VERSION ""

NS_ :

BS_:

BU_: APIM_CISM FCIMB RACM_RCIM DSP WCM DACMC HUD_ADV TRM_ITRM ACM GWM _delete APIM IPC GENERIC TSTR

BO_ 531 DesiredTorqBrk_HS3: 8 GWM
 SG_ VehStop_D_Stat : 28|2@0+ (1,0) [0|3] "SED"  GENERIC
 SG_ TracCtlPtActv_B_Actl : 31|1@0+ (1,0) [0|1] "SED"  GENERIC
 SG_ PrkBrkYwLamp_D_Rq : 38|2@0+ (1,0) [0|3] "SED"  IPC
 SG_ PrkBrkRedLamp_D_Rq : 30|2@0+ (1,0) [0|3] "SED"  IPC
 SG_ PrkBrkMsgTxt_D_Rq : 36|4@0+ (1,0) [0|15] "SED"  IPC
 SG_ PrkBrkStatus : 26|3@0+ (1,0) [0|7] "SED"  APIM_CISM,APIM
 SG_ LscmbbMntr_B_Err : 17|1@0+ (1,0) [0|1] "SED"  APIM,APIM_CISM,IPC
 SG_ LscmbbBrkDis_B_Actl : 19|1@0+ (1,0) [0|1] "SED"  GENERIC
 SG_ StabCtlBrkActv_B_Actl : 23|1@0+ (1,0) [0|1] "SED"  APIM_CISM,APIM
 SG_ CmbbBrkPrchg_B_Actl : 59|1@0+ (1,0) [0|1] "SED"  TRM_ITRM
 SG_ CmbbBrkDecel_B_Actl : 58|1@0+ (1,0) [0|1] "SED"  TRM_ITRM
 SG_ CmbbBaSensInc_B_Actl : 57|1@0+ (1,0) [0|1] "SED"  GENERIC
 SG_ AccBrkWarm_B_Actl : 63|1@0+ (1,0) [0|1] "SED"  GENERIC
 SG_ AccBrkTotTqMn_B_Actl : 62|1@0+ (1,0) [0|1] "SED"  TRM_ITRM
 SG_ AccBrkPrchgActv_B_Actl : 61|1@0+ (1,0) [0|1] "SED"  GENERIC
 SG_ AccBrkDis_B_Actl : 44|1@0+ (1,0) [0|1] "SED"  GENERIC
 SG_ AccBrkDeny_B_Actl : 42|1@0+ (1,0) [0|1] "SED"  GENERIC
 SG_ AccBrkActv_B_Actl : 43|1@0+ (1,0) [0|1] "SED"  GENERIC
 SG_ PrplDrgCtlActv_B_Actl : 46|1@0+ (1,0) [0|1] "SED"  GENERIC
 SG_ PrplWhlTot_Tq_RqMx : 7|16@0+ (4,-131072) [-131072|131068] "Nm"  GENERIC
 SG_ AbsActv_B_Actl : 45|1@0+ (1,0) [0|1] "SED"  APIM_CISM,APIM,TRM_ITRM
 SG_ CmbbBrkDis_B_Actl : 56|1@0+ (1,0) [0|1] "SED"  GENERIC
 SG_ CmbbDeny_B_ActlBrk : 60|1@0+ (1,0) [0|1] "SED"  GENERIC
 SG_ CcDis_B_Cmd : 47|1@0+ (1,0) [0|1] "SED"  GENERIC
 SG_ VehLongOvrGnd_A_Est : 41|10@0+ (0.035,-17.9) [-17.9|17.835] "m/s^2"  TRM_ITRM
 SG_ AccStopActv_B_ActlBrk : 22|1@0+ (1,0) [0|1] "SED"  GENERIC
 SG_ AccDis_B_ActlEpb : 32|1@0+ (1,0) [0|1] "SED"  GENERIC
 SG_ LscmbbDeny_B_ActlBrk : 18|1@0+ (1,0) [0|1] "SED"  GENERIC
 SG_ LscmbbBrkDecel_B_Actl : 20|1@0+ (1,0) [0|1] "SED"  GENERIC
 SG_ LscmbbBaSensInc_B_Actl : 21|1@0+ (1,0) [0|1] "SED"  GENERIC
 SG_ LscmbBrkPrchg_B_Actl : 16|1@0+ (1,0) [0|1] "SED"  GENERIC
 SG_ VehicleStationary : 39|1@0+ (1,0) [0|1] "SED"  GENERIC

BO_ 702 PHONE_MC_WORD_Rx: 8 IPC
 SG_ PHONE_MC_WORD_Rx : 7|64@0+ (1,0) [0|1.84467440737096E+019] "unitless"  APIM_CISM,APIM

BO_ 711 MyKeySrvr_MyKeyClient_Word: 8 IPC
 SG_ MyKeySrvr_Clnt_Word_Tx : 7|64@0+ (1,0) [0|1.84467440737096E+019] "unitless"  APIM_CISM,APIM

BO_ 549 IPC_Infotainment: 8 IPC
 SG_ CCOI_PolicyClient_St2 : 45|4@0+ (1,0) [0|15] "SED"  GWM
 SG_ FactoryReset_Rq2 : 18|1@0+ (1,0) [0|1] "SED"  GWM
 SG_ NavIod_D_Rq : 55|3@0+ (1,0) [0|7] "SED"  APIM_CISM
 SG_ WwaActv_B_Stat : 46|1@0+ (1,0) [0|1] "SED"  APIM_CISM,GWM,ACM,APIM
 SG_ StrtInGearOk_D_Stat : 17|2@0+ (1,0) [0|3] "SED"  GWM
 SG_ Veh_V2_Dsply : 39|9@0+ (1,0) [0|511] "unitless"  APIM_CISM,APIM,GWM,HUD_ADV
 SG_ IPC_MyKeyVolLimit_St : 9|2@0+ (1,0) [0|3] "SED"  APIM_CISM,GWM,APIM,DSP,ACM
 SG_ HudVertSzMnuOn_B_Rq : 21|1@0+ (1,0) [0|1] "SED"  GWM,HUD_ADV
 SG_ HudVertMnuOn_B_Rq : 11|1@0+ (1,0) [0|1] "SED"  GWM,HUD_ADV
 SG_ HudRotatMnuOn_B_Rq : 22|1@0+ (1,0) [0|1] "SED"  GWM,HUD_ADV
 SG_ HudCntntMnuOn_B_Rq : 20|1@0+ (1,0) [0|1] "SED"  GWM,HUD_ADV
 SG_ HudBrightMnuOn_B_Rq : 1|1@0+ (1,0) [0|1] "SED"  GWM,HUD_ADV
 SG_ HdcOn_B_Rq : 19|1@0+ (1,0) [0|1] "SED"  GWM
 SG_ IPC_Attn_Info_Audio : 4|3@0+ (1,0) [0|7] "SED"  APIM_CISM,GWM,APIM,DSP,ACM
 SG_ BeltminderAudioMute : 6|2@0+ (1,0) [0|3] "SED"  APIM_CISM,GWM,APIM,DSP,ACM
 SG_ Power_Up_Chime_Modules : 23|1@0+ (1,0) [0|1] "SED"  APIM_CISM,GWM,DSP,ACM
 SG_ Chime_Source : 15|2@0+ (1,0) [0|3] "SED"  APIM_CISM,GWM,DSP,ACM
 SG_ IPC_New_Attn_Event : 0|1@0+ (1,0) [0|1] "SED"  APIM_CISM,GWM,APIM,DSP,ACM
 SG_ MetricActv_B_Dsply : 7|1@0+ (1,0) [0|1] "SED"  GWM,HUD_ADV,GENERIC

BO_ 765 Mc_Send_Signals_2: 8 IPC
 SG_ BalrSwtch_D_Stat : 57|2@0+ (1,0) [0|3] "SED"  GWM
 SG_ BalrMde_D_Rq : 59|2@0+ (1,0) [0|3] "SED"  GWM
 SG_ RstrnOnPsngr_D_RqMnu : 63|4@0+ (1,0) [0|15] "SED"  GWM
 SG_ WaitToStartLamp_D_Falt : 50|2@0+ (1,0) [0|3] "SED"  GWM
 SG_ EsaOn_B_Rq : 15|1@0+ (1,0) [0|1] "SED"  GWM
 SG_ BttOn_B_Rq : 26|1@0+ (1,0) [0|1] "SED"  GWM
 SG_ Btt_L_Actl : 39|7@0+ (0.1,0) [0|12.5] "meter"  GWM
 SG_ RearDiffLck_D_RqArb : 25|2@0+ (1,0) [0|3] "SED"  GWM
 SG_ AwdMde_D_RqArb : 47|3@0+ (1,0) [0|7] "SED"  GWM
 SG_ SelDrvMdeTxtReset_B_Rq : 40|1@0+ (1,0) [0|1] "SED"  GWM
 SG_ AutoTowAllw_D_RqMnu : 52|2@0+ (1,0) [0|3] "SED"  GWM
 SG_ DrvInputRequired_B_Rq : 32|1@0+ (1,0) [0|1] "SED"  GWM
 SG_ SelDrvMdeDsply_B_Avail : 41|1@0+ (1,0) [0|1] "SED"  GWM
 SG_ EngExhMdeQuiet_D_Rq : 17|2@0+ (1,0) [0|3] "SED"  GWM
 SG_ AirSusp_D_RqDrv : 31|2@0+ (1,0) [0|3] "SED"  GWM
 SG_ Mc_VehUntTrpCoUsrSel_St : 23|1@0+ (1,0) [0|1] "SED"  APIM_CISM,HUD_ADV,APIM,GWM
 SG_ Mc_VehUnitTempUsrSel_St : 22|1@0+ (1,0) [0|1] "SED"  APIM_CISM,HUD_ADV,APIM,RACM_RCIM,GWM
 SG_ Mc_VehDayNightUsrSel_St : 14|3@0+ (1,0) [0|7] "SED"  APIM_CISM,GWM,APIM,ACM
 SG_ Mc_VehTimeFrmtUsrSel_St : 1|2@0+ (1,0) [0|3] "SED"  APIM_CISM,GWM,HUD_ADV,APIM,RACM_RCIM,GENERIC
 SG_ Mc_VehThemeUsrSel_St : 11|4@0+ (1,0) [0|15] "SED"  APIM_CISM,GWM,APIM,GENERIC
 SG_ Mc_VehLangUsrSel_St : 7|6@0+ (1,0) [0|63] "SED"  APIM_CISM,HUD_ADV,APIM,ACM,GWM
 SG_ AwdRnge_D_ActlIpc : 29|3@0+ (1,0) [0|7] "SED"  GWM
 SG_ AwdDrvMde_D_Rq : 44|3@0+ (1,0) [0|7] "SED"  GWM
 SG_ EngExhMdeQuiet_D2_Rq : 55|3@0+ (1,0) [0|7] "SED"  GWM
 SG_ BrkLineLck_D_Rq : 19|2@0+ (1,0) [0|3] "SED"  GWM
 SG_ EdmSailMde_B_RqDrv : 48|1@0+ (1,0) [0|1] "SED"  GWM
 SG_ Running_Board_Cmd : 21|2@0+ (1,0) [0|3] "SED"  GWM

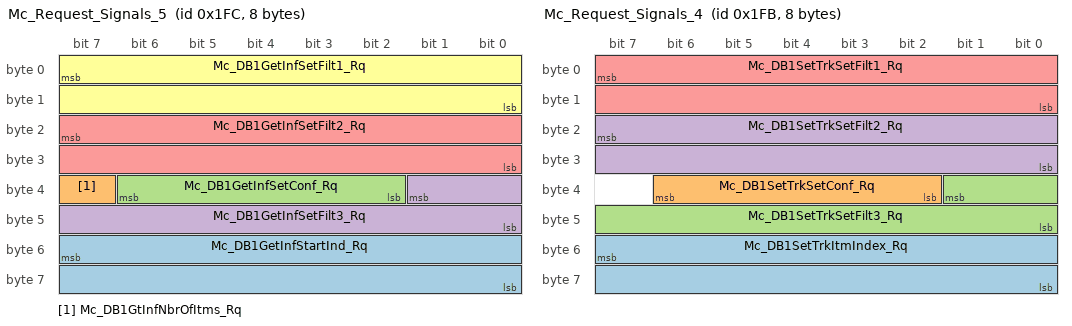
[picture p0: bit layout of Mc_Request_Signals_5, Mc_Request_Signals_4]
BO_ 508 Mc_Request_Signals_5: 8 IPC
 SG_ Mc_DB1GetInfStartInd_Rq : 55|16@0+ (1,0) [0|65535] "unitless"  ACM,APIM_CISM
 SG_ Mc_DB1GtInfNbrOfItms_Rq : 39|1@0+ (1,0) [0|1] "SED"  ACM,APIM_CISM
 SG_ Mc_DB1GetInfSetConf_Rq : 38|5@0+ (1,0) [0|31] "SED"  ACM,APIM_CISM
 SG_ Mc_DB1GetInfSetFilt3_Rq : 33|10@0+ (1,0) [0|1023] "unitless"  ACM,APIM_CISM
 SG_ Mc_DB1GetInfSetFilt2_Rq : 23|16@0+ (1,0) [0|65535] "unitless"  ACM,APIM_CISM
 SG_ Mc_DB1GetInfSetFilt1_Rq : 7|16@0+ (1,0) [0|65535] "unitless"  ACM,APIM_CISM

BO_ 507 Mc_Request_Signals_4: 8 IPC
 SG_ Mc_DB1SetTrkItmIndex_Rq : 55|16@0+ (1,0) [0|65535] "unitless"  ACM,APIM_CISM
 SG_ Mc_DB1SetTrkSetConf_Rq : 38|5@0+ (1,0) [0|31] "SED"  ACM,APIM_CISM
 SG_ Mc_DB1SetTrkSetFilt3_Rq : 33|10@0+ (1,0) [0|1023] "unitless"  ACM,APIM_CISM
 SG_ Mc_DB1SetTrkSetFilt2_Rq : 23|16@0+ (1,0) [0|65535] "unitless"  ACM,APIM_CISM
 SG_ Mc_DB1SetTrkSetFilt1_Rq : 7|16@0+ (1,0) [0|65535] "unitless"  ACM,APIM_CISM

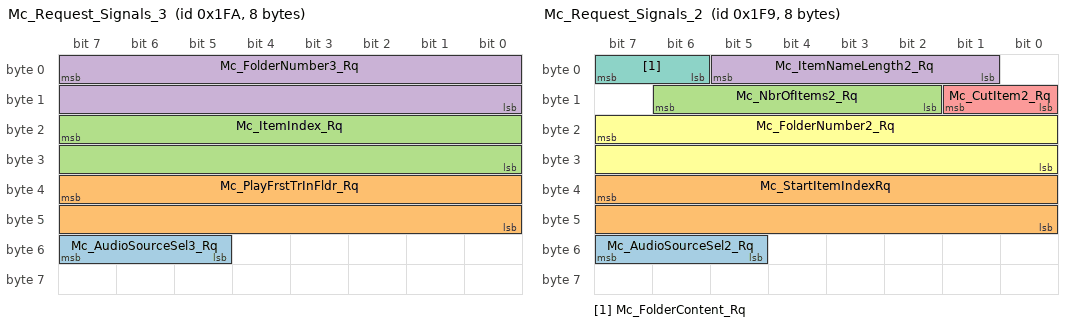
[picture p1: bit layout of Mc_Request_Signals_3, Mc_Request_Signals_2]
BO_ 506 Mc_Request_Signals_3: 8 IPC
 SG_ Mc_AudioSourceSel3_Rq : 55|3@0+ (1,0) [0|7] "SED"  ACM,APIM_CISM
 SG_ Mc_PlayFrstTrInFldr_Rq : 39|16@0+ (1,0) [0|65535] "unitless"  ACM,APIM_CISM
 SG_ Mc_ItemIndex_Rq : 23|16@0+ (1,0) [0|65535] "unitless"  ACM,APIM_CISM
 SG_ Mc_FolderNumber3_Rq : 7|16@0+ (1,0) [0|65535] "unitless"  ACM,APIM_CISM

BO_ 505 Mc_Request_Signals_2: 8 IPC
 SG_ Mc_AudioSourceSel2_Rq : 55|3@0+ (1,0) [0|7] "SED"  ACM,APIM_CISM
 SG_ Mc_StartItemIndexRq : 39|16@0+ (1,0) [0|65535] "unitless"  ACM,APIM_CISM
 SG_ Mc_NbrOfItems2_Rq : 14|5@0+ (1,0) [0|20] "SED"  ACM,APIM_CISM
 SG_ Mc_ItemNameLength2_Rq : 5|5@0+ (1,0) [0|20] "SED"  ACM,APIM_CISM
 SG_ Mc_CutItem2_Rq : 9|2@0+ (1,0) [0|3] "SED"  ACM,APIM_CISM
 SG_ Mc_FolderNumber2_Rq : 23|16@0+ (1,0) [0|65535] "unitless"  ACM,APIM_CISM
 SG_ Mc_FolderContent_Rq : 7|2@0+ (1,0) [0|3] "SED"  ACM,APIM_CISM

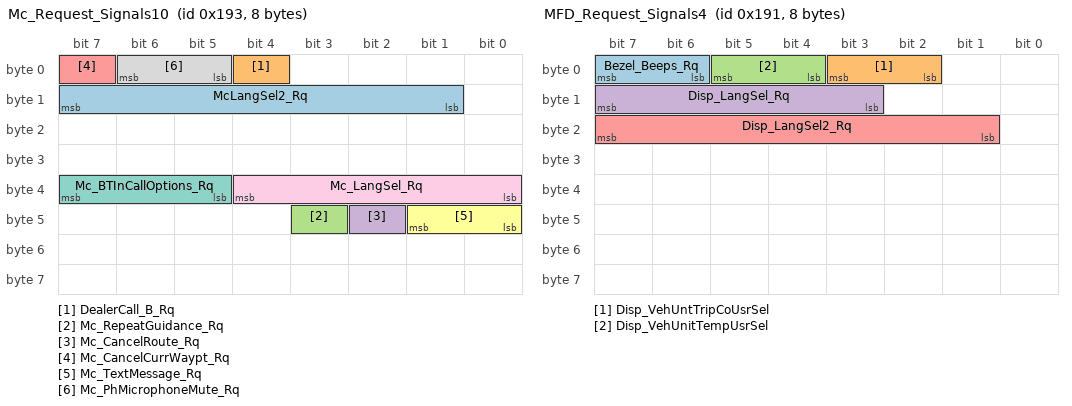
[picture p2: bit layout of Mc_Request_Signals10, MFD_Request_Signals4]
BO_ 403 Mc_Request_Signals10: 8 IPC
 SG_ McLangSel2_Rq : 15|7@0+ (1,0) [0|7] "SED"  APIM_CISM,APIM
 SG_ DealerCall_B_Rq : 4|1@0+ (1,0) [0|1] "SED"  APIM_CISM,APIM
 SG_ Mc_RepeatGuidance_Rq : 43|1@0+ (1,0) [0|1] "SED"  APIM_CISM,APIM
 SG_ Mc_CancelRoute_Rq : 42|1@0+ (1,0) [0|1] "SED"  APIM_CISM,APIM
 SG_ Mc_CancelCurrWaypt_Rq : 7|1@0+ (1,0) [0|1] "SED"  APIM_CISM,APIM
 SG_ Mc_TextMessage_Rq : 41|2@0+ (1,0) [0|3] "SED"  APIM_CISM,APIM
 SG_ Mc_BTInCallOptions_Rq : 39|3@0+ (1,0) [0|7] "SED"  APIM_CISM,APIM
 SG_ Mc_PhMicrophoneMute_Rq : 6|2@0+ (1,0) [0|3] "SED"  APIM_CISM,APIM
 SG_ Mc_LangSel_Rq : 36|5@0+ (1,0) [0|31] "SED"  APIM_CISM,APIM

BO_ 401 MFD_Request_Signals4: 8 APIM
 SG_ Bezel_Beeps_Rq : 7|2@0+ (1,0) [0|3] "SED"  FCIMB,GWM
 SG_ Disp_VehUntTripCoUsrSel : 3|2@0+ (1,0) [0|3] "SED"  IPC
 SG_ Disp_VehUnitTempUsrSel : 5|2@0+ (1,0) [0|3] "SED"  IPC
 SG_ Disp_LangSel_Rq : 15|5@0+ (1,0) [0|31] "SED"  IPC
 SG_ Disp_LangSel2_Rq : 23|7@0+ (1,0) [0|127] "SED"  IPC

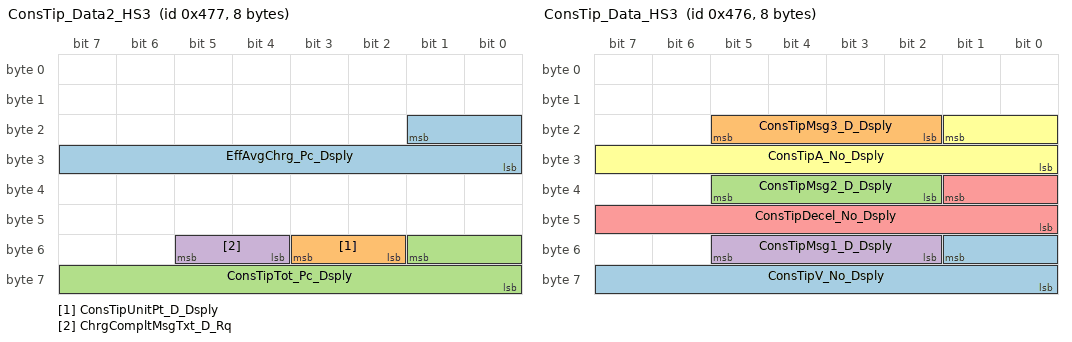
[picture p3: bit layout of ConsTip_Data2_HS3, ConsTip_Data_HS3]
BO_ 1143 ConsTip_Data2_HS3: 8 GWM
 SG_ EffAvgChrg_Pc_Dsply : 17|10@0+ (0.1,0) [0|102.3] "percent"  IPC
 SG_ ConsTipUnitPt_D_Dsply : 51|2@0+ (1,0) [0|3] "SED"  APIM_CISM,IPC,APIM
 SG_ ConsTipTot_Pc_Dsply : 49|10@0+ (0.1,0) [0|102.1] "percent"  IPC
 SG_ ChrgCompltMsgTxt_D_Rq : 53|2@0+ (1,0) [0|3] "SED"  APIM_CISM,APIM,IPC

BO_ 1142 ConsTip_Data_HS3: 8 GWM
 SG_ ConsTipV_No_Dsply : 49|10@0+ (0.1,0) [0|102.1] "percent"  APIM_CISM,IPC,APIM
 SG_ ConsTipMsg3_D_Dsply : 21|4@0+ (1,0) [0|15] "SED"  APIM_CISM,IPC,APIM
 SG_ ConsTipMsg2_D_Dsply : 37|4@0+ (1,0) [0|15] "SED"  APIM_CISM,IPC,APIM
 SG_ ConsTipMsg1_D_Dsply : 53|4@0+ (1,0) [0|15] "SED"  APIM_CISM,IPC,APIM
 SG_ ConsTipDecel_No_Dsply : 33|10@0+ (0.1,0) [0|102.1] "percent"  APIM_CISM,IPC,APIM
 SG_ ConsTipA_No_Dsply : 17|10@0+ (0.1,0) [0|102.1] "percent"  APIM_CISM,IPC,APIM

BO_ 947 OutsideAirTempStat: 8 GWM
 SG_ Outside_Air_Temp_Stat_UB : 48|1@0+ (1,0) [0|1] "SED"  HUD_ADV,APIM_CISM,APIM,WCM,IPC
 SG_ Outside_Air_Temp_Stat : 39|8@0+ (0.5,-40) [-40|86.5] "Degrees C"  HUD_ADV,APIM_CISM,APIM,WCM,IPC

BO_ 973 Traffic_RecogitionData_HS3: 8 GWM
 SG_ PersCtaSplitView_D_Stat : 12|2@0+ (1,0) [0|3] "SED"  APIM
 SG_ LaSysOffStat_D_Dsply : 58|2@0+ (1,0) [0|3] "SED"  IPC
 SG_ TsrVl1RstrcMsgTxt2_D_Rq : 51|3@0+ (1,0) [0|7] "SED"  HUD_ADV,IPC
 SG_ TsrVl2RstrcMsgTxt2_D_Rq : 63|3@0+ (1,0) [0|7] "SED"  HUD_ADV,IPC
 SG_ TsrVl2PrmntMsgTxt_D_Rq : 60|2@0+ (1,0) [0|3] "SED"  HUD_ADV,IPC
 SG_ TsrVl1PrmntMsgTxt_D_Rq : 41|2@0+ (1,0) [0|3] "SED"  HUD_ADV,IPC
 SG_ TsrOvtkMsgTxt2_D_Rq : 55|4@0+ (1,0) [0|15] "SED"  HUD_ADV,IPC
 SG_ WwaWarn_B_Rq : 48|1@0+ (1,0) [0|1] "SED"  HUD_ADV,IPC
 SG_ TsrVlUnitMsgTxt_D_Rq : 43|2@0+ (1,0) [0|3] "SED"  APIM_CISM,HUD_ADV,APIM,IPC
 SG_ TsrVLim2MsgTxt_D_Rq : 39|8@0+ (1,0) [0|255] "SED"  HUD_ADV,IPC
 SG_ TsrVLim1MsgTxt_D_Rq : 31|8@0+ (1,0) [0|255] "SED"  HUD_ADV,IPC
 SG_ TsrVl2StatMsgTxt_D_Rq : 47|2@0+ (1,0) [0|3] "SED"  HUD_ADV,IPC
 SG_ TsrVl2RstrcMsgTxt_D_Rq : 17|2@0+ (1,0) [0|3] "SED"  HUD_ADV,IPC
 SG_ TsrVl1StatMsgTxt_D_Rq : 21|2@0+ (1,0) [0|3] "SED"  HUD_ADV,IPC
 SG_ TsrVl1RstrcMsgTxt_D_Rq : 23|2@0+ (1,0) [0|3] "SED"  IPC
 SG_ TsrStatMsgTxt_D_Rq : 10|3@0+ (1,0) [0|7] "SED"  IPC
 SG_ TsrOvtkStatMsgTxt_D_Rq : 1|2@0+ (1,0) [0|3] "SED"  HUD_ADV,IPC
 SG_ TsrOvtkMsgTxt_D_Rq : 15|3@0+ (1,0) [0|7] "SED"  HUD_ADV,IPC
 SG_ TsrOswWarnMsgTxt_D_Rq : 3|2@0+ (1,0) [0|3] "SED"  HUD_ADV,IPC
 SG_ TsrMsgTxt_D_Rq : 7|4@0+ (1,0) [0|15] "SED"  IPC

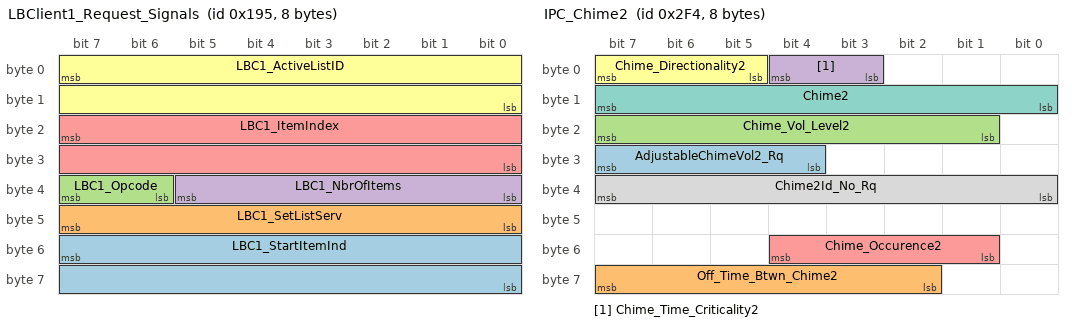
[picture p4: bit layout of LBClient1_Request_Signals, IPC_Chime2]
BO_ 405 LBClient1_Request_Signals: 8 IPC
 SG_ LBC1_StartItemInd : 55|16@0+ (1,0) [0|65535] "unitless"  APIM_CISM,ACM,APIM
 SG_ LBC1_SetListServ : 47|8@0+ (1,0) [0|255] "unitless"  APIM_CISM,ACM,APIM
 SG_ LBC1_Opcode : 39|2@0+ (1,0) [0|3] "SED"  APIM_CISM,ACM,APIM
 SG_ LBC1_NbrOfItems : 37|6@0+ (1,0) [0|63] "unitless"  APIM_CISM,ACM,APIM
 SG_ LBC1_ItemIndex : 23|16@0+ (1,0) [0|65535] "unitless"  APIM_CISM,ACM,APIM
 SG_ LBC1_ActiveListID : 7|16@0+ (1,0) [0|65535] "unitless"  APIM_CISM,APIM,ACM

BO_ 756 IPC_Chime2: 8 IPC
 SG_ AdjustableChimeVol2_Rq : 31|4@0+ (1,0) [0|15] "SED"  APIM_CISM,ACM,DSP
 SG_ Off_Time_Btwn_Chime2 : 63|6@0+ (1,0) [0|52] "unitless"  APIM_CISM,ACM,DSP
 SG_ Chime_Vol_Level2 : 23|7@0+ (1,0) [0|127] "unitless"  APIM_CISM,ACM,DSP
 SG_ Chime_Time_Criticality2 : 4|2@0+ (1,0) [0|3] "SED"  APIM_CISM,ACM,DSP
 SG_ Chime_Occurence2 : 52|4@0+ (1,0) [0|15] "SED"  APIM_CISM,ACM,DSP
 SG_ Chime_Directionality2 : 7|3@0+ (1,0) [0|7] "SED"  APIM_CISM,ACM,DSP
 SG_ Chime2 : 15|8@0+ (1,0) [0|255] "unitless"  APIM_CISM,ACM,DSP
 SG_ Chime2Id_No_Rq : 39|8@0+ (1,0) [0|255] "SED"  APIM_CISM,DSP,ACM

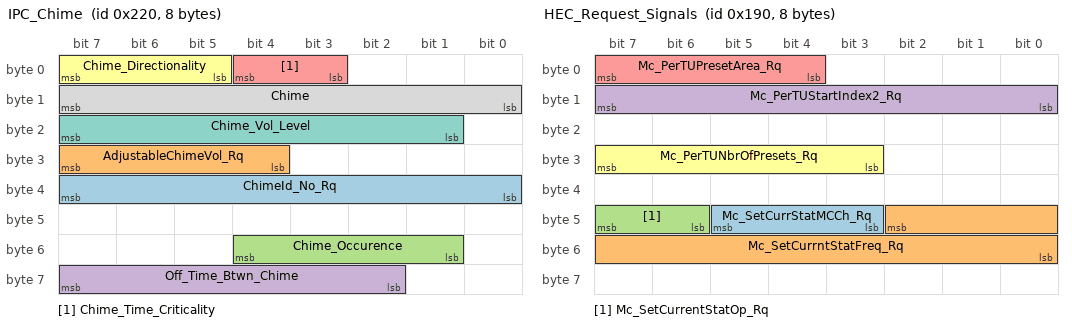
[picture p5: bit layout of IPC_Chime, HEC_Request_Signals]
BO_ 544 IPC_Chime: 8 IPC
 SG_ ChimeId_No_Rq : 39|8@0+ (1,0) [0|255] "SED"  APIM_CISM,ACM
 SG_ AdjustableChimeVol_Rq : 31|4@0+ (1,0) [0|15] "SED"  APIM_CISM,ACM,DSP
 SG_ Chime_Occurence : 52|4@0+ (1,0) [0|15] "SED"  APIM_CISM,DSP,ACM
 SG_ Off_Time_Btwn_Chime : 63|6@0+ (1,0) [0|52] "unitless"  APIM_CISM,DSP,ACM
 SG_ Chime_Time_Criticality : 4|2@0+ (1,0) [0|3] "SED"  APIM_CISM,DSP,ACM
 SG_ Chime_Directionality : 7|3@0+ (1,0) [0|7] "SED"  APIM_CISM,DSP,ACM
 SG_ Chime_Vol_Level : 23|7@0+ (1,0) [0|127] "unitless"  APIM_CISM,DSP,ACM
 SG_ Chime : 15|8@0+ (1,0) [0|255] "unitless"  APIM_CISM,DSP,ACM

BO_ 291 HEC_Response_Signals: 8 IPC
 SG_ LangUpdate_Rsp : 7|2@0+ (1,0) [0|3] "SED"  APIM_CISM,APIM

BO_ 400 HEC_Request_Signals: 8 IPC
 SG_ Mc_SetCurrStatMCCh_Rq : 45|3@0+ (1,0) [0|7] "SED"  ACM,APIM_CISM
 SG_ Mc_SetCurrntStatFreq_Rq : 42|11@0+ (1,0) [0|1557] "unitless"  ACM,APIM_CISM
 SG_ Mc_SetCurrentStatOp_Rq : 47|2@0+ (1,0) [0|3] "SED"  ACM,APIM_CISM
 SG_ Mc_PerTUStartIndex2_Rq : 15|8@0+ (1,0) [0|255] "unitless"  ACM,APIM_CISM,APIM
 SG_ Mc_PerTUPresetArea_Rq : 7|4@0+ (1,0) [0|15] "SED"  ACM,APIM_CISM,APIM
 SG_ Mc_PerTUNbrOfPresets_Rq : 31|5@0+ (1,0) [0|31] "SED"  ACM,APIM_CISM,APIM

BO_ 647 HEC_DispDimm: 8 IPC
 SG_ HEC_BTIncomingCall_Rq : 23|2@0+ (1,0) [0|3] "SED"  APIM_CISM,APIM
 SG_ HEC_BTEndTelService_Rq : 3|2@0+ (1,0) [0|3] "SED"  APIM_CISM,APIM

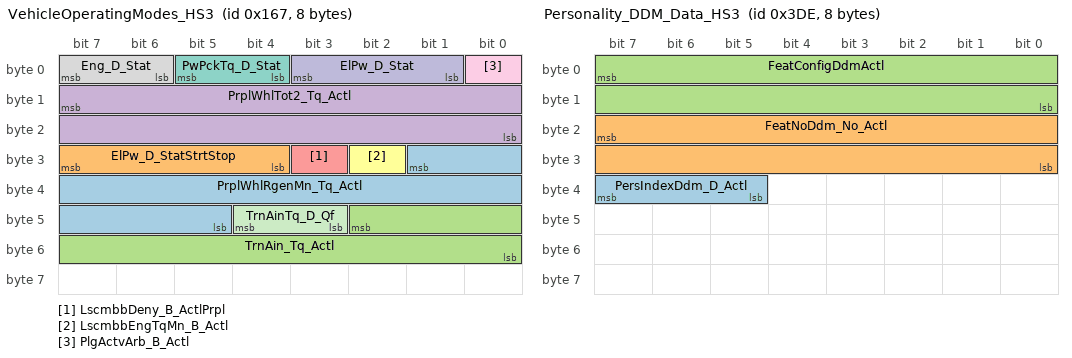
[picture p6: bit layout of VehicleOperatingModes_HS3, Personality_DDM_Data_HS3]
BO_ 359 VehicleOperatingModes_HS3: 8 GWM
 SG_ PrplWhlRgenMn_Tq_Actl : 25|13@0+ (4,-16380) [-16380|16380] "Nm"  GENERIC
 SG_ ElPw_D_StatStrtStop : 31|4@0+ (1,0) [0|15] "SED"  GENERIC
 SG_ TrnAin_Tq_Actl : 42|11@0+ (1,-500) [-500|1547] "Nm"  APIM_CISM,DACMC,IPC,APIM,ACM
 SG_ PrplWhlTot2_Tq_Actl : 15|16@0+ (4,-131072) [-131072|131060] "Nm"  APIM_CISM,APIM,IPC
 SG_ LscmbbDeny_B_ActlPrpl : 27|1@0+ (1,0) [0|1] "SED"  GENERIC
 SG_ LscmbbEngTqMn_B_Actl : 26|1@0+ (1,0) [0|1] "SED"  GENERIC
 SG_ PwPckTq_D_Stat : 5|2@0+ (1,0) [0|3] "SED"  HUD_ADV,APIM_CISM,RACM_RCIM,TRM_ITRM,DACMC,APIM,DSP,ACM,WCM,IPC
 SG_ Eng_D_Stat : 7|2@0+ (1,0) [0|3] "SED"  APIM_CISM,RACM_RCIM,TRM_ITRM,APIM,WCM,DSP,ACM
 SG_ PlgActvArb_B_Actl : 0|1@0+ (1,0) [0|1] "SED"  IPC
 SG_ ElPw_D_Stat : 3|3@0+ (1,0) [0|7] "SED"  APIM_CISM,RACM_RCIM,DSP,TRM_ITRM,DACMC,HUD_ADV,APIM,ACM,IPC
 SG_ TrnAinTq_D_Qf : 44|2@0+ (1,0) [0|3] "SED"  APIM_CISM,DACMC,ACM

BO_ 990 Personality_DDM_Data_HS3: 8 GWM
 SG_ PersIndexDdm_D_Actl : 39|3@0+ (1,0) [0|7] "SED"  APIM_CISM,APIM,IPC
 SG_ FeatNoDdm_No_Actl : 23|16@0+ (1,0) [0|65535] "Number"  APIM_CISM,APIM,IPC
 SG_ FeatConfigDdmActl : 7|16@0+ (1,0) [0|65535] "Undefined"  APIM_CISM,APIM,IPC

BO_ 989 Personality_HCM_Data_HS3: 8 GWM
 SG_ FeatNoHcm_No_Actl : 23|16@0+ (1,0) [0|65535] "Number"  APIM_CISM,APIM,IPC
 SG_ FeatConfigHcmActl : 7|16@0+ (1,0) [0|65535] "Undefined"  APIM_CISM,APIM,IPC

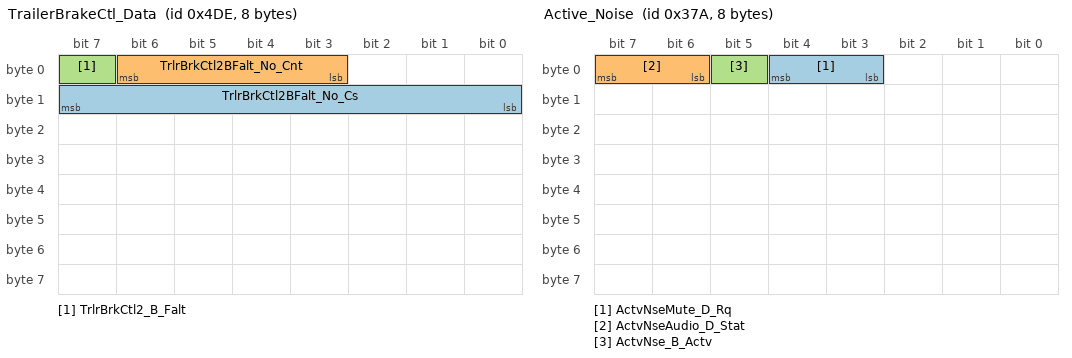
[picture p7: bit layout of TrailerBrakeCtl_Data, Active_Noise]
BO_ 1246 TrailerBrakeCtl_Data: 8 TRM_ITRM
 SG_ TrlrBrkCtl2BFalt_No_Cs : 15|8@0+ (1,0) [0|255] "Unitless"  IPC
 SG_ TrlrBrkCtl2BFalt_No_Cnt : 6|4@0+ (1,0) [0|15] "Unitless"  IPC
 SG_ TrlrBrkCtl2_B_Falt : 7|1@0+ (1,0) [0|1] "SED"  IPC

BO_ 890 Active_Noise: 8 DACMC
 SG_ ActvNseMute_D_Rq : 4|2@0+ (1,0) [0|3] "SED"  DSP
 SG_ ActvNseAudio_D_Stat : 7|2@0+ (1,0) [0|3] "SED"  DACMC,DSP
 SG_ ActvNse_B_Actv : 5|1@0+ (1,0) [0|1] "SED"  DACMC,DSP

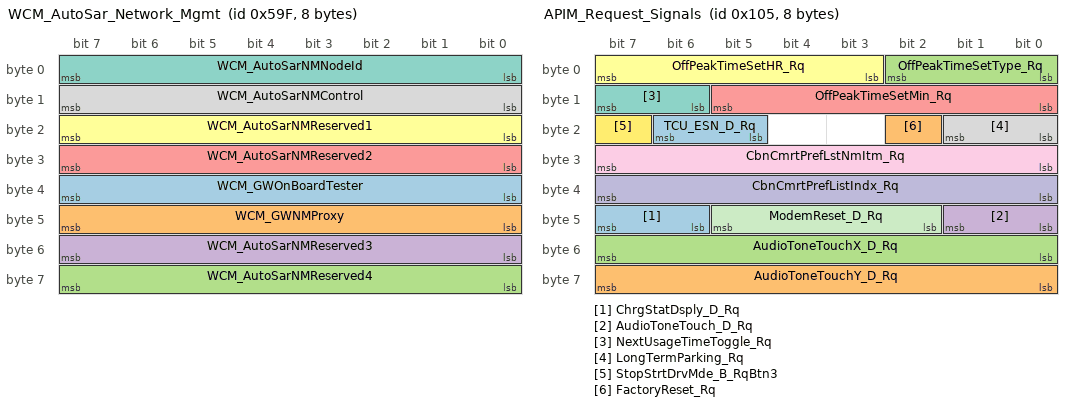
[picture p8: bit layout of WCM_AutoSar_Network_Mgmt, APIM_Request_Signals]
BO_ 1439 WCM_AutoSar_Network_Mgmt: 8 WCM
 SG_ WCM_GWOnBoardTester : 39|8@0+ (1,0) [0|255] "unitless"  HUD_ADV
 SG_ WCM_GWNMProxy : 47|8@0+ (1,0) [0|255] "unitless"  HUD_ADV
 SG_ WCM_AutoSarNMReserved4 : 63|8@0+ (1,0) [0|255] "unitless"  HUD_ADV
 SG_ WCM_AutoSarNMReserved3 : 55|8@0+ (1,0) [0|255] "unitless"  HUD_ADV
 SG_ WCM_AutoSarNMReserved2 : 31|8@0+ (1,0) [0|255] "unitless"  HUD_ADV
 SG_ WCM_AutoSarNMReserved1 : 23|8@0+ (1,0) [0|255] "unitless"  HUD_ADV
 SG_ WCM_AutoSarNMNodeId : 7|8@0+ (1,0) [0|255] "unitless"  HUD_ADV
 SG_ WCM_AutoSarNMControl : 15|8@0+ (1,0) [0|255] "unitless"  HUD_ADV

BO_ 261 APIM_Request_Signals: 8 ACM
 SG_ ChrgStatDsply_D_Rq : 47|2@0+ (1,0) [0|3] "SED"  GWM
 SG_ AudioToneTouchY_D_Rq : 63|8@0+ (1,0) [0|255] "SED"  DSP
 SG_ AudioToneTouchX_D_Rq : 55|8@0+ (1,0) [0|255] "SED"  DSP
 SG_ AudioToneTouch_D_Rq : 41|2@0+ (1,0) [0|3] "SED"  DSP
 SG_ OffPeakTimeSetMin_Rq : 13|6@0+ (1,0) [0|63] "unitless"  GWM
 SG_ OffPeakTimeSetHR_Rq : 7|5@0+ (1,0) [0|31] "unitless"  GWM
 SG_ NextUsageTimeToggle_Rq : 15|2@0+ (1,0) [0|3] "SED"  GWM
 SG_ LongTermParking_Rq : 17|2@0+ (1,0) [0|3] "SED"  GWM
 SG_ CbnCmrtPrefLstNmItm_Rq : 31|8@0+ (1,0) [0|255] "unitless"  GWM
 SG_ CbnCmrtPrefListIndx_Rq : 39|8@0+ (1,0) [0|255] "unitless"  GWM
 SG_ ModemReset_D_Rq : 45|4@0+ (1,0) [0|15] "SED"  GWM
 SG_ StopStrtDrvMde_B_RqBtn3 : 23|1@0+ (1,0) [0|1] "SED"  GWM
 SG_ TCU_ESN_D_Rq : 22|2@0+ (1,0) [0|3] "SED"  GWM
 SG_ FactoryReset_Rq : 18|1@0+ (1,0) [0|1] "SED"  GWM
 SG_ OffPeakTimeSetType_Rq : 2|3@0+ (1,0) [0|7] "SED"  GWM

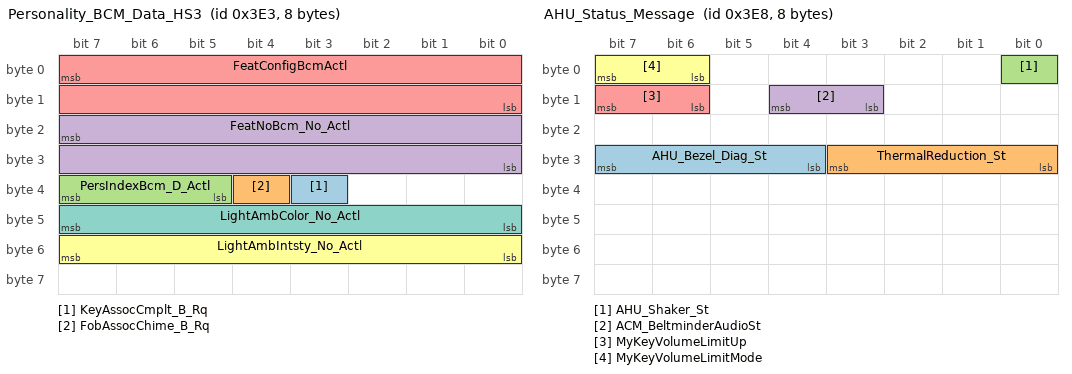
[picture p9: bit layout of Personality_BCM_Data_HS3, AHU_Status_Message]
BO_ 995 Personality_BCM_Data_HS3: 8 GWM
 SG_ KeyAssocCmplt_B_Rq : 35|1@0+ (1,0) [0|1] "SED"  IPC
 SG_ FobAssocChime_B_Rq : 36|1@0+ (1,0) [0|1] "SED"  IPC
 SG_ PersIndexBcm_D_Actl : 39|3@0+ (1,0) [0|7] "SED"  APIM_CISM,APIM,IPC
 SG_ FeatNoBcm_No_Actl : 23|16@0+ (1,0) [0|65535] "Number"  APIM_CISM,APIM,IPC
 SG_ FeatConfigBcmActl : 7|16@0+ (1,0) [0|65535] "Undefined"  APIM_CISM,APIM,IPC
 SG_ LightAmbIntsty_No_Actl : 55|8@0+ (1,0) [0|255] "unitless"  APIM_CISM,APIM
 SG_ LightAmbColor_No_Actl : 47|8@0+ (1,0) [0|255] "Discrete"  APIM_CISM,APIM

BO_ 753 Vehicle_Stat: 8 APIM
 SG_ RollCodeValet : 7|16@0+ (1,0) [0|65535] "Unitless"  GWM

BO_ 1000 AHU_Status_Message: 8 ACM
 SG_ AHU_Bezel_Diag_St : 31|4@0+ (1,0) [0|15] "SED"  APIM
 SG_ ThermalReduction_St : 27|4@0+ (1,0) [0|15] "SED"  DSP
 SG_ AHU_Shaker_St : 0|1@0+ (1,0) [0|1] "SED"  APIM
 SG_ ACM_BeltminderAudioSt : 12|2@0+ (1,0) [0|3] "SED"  APIM
 SG_ MyKeyVolumeLimitUp : 15|2@0+ (1,0) [0|3] "SED"  APIM
 SG_ MyKeyVolumeLimitMode : 7|2@0+ (1,0) [0|3] "SED"  APIM

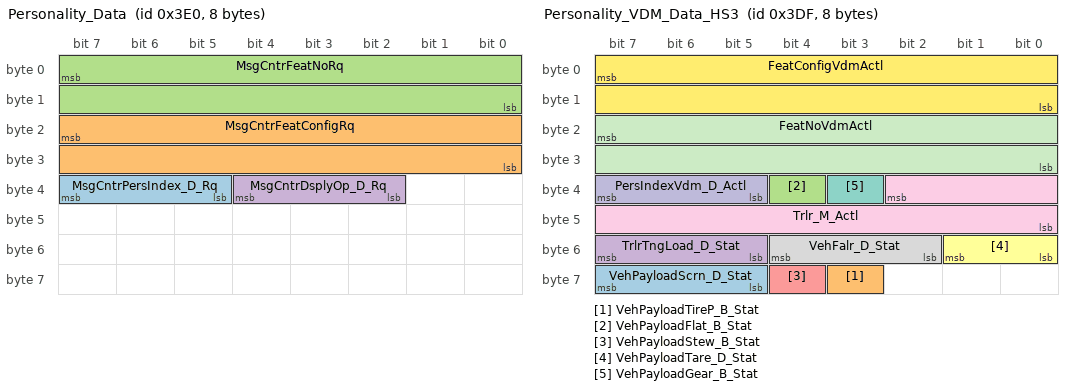
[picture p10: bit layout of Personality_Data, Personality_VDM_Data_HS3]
BO_ 992 Personality_Data: 8 IPC
 SG_ MsgCntrPersIndex_D_Rq : 39|3@0+ (1,0) [0|7] "SED"  HUD_ADV,GWM
 SG_ MsgCntrFeatConfigRq : 23|16@0+ (1,0) [0|65535] "unitless"  HUD_ADV,GWM
 SG_ MsgCntrFeatNoRq : 7|16@0+ (1,0) [0|65535] "Number"  HUD_ADV,GWM
 SG_ MsgCntrDsplyOp_D_Rq : 36|3@0+ (1,0) [0|7] "SED"  HUD_ADV,GWM

BO_ 991 Personality_VDM_Data_HS3: 8 GWM
 SG_ VehPayloadScrn_D_Stat : 63|3@0+ (1,0) [0|7] "SED"  APIM,APIM_CISM
 SG_ VehPayloadTireP_B_Stat : 59|1@0+ (1,0) [0|1] "SED"  APIM,APIM_CISM
 SG_ VehPayloadFlat_B_Stat : 36|1@0+ (1,0) [0|1] "SED"  APIM,APIM_CISM
 SG_ TrlrTngLoad_D_Stat : 55|3@0+ (1,0) [0|7] "SED"  GENERIC
 SG_ VehPayloadStew_B_Stat : 60|1@0+ (1,0) [0|1] "SED"  APIM,APIM_CISM
 SG_ VehPayloadTare_D_Stat : 49|2@0+ (1,0) [0|3] "SED"  APIM,APIM_CISM
 SG_ VehPayloadGear_B_Stat : 35|1@0+ (1,0) [0|1] "SED"  APIM,APIM_CISM
 SG_ VehFalr_D_Stat : 52|3@0+ (1,0) [0|7] "SED"  APIM,APIM_CISM
 SG_ Trlr_M_Actl : 34|11@0+ (10,0) [0|20450] "kilogram"  APIM,APIM_CISM
 SG_ PersIndexVdm_D_Actl : 39|3@0+ (1,0) [0|7] "SED"  APIM_CISM,APIM,IPC
 SG_ FeatNoVdmActl : 23|16@0+ (1,0) [0|65535] "Number"  APIM_CISM,APIM,IPC
 SG_ FeatConfigVdmActl : 7|16@0+ (1,0) [0|65535] "Undefined"  APIM_CISM,APIM,IPC

BO_ 1004 Personality_BCM2_Data_HS3: 8 GWM
 SG_ TailLghtLoadMde_D_Stat : 60|3@0+ (1,0) [0|7] "SED"  APIM,APIM_CISM
 SG_ PersRecallSrc_D_Actl : 63|3@0+ (1,0) [0|7] "SED"  GENERIC
 SG_ Pers4Key_D_Stat : 49|2@0+ (1,0) [0|3] "SED"  APIM_CISM,APIM,GENERIC
 SG_ Pers3Key_D_Stat : 41|2@0+ (1,0) [0|3] "SED"  APIM_CISM,APIM,GENERIC
 SG_ Pers2Key_D_Stat : 43|2@0+ (1,0) [0|3] "SED"  APIM_CISM,APIM,GENERIC
 SG_ Pers1Key_D_Stat : 12|2@0+ (1,0) [0|3] "SED"  APIM_CISM,APIM,GENERIC
 SG_ EmPrflKeyAssoc_D_Stat : 55|3@0+ (1,0) [0|7] "SED"  APIM_CISM,APIM,GENERIC
 SG_ VehKeyActv_D_Stat : 47|4@0+ (1,0) [0|15] "SED"  GENERIC,IPC
 SG_ PersSetupRestr_D_Actl : 21|2@0+ (1,0) [0|3] "SED"  APIM_CISM,APIM,GENERIC
 SG_ PersSetupAccessCtrl : 19|1@0+ (1,0) [0|1] "SED"  APIM_CISM,APIM,GENERIC
 SG_ PersSetup_No_Actl : 31|16@0+ (1,0) [0|65535] "Number"  APIM_CISM,APIM,GENERIC
 SG_ PersConflict_D_Actl : 22|1@0+ (1,0) [0|1] "SED"  APIM_CISM,APIM,GENERIC
 SG_ AssocConfirm_D_Actl : 15|3@0+ (1,0) [0|7] "SED"  APIM_CISM,APIM
 SG_ RecallEvent_No_Cnt : 7|8@0+ (1,0) [0|255] "Counts"  HUD_ADV,APIM_CISM,APIM,IPC,ACM,DSP
 SG_ PersNoPos_D_Actl : 18|3@0+ (1,0) [0|7] "SED"  HUD_ADV,APIM_CISM,APIM,IPC
 SG_ PersNo_D_Actl : 10|3@0+ (1,0) [0|7] "SED"  APIM_CISM,APIM,ACM,IPC,DSP
 SG_ EmPrflNo_D_Stat : 52|3@0+ (1,0) [0|7] "SED"  APIM_CISM,APIM

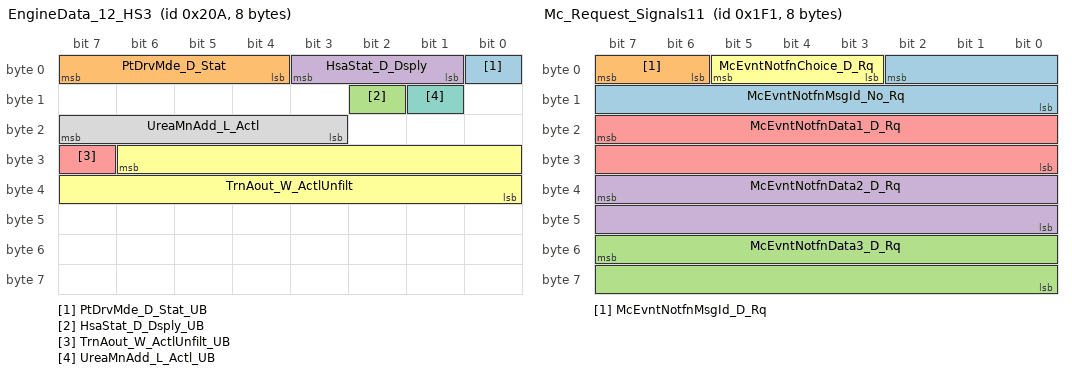
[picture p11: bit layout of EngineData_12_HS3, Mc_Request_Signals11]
BO_ 522 EngineData_12_HS3: 8 GWM
 SG_ PtDrvMde_D_Stat_UB : 0|1@0+ (1,0) [0|1] "SED"  APIM_CISM,DACMC,IPC,ACM
 SG_ PtDrvMde_D_Stat : 7|4@0+ (1,0) [0|15] "SED"  APIM_CISM,DACMC,IPC,ACM
 SG_ HsaStat_D_Dsply_UB : 10|1@0+ (1,0) [0|1] "SED"  IPC
 SG_ HsaStat_D_Dsply : 3|3@0+ (1,0) [0|7] "SED"  IPC
 SG_ TrnAout_W_ActlUnfilt_UB : 31|1@0+ (1,0) [0|1] "SED"  APIM_CISM,ACM
 SG_ TrnAout_W_ActlUnfilt : 30|15@0+ (0.1,0) [0|3276.5] "rad/s"  APIM_CISM,DACMC,ACM
 SG_ UreaMnAdd_L_Actl_UB : 9|1@0+ (1,0) [0|1] "SED"  IPC
 SG_ UreaMnAdd_L_Actl : 23|5@0+ (1,0) [0|31] "litre"  IPC

BO_ 497 Mc_Request_Signals11: 8 IPC
 SG_ McEvntNotfnMsgId_No_Rq : 2|11@0+ (1,0) [0|2047] "unitless"  APIM_CISM,APIM
 SG_ McEvntNotfnMsgId_D_Rq : 7|2@0+ (1,0) [0|3] "SED"  APIM_CISM,APIM
 SG_ McEvntNotfnData3_D_Rq : 55|16@0+ (1,0) [0|65535] "unitless"  APIM_CISM,APIM
 SG_ McEvntNotfnData2_D_Rq : 39|16@0+ (1,0) [0|65535] "unitless"  APIM_CISM,APIM
 SG_ McEvntNotfnData1_D_Rq : 23|16@0+ (1,0) [0|65535] "unitless"  APIM_CISM,APIM
 SG_ McEvntNotfnChoice_D_Rq : 5|3@0+ (1,0) [0|7] "SED"  APIM_CISM,APIM

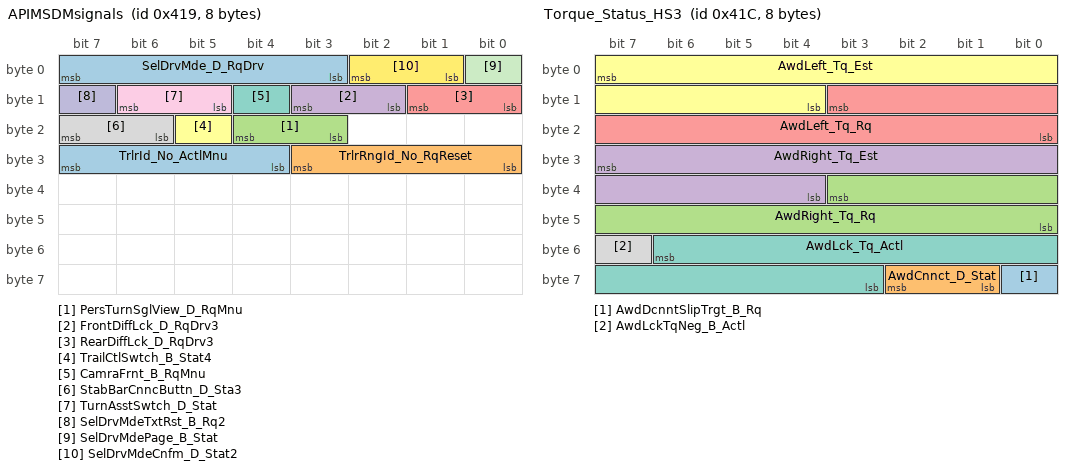
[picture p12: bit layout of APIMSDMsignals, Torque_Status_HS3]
BO_ 1049 APIMSDMsignals: 8 APIM
 SG_ TrlrId_No_ActlMnu : 31|4@0+ (1,0) [0|15] "unitless"  GWM
 SG_ TrlrRngId_No_RqReset : 27|4@0+ (1,0) [0|15] "unitless"  GWM
 SG_ PersTurnSglView_D_RqMnu : 20|2@0+ (1,0) [0|3] "SED"  GWM
 SG_ FrontDiffLck_D_RqDrv3 : 11|2@0+ (1,0) [0|3] "SED"  GWM
 SG_ RearDiffLck_D_RqDrv3 : 9|2@0+ (1,0) [0|3] "SED"  GWM
 SG_ TrailCtlSwtch_B_Stat4 : 21|1@0+ (1,0) [0|1] "SED"  GWM
 SG_ CamraFrnt_B_RqMnu : 12|1@0+ (1,0) [0|1] "SED"  GWM
 SG_ StabBarCnncButtn_D_Sta3 : 23|2@0+ (1,0) [0|3] "SED"  GWM
 SG_ TurnAsstSwtch_D_Stat : 14|2@0+ (1,0) [0|3] "SED"  GWM
 SG_ SelDrvMdeTxtRst_B_Rq2 : 15|1@0+ (1,0) [0|1] "SED"  GWM
 SG_ SelDrvMdePage_B_Stat : 0|1@0+ (1,0) [0|1] "SED"  GWM
 SG_ SelDrvMdeCnfm_D_Stat2 : 2|2@0+ (1,0) [0|3] "SED"  GWM
 SG_ SelDrvMde_D_RqDrv : 7|5@0+ (1,0) [0|31] "SED"  GWM

BO_ 584 AUDIO_RDISP2_WORD_Rx: 8 HUD_ADV
 SG_ AUDIO_RDISP2_WORD_Rx : 7|64@0+ (1,0) [0|1.84467440737096E+019] "unitless"  ACM,APIM_CISM

BO_ 1052 Torque_Status_HS3: 8 GWM
 SG_ AwdDcnntSlipTrgt_B_Rq : 56|1@0+ (1,0) [0|1] "SED" Vector__XXX
 SG_ AwdCnnct_D_Stat : 58|2@0+ (1,0) [0|3] "SED" Vector__XXX
 SG_ AwdRight_Tq_Rq : 35|12@0+ (1,0) [0|4093] "Nm" Vector__XXX
 SG_ AwdRight_Tq_Est : 31|12@0+ (1,0) [0|4093] "Nm" Vector__XXX
 SG_ AwdLeft_Tq_Rq : 11|12@0+ (1,0) [0|4093] "Nm" Vector__XXX
 SG_ AwdLeft_Tq_Est : 7|12@0+ (1,0) [0|4093] "Nm" Vector__XXX
 SG_ AwdLck_Tq_Actl : 54|12@0+ (1,0) [0|4093] "Nm"  IPC
 SG_ AwdLckTqNeg_B_Actl : 55|1@0+ (1,0) [0|1] "SED" Vector__XXX

BO_ 754 ACU_Send_Signals_14: 8 ACM
 SG_ ACU_ActChimeTypeDat_St : 5|14@0+ (1,0) [0|16383] "unitless"  DSP
 SG_ ACU_ActChimeType_St : 23|3@0+ (1,0) [0|7] "SED"  DSP

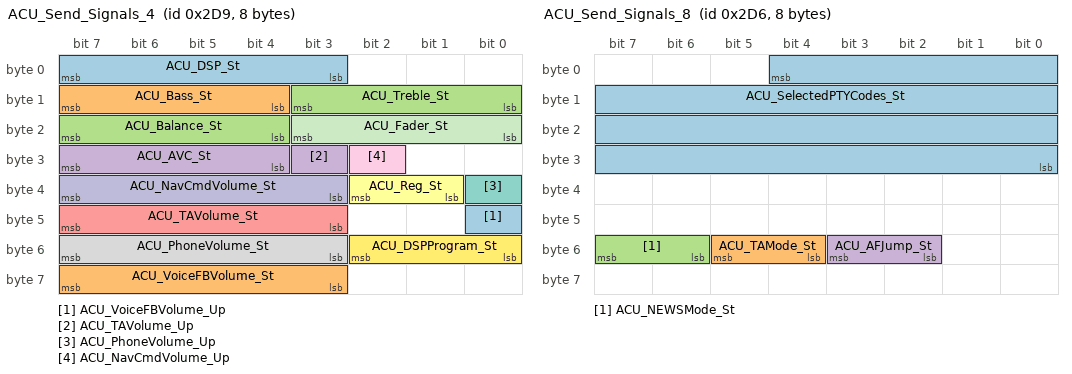
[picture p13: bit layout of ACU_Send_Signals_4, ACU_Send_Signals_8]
BO_ 729 ACU_Send_Signals_4: 8 ACM
 SG_ ACU_VoiceFBVolume_Up : 40|1@0+ (1,0) [0|1] "SED"  HUD_ADV,APIM,IPC
 SG_ ACU_VoiceFBVolume_St : 63|5@0+ (1,0) [0|30] "unitless"  HUD_ADV,WCM,APIM,IPC
 SG_ ACU_Treble_St : 11|4@0+ (1,-7) [-7|8] "unitless"  APIM,IPC
 SG_ ACU_TAVolume_Up : 27|1@0+ (1,0) [0|1] "SED"  HUD_ADV,APIM,IPC
 SG_ ACU_TAVolume_St : 47|5@0+ (1,0) [0|30] "SED"  HUD_ADV,WCM,APIM,IPC
 SG_ ACU_Reg_St : 34|2@0+ (1,0) [0|3] "SED"  APIM
 SG_ ACU_PhoneVolume_Up : 32|1@0+ (1,0) [0|1] "SED"  HUD_ADV,APIM,IPC
 SG_ ACU_PhoneVolume_St : 55|5@0+ (1,0) [0|30] "SED"  HUD_ADV,WCM,APIM,IPC
 SG_ ACU_NavCmdVolume_Up : 26|1@0+ (1,0) [0|1] "SED"  HUD_ADV,APIM,IPC
 SG_ ACU_NavCmdVolume_St : 39|5@0+ (1,0) [0|30] "SED"  HUD_ADV,WCM,APIM,IPC
 SG_ ACU_Fader_St : 19|4@0+ (1,-7) [-7|8] "unitless"  APIM,IPC
 SG_ ACU_DSPProgram_St : 50|3@0+ (1,0) [0|7] "SED"  APIM
 SG_ ACU_DSP_St : 7|5@0+ (1,0) [0|31] "SED"  APIM
 SG_ ACU_Bass_St : 15|4@0+ (1,-7) [-7|8] "unitless"  APIM
 SG_ ACU_Balance_St : 23|4@0+ (1,-7) [-7|8] "unitless"  APIM
 SG_ ACU_AVC_St : 31|4@0+ (1,0) [0|7] "unitless"  APIM

BO_ 727 ACU_Send_Signals_2: 8 ACM
 SG_ ACU_LoadEjectMode_St : 7|4@0+ (1,0) [0|15] "SED"  APIM
 SG_ ACU_LoadEjectDisc_St : 2|3@0+ (1,0) [0|7] "SED"  APIM

BO_ 726 ACU_Send_Signals_8: 8 ACM
 SG_ ACU_SelectedPTYCodes_St : 4|29@0+ (1,0) [0|536870911] "unitless"  APIM
 SG_ ACU_TAMode_St : 53|2@0+ (1,0) [0|3] "SED"  IPC,APIM
 SG_ ACU_NEWSMode_St : 55|2@0+ (1,0) [0|3] "SED"  IPC,APIM
 SG_ ACU_AFJump_St : 51|2@0+ (1,0) [0|3] "SED"  APIM

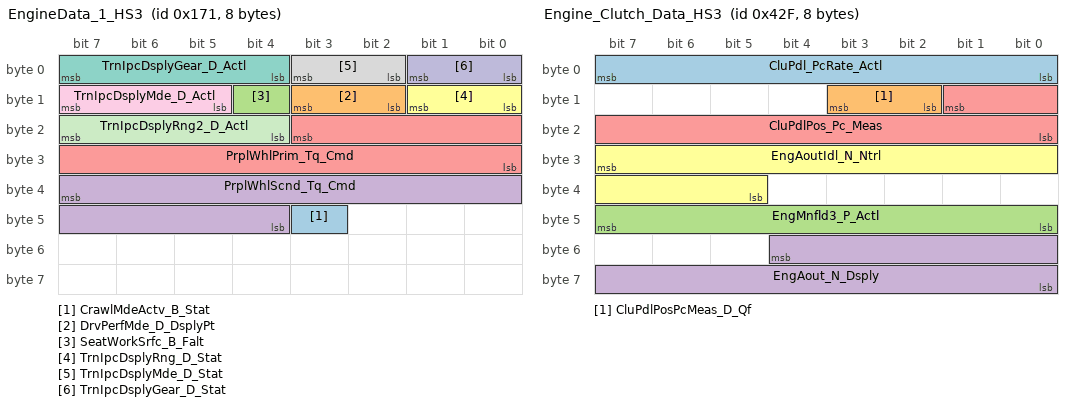
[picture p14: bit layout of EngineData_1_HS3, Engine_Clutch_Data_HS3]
BO_ 369 EngineData_1_HS3: 8 GWM
 SG_ CrawlMdeActv_B_Stat : 43|1@0+ (1,0) [0|1] "SED"  IPC
 SG_ DrvPerfMde_D_DsplyPt : 11|2@0+ (1,0) [0|3] "SED"  ACM
 SG_ SeatWorkSrfc_B_Falt : 12|1@0+ (1,0) [0|1] "SED"  IPC
 SG_ PrplWhlScnd_Tq_Cmd : 39|12@0+ (8,-16380) [-16380|16380] "Nm"  GENERIC
 SG_ PrplWhlPrim_Tq_Cmd : 19|12@0+ (8,-16380) [-16380|16380] "Nm"  GENERIC
 SG_ TrnIpcDsplyRng_D_Stat : 9|2@0+ (1,0) [0|3] "SED"  IPC
 SG_ TrnIpcDsplyGear_D_Actl : 7|4@0+ (1,0) [0|15] "SED"  HUD_ADV,APIM_CISM,APIM,IPC
 SG_ TrnIpcDsplyMde_D_Stat : 3|2@0+ (1,0) [0|3] "SED"  HUD_ADV,IPC
 SG_ TrnIpcDsplyMde_D_Actl : 15|3@0+ (1,0) [0|7] "SED"  HUD_ADV,IPC
 SG_ TrnIpcDsplyGear_D_Stat : 1|2@0+ (1,0) [0|3] "SED"  HUD_ADV,IPC
 SG_ TrnIpcDsplyRng2_D_Actl : 23|4@0+ (1,0) [0|15] "SED"  IPC

BO_ 1832 TesterPhysicalResIPC: 8 IPC
 SG_ TesterPhysicalResIPC : 7|64@0+ (1,0) [0|1.84467E+019] "unitless"  TSTR

BO_ 1071 Engine_Clutch_Data_HS3: 8 GWM
 SG_ CluPdl_PcRate_Actl : 7|8@0+ (0.04,-5) [-5|5.2] "%/ms"  IPC
 SG_ CluPdlPosPcMeas_D_Qf : 11|2@0+ (1,0) [0|3] "SED"  IPC
 SG_ EngMnfld3_P_Actl : 47|8@0+ (10,0) [0|2530] "milibar"  GENERIC
 SG_ EngAout_N_Dsply : 52|13@0+ (2,0) [0|16382] "rpm"  IPC
 SG_ CluPdlPos_Pc_Meas : 9|10@0+ (0.1,0) [0|102.3] "%"  IPC
 SG_ EngAoutIdl_N_Ntrl : 31|11@0+ (2,0) [0|4094] "rpm"  GENERIC

BO_ 848 RestraintsData: 8 IPC
 SG_ RILStat : 7|2@0+ (1,0) [0|3] "SED"  GWM

BO_ 891 Active_Noise_Data: 8 DACMC
 SG_ CabnSndAmb2_Db_Actl : 7|8@0+ (1,10) [10|264] "decibel"  GWM

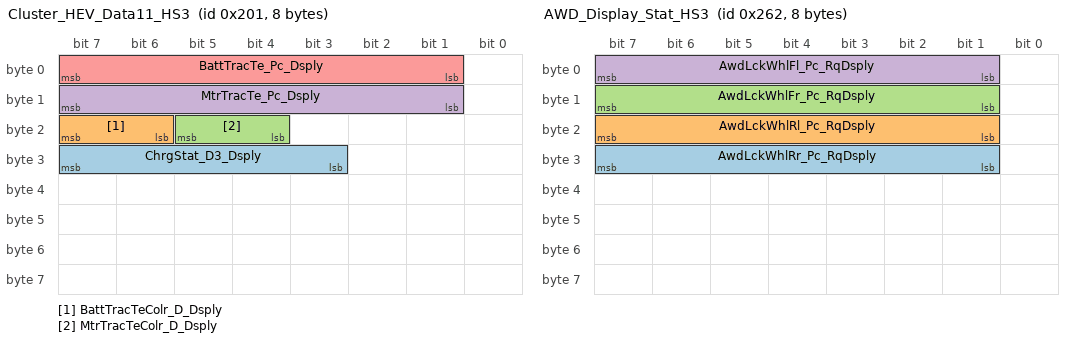
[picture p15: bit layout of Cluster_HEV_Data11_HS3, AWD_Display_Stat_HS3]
BO_ 513 Cluster_HEV_Data11_HS3: 8 GWM
 SG_ ChrgStat_D3_Dsply : 31|5@0+ (1,0) [0|31] "SED"  APIM
 SG_ BattTracTeColr_D_Dsply : 23|2@0+ (1,0) [0|3] "SED"  IPC
 SG_ MtrTracTeColr_D_Dsply : 21|2@0+ (1,0) [0|3] "SED"  IPC
 SG_ MtrTracTe_Pc_Dsply : 15|7@0+ (1,0) [0|127] "percent"  IPC
 SG_ BattTracTe_Pc_Dsply : 7|7@0+ (1,0) [0|127] "percent"  IPC

BO_ 610 AWD_Display_Stat_HS3: 8 GWM
 SG_ AwdLckWhlRr_Pc_RqDsply : 31|7@0+ (1,0) [0|127] "percent"  IPC
 SG_ AwdLckWhlRl_Pc_RqDsply : 23|7@0+ (1,0) [0|127] "percent"  IPC
 SG_ AwdLckWhlFr_Pc_RqDsply : 15|7@0+ (1,0) [0|127] "percent"  IPC
 SG_ AwdLckWhlFl_Pc_RqDsply : 7|7@0+ (1,0) [0|127] "percent"  IPC

BO_TX_BU_ 401 : APIM_CISM,APIM;
BO_TX_BU_ 1246 : GWM,TRM_ITRM;
BO_TX_BU_ 890 : APIM_CISM,ACM,DACMC;
BO_TX_BU_ 261 : APIM,APIM_CISM,ACM;
BO_TX_BU_ 753 : APIM_CISM,APIM;
BO_TX_BU_ 1000 : APIM_CISM,ACM;
BO_TX_BU_ 1049 : APIM_CISM,APIM;
BO_TX_BU_ 729 : APIM_CISM,ACM;
BO_TX_BU_ 726 : APIM_CISM,ACM;
CM_ BO_ 531 "IC is NOT to use data in this message for displays, Used data from 415 instead.";
CM_ SG_ 702 PHONE_MC_WORD_Rx "MM ISO 15765-2 Message Catalogue
Section MC - PHONE";
CM_ SG_ 711 MyKeySrvr_Clnt_Word_Tx "TP-LOG-GTPC-201379-SID-7C";
CM_ BO_ 549 "Method IPC _Infotainment";
CM_ SG_ 549 BeltminderAudioMute "Object.MyKey.BeltMinderAudioMute.St";
CM_ SG_ 549 Power_Up_Chime_Modules "Object.AlertMethod.IPC _Infotainment";
CM_ SG_ 549 Chime_Source "Object.AlertMethod.IPC_infotainment";
CM_ SG_ 765 Mc_VehUntTrpCoUsrSel_St "Object.VehicleSettings.Disp_Miles_Kilometers.Rq";
CM_ SG_ 765 Mc_VehUnitTempUsrSel_St "Object.VehicleSettings.Disp_Temperature.Rq";
CM_ SG_ 765 Mc_VehDayNightUsrSel_St "Object.BodyInterface.Settings.VehicleDayNightUserSelection
Object.BodyInterface.Status.AMDayNightSensitivity";
CM_ SG_ 765 Mc_VehTimeFrmtUsrSel_St "Object.BodyInterface.Settings.VehicleTimeFormatUserSelection";
CM_ SG_ 765 Mc_VehThemeUsrSel_St "Object.BodyInterface.Settings.VehicleThemeUserSelection";
CM_ SG_ 765 Mc_VehLangUsrSel_St "Object.BodyInterface.Settings.VehicleLanguageUserSelection
Object Vehicle Settings.Disp_LangSel
";
CM_ SG_ 508 Mc_DB1GetInfStartInd_Rq "Object Media Player iPod.GetMDBInfo.MDBStartItemInd
";
CM_ SG_ 508 Mc_DB1GtInfNbrOfItms_Rq "Object Media Player iPod.GetMDBInfo.MDBNbrOfItems
";
CM_ SG_ 508 Mc_DB1GetInfSetConf_Rq "Object Media Player iPod.GetMDBInfo.MDBSetFilterConf
";
CM_ SG_ 508 Mc_DB1GetInfSetFilt3_Rq "Object Media Player iPod.GetMDBInfo.MDBSetFilter3
";
CM_ SG_ 508 Mc_DB1GetInfSetFilt2_Rq "Object Media Player iPod.GetMDBInfo.MDBSetFilter2
";
CM_ SG_ 508 Mc_DB1GetInfSetFilt1_Rq "Object Media Player iPod.GetMDBInfo.MDBSetFilter1 ";
CM_ SG_ 507 Mc_DB1SetTrkItmIndex_Rq "Object Media Player iPod.MDBSetTrack.MDBItemIndex
";
CM_ SG_ 507 Mc_DB1SetTrkSetConf_Rq "Object Media Player iPod.MDBSetTrack.MDBSetFilterConf";
CM_ SG_ 507 Mc_DB1SetTrkSetFilt3_Rq "Object Media Player iPod.MDBSetTrack.MDBSetFilter3";
CM_ SG_ 507 Mc_DB1SetTrkSetFilt2_Rq "Object Media Player iPod.MDBSetTrack.MDBSetFilter2";
CM_ SG_ 507 Mc_DB1SetTrkSetFilt1_Rq "Object Media Player iPod.MDBSetTrack.MDBSetFilter1";
CM_ SG_ 506 Mc_AudioSourceSel3_Rq "Object Media Player BTAudio.GetDetailedMPInfo.AudioSource
Object Media Player BTAudio.PlayFirstTrackInFolder.AudioSource
Object Media Player USB.GetDetailedMPInfo.AudioSource
Object Media Player USB.PlayFirstTrackInFolder.AudioSource";
CM_ SG_ 506 Mc_PlayFrstTrInFldr_Rq "Object Media Player BTAudio.PlayFirstTrackInFolder.FolderNumber
Object Media Player USB.PlayFirstTrackinFolder.FolderNumber

$FFFF: Inactive";
CM_ SG_ 506 Mc_ItemIndex_Rq "Object Media Player BTAudio.GetDetailedMPInfo.ItemIndex
Object Media Player USB.GetDetailedMPInfo.ItemIndex";
CM_ SG_ 506 Mc_FolderNumber3_Rq "Object Media Player BTAudio.GetDetailedMPInfo.FolderNumber
Object Media Player USB.GetDetailedMPInfo.FolderNumber";
CM_ SG_ 505 Mc_AudioSourceSel2_Rq "Object Media Player BTAudio.GetMPInfo.AudioSouce
Object Media Player USB.GetMPInfo.AudioSouce
Object Media Player SDCard.GetMPInfo.AudioSouce";
CM_ SG_ 505 Mc_StartItemIndexRq "Object Media Player BTAudio.GetMPInfo.StartingItemIndex
Object Media Player USB.GetMPInfo.StartingItemIndex
Object Media Player SDCard.GetMPInfo.StartingItemIndex

$FFFF: Inactive";
CM_ SG_ 505 Mc_NbrOfItems2_Rq "Object Media Player BTAudio.GetMPInfo.NbrOfItems
Object Media Player USB.GetMPInfo.NbrOfItems
Object Media Player SDCard.GetMPInfo.NbrOfItems";
CM_ SG_ 505 Mc_ItemNameLength2_Rq "Object Media Player BTAudio.GetMPInfo.ItemNameLength
Object Media Player USB.GetMPInfo.ItemNameLength
Object Media Player SDCard.GetMPInfo.ItemNameLength";
CM_ SG_ 505 Mc_CutItem2_Rq "Object Media Player BTAudio.GetMPInfo.CutItemName
Object Media Player USB.GetMPInfo.CutItemName
Object Media Player SDCard.GetMPInfo.CutItemName";
CM_ SG_ 505 Mc_FolderNumber2_Rq "Object Media Player BTAudio.GetMPInfo.FolderNumber 
Object Media Player USB.GetMPInfo.FolderNumber
Object Media Player SDCard.GetMPInfo.FolderNumber

$FFFF: Inactive";
CM_ SG_ 505 Mc_FolderContent_Rq "Object Media Player USB.GetMPInfo.FolderContent
Object Media Player SDCard.GetMPInfo.FolderContent

Note: Value table entries were truncated from:
$0: RequestContentFromParameterFolderNumber
$1: RequestContentFromParentFolderOfParameterFolderNumber";
CM_ SG_ 403 Mc_RepeatGuidance_Rq "Object.NavigationRepeater.Guidance_Repeat.Rq.RepeatGuidance";
CM_ SG_ 403 Mc_CancelRoute_Rq "Object.NavigationRepater.CancelRoute.Rq.CancelRoute";
CM_ SG_ 403 Mc_CancelCurrWaypt_Rq "Object.NavigationRepeater.CancelCurrentWayPoint.Rq.Cancelwaypoint";
CM_ SG_ 403 Mc_TextMessage_Rq "Object. BTPhoneClient.TextMessage.Rq";
CM_ SG_ 403 Mc_BTInCallOptions_Rq "Object.BTPhoneClient.BTInCallOptions.Rq.SingleParam";
CM_ SG_ 403 Mc_PhMicrophoneMute_Rq "Object Blueetoth Phone.PhMicrophoneMute";
CM_ SG_ 403 Mc_LangSel_Rq "Object.VehicleSettings.Disp_LangSel.Rq.Language";
CM_ BO_ 401 "APIM Tx";
CM_ SG_ 401 Bezel_Beeps_Rq "Vehicle Settings";
CM_ SG_ 401 Disp_VehUntTripCoUsrSel "Obect.VehicleSettings.Disp_Miles_Kilometers.Rq.Mode";
CM_ SG_ 401 Disp_VehUnitTempUsrSel "Obect.VehicleSettings.Disp_Temperature.Rq.Mode";
CM_ SG_ 401 Disp_LangSel_Rq "Object.VehicleSettings.Disp_LangSel.Rq.Language";
CM_ SG_ 401 Disp_LangSel2_Rq "Reference GSDB for encoding: 009522/B;2-ZZ_LangSel";
CM_ BO_ 947 "Reserve InfoCAN Legacy signals from $3B3";
CM_ SG_ 947 Outside_Air_Temp_Stat "Filtered value, i.e. same as disply for customer";
CM_ SG_ 405 LBC1_StartItemInd "Object. ListBrowser.ItemInf.Rq.StartItemInd
0x0000:Inactive
0x0001:1
0xFFFE:65634
0xFFFF:Reserved";
CM_ SG_ 405 LBC1_SetListServ "Object. ListBrowser.ItemInf.Rq.SetListServ
0x00:Inactive
0x01:ServerID_1
0xFF:ALL";
CM_ SG_ 405 LBC1_Opcode "Object. ListBrowser.ItemInf.Rq.Opcode";
CM_ SG_ 405 LBC1_NbrOfItems "Object. ListBrowser.ItemInf.Rq.NbrOfItems
0x00:Inactive
0x01:1Item
0x3F:63Items";
CM_ SG_ 405 LBC1_ItemIndex "Object. ListBrowser.ItemInf.Rq.ItemIndex
0x0000:BrowseActiveListID
0x0001:EntryIndex_1
0xFFFF:ParentOfActiveListID";
CM_ SG_ 405 LBC1_ActiveListID "Object. ListBrowser.ItemInf.Rq.ActiveListID
0x0000:Root
0xFFFF:Reserved";
CM_ BO_ 756 "IPC_Chime2";
CM_ SG_ 756 Off_Time_Btwn_Chime2 "Object.AlertMethod.IPC_Chime
0x0 Inactive
0x1 Continuously (repeat continuously) 
0x2 5 msec
0x3 10 msec
0x4 15 msec
0x5 20 msec
0x6 40 msec
0x7 60 msec (increment is 20 msec steps until 800 msec)
cont....Refer SPSS for rest of encodings";
CM_ SG_ 756 Chime_Vol_Level2 "Object.AlertMethod. IPC_Chime
0x0 Inactive (no change to stored chime volume - 100% of stored chime volume)
0x1 99% (of stored chime volume)
....
0x63 1% (of stored chime volume)
0x64 Reserved";
CM_ SG_ 756 Chime_Time_Criticality2 "Object.AlertMethod. IPC_Chime";
CM_ SG_ 756 Chime_Occurence2 "Object.AlertMethod. IPC_Chime";
CM_ SG_ 756 Chime_Directionality2 "Object.AlertMethod. IPC_Chime";
CM_ SG_ 756 Chime2 "Object.AlertMethod. IPC_Chime
0x0 No_Chime  (note: if >No Chime< is selected then ignore other signals in this message)
0x1 Chime_1
0x2 Chime_2
0x3 Chime_3
cont.
0x3F Chime_63

";
CM_ BO_ 544 "Method IPC_Chime";
CM_ SG_ 544 Chime_Occurence "Object.AlertMethod. IPC_Chime";
CM_ SG_ 544 Off_Time_Btwn_Chime "Object.AlertMethod.IPC_Chime
0x0 Inactive
0x1 Continuously (repeat continuously) 
0x2 5 msec
0x3 10 msec
0x4 15 msec
0x5 20 msec
0x6 40 msec
0x7 60 msec (increment is 20 msec steps until 800 msec)
cont....Refer SPSS for rest of the encodings.
";
CM_ SG_ 544 Chime_Time_Criticality "Object.AlertMethod. IPC_Chime";
CM_ SG_ 544 Chime_Directionality "Object.AlertMethod. IPC_Chime";
CM_ SG_ 544 Chime_Vol_Level "Object.AlertMethod. IPC_Chime
0x0 Inactive (no change to stored chime volume - 100% of stored chime volume)
0x1 99% (of stored chime volume)
....
0x63 1% (of stored chime volume)
0x64 Reserved";
CM_ SG_ 544 Chime "Object.AlertMethod. IPC_Chime
0x0 No_Chime  (note: if >No Chime< is selected then ignore other signals in this message)
0x1 Chime_1
0x2 Chime_2
0x3 Chime_3
cont.
0x3F Chime_63
";
CM_ SG_ 291 LangUpdate_Rsp "Object. LanguageUpdate.Rsp";
CM_ SG_ 400 Mc_SetCurrStatMCCh_Rq "Object Tuner.SetCurrentStation.MCChannel";
CM_ SG_ 400 Mc_SetCurrntStatFreq_Rq "Object Tuner.SetCurrentStat.Request.Frequency

AM: Freq = 153+ Offset kHz.
Offset 0..1557

FM: Freq = 76+ Offset*0.05 MHz. Offset 0..640
Selected tuned band determine frequency (kHz or MHz).";
CM_ SG_ 400 Mc_SetCurrentStatOp_Rq "Object Tuner.SetCurrentStat.Request.Operation";
CM_ SG_ 400 Mc_PerTUStartIndex2_Rq "Object Personalization. DAB.GetTUPresetInfo.StartIndex2

$1-$FF: Preset 1 to 255";
CM_ SG_ 400 Mc_PerTUPresetArea_Rq "Object Personalization.DAB.GetTUPresetInfo.PresetArea

$5: Get AMAST (MW) Preset Data
$6: Get AM (LW) Preset Data";
CM_ SG_ 400 Mc_PerTUNbrOfPresets_Rq "Object Personalization. DAB.GetTUPresetInfo.NumberOfPresets

$1-$1E: Preset 1 to 30";
CM_ SG_ 647 HEC_BTIncomingCall_Rq "Object Bluetooth Phone.BTIncomingCall";
CM_ SG_ 647 HEC_BTEndTelService_Rq "Object Bluetooth Phone.BTEndTelService";
CM_ SG_ 359 TrnAin_Tq_Actl "Signal not transmitted on HEV variances.";
CM_ SG_ 359 PlgActvArb_B_Actl "Only supported on PHEV programs.  PlgActvArb_B_Actl HPCM will Tx on Powersplit PHEV’s,  On MHT PHEVs the PCM_HEV will Tx and HPCM will Rx. 
";
CM_ SG_ 359 TrnAinTq_D_Qf "Signal not transmitted on HEV variances.";
CM_ SG_ 261 OffPeakTimeSetType_Rq "Object:OffPeakTimeSet_Rq";
CM_ BO_ 753 "APIM Tx";
CM_ SG_ 1000 AHU_Bezel_Diag_St "Object:BezelDiagnostics.AHU_Bezel_Diag.St";
CM_ SG_ 1000 AHU_Shaker_St "Object:AudioSettings.AHU_Shaker ";
CM_ SG_ 1000 ACM_BeltminderAudioSt "Method: BeltminderAudioIsMuted";
CM_ SG_ 1000 MyKeyVolumeLimitUp "Method MykeyvolumeIsLimited:VolumeUpdate";
CM_ SG_ 1000 MyKeyVolumeLimitMode "Method MykeyvolumeIsLimited: Mode";
CM_ SG_ 584 AUDIO_RDISP2_WORD_Rx "MM ISO 15765-2 Message Catalogue RDISP2 - AUDIO";
CM_ SG_ 754 ACU_ActChimeTypeDat_St "Object BodyInterface.StdChimeIF.ActiveChime.TypeData.St

0x00: NoChime

ChimeType==Sine: 
Range: 0x01-0x3FF (1Hz - 16383Hz)

ChimeType==Sample: 
Range: 0x01-0x40  (Sample 1 - Sample 63)
Range: 0x41-0x3FFF (Reserved)";
CM_ SG_ 754 ACU_ActChimeType_St "Object BodyInterface.StdChimeIF.ActiveChime.Type.St";
CM_ SG_ 729 ACU_VoiceFBVolume_Up "Object Audio.VoiceFBVolume_UP
Object.AHU_VR_Vol_Updated
Indicate user value recalls if the value is set to lower/upper border ";
CM_ SG_ 729 ACU_VoiceFBVolume_St "Object Audio.VoiceFBVolume
Method AHU_VR_Vol_Level_St()

Refer method table in SPSS for details
0x0 No Volume
0x1 Vol_Step1
0x2 Vol_Step2
0x3 Vol_Step3
Cont.
0x1E Vol_Step30";
CM_ SG_ 729 ACU_Treble_St "Object Audio.Treble

Treble.St



Level -7..0..7


Method: AHU_Treble";
CM_ SG_ 729 ACU_TAVolume_Up "Object Audio.TAVolume_UP
Indicate user value recalls if the value is set to lower/upper border 
Method AHU_TA_Vol_Updated ";
CM_ SG_ 729 ACU_TAVolume_St "Object Audio.TAVolume
Method AHU_TA_Vol_Level.St 

Refer method table in SPSS for details
0x0 No Volume
0x1 Vol_Step1
0x2 Vol_Step2
0x3 Vol_Step3
Cont.
0x1E Vol_Step30";
CM_ SG_ 729 ACU_Reg_St "Object Tuner.REG";
CM_ SG_ 729 ACU_PhoneVolume_Up "Object Audio.PhoneVolume_UP

Object.VolumeControl.AHU_Phone_Vol_Updated";
CM_ SG_ 729 ACU_PhoneVolume_St "Object Audio.PhoneVolume
AHU_Phone_Vol_Level.St
0x0 No Volume
0x1 Vol_Step1
0x2 Vol_Step2
0x3 Vol_Step3
Cont.
0x1E Vol_Step30";
CM_ SG_ 729 ACU_NavCmdVolume_Up "Object Audio.NavCmdVolume_UP. AHU_Prompt_Vol_Updated. ";
CM_ SG_ 729 ACU_NavCmdVolume_St "Object Audio.NavCmdVolume. AHU_Prompt_Vol_Level.St()

Refer method table in SPSS for details
0x0 No Volume
0x1 Vol_Step1
0x2 Vol_Step2
0x3 Vol_Step3
Cont.
0x1E Vol_Step30";
CM_ SG_ 729 ACU_Fader_St "Object Audio.Fader



Fade.St

Level -7..0..7


Method: AHU_Fade";
CM_ SG_ 729 ACU_DSPProgram_St "Object Audio.DSPProgram
";
CM_ SG_ 729 ACU_DSP_St "Object. Audio.DSP
Object: AudioSettings.AHU_Occupancy_Mode.St";
CM_ SG_ 729 ACU_Bass_St "Object Audio.Bass



Bass.St

Level -7..0..7


Method: AHU_Bass";
CM_ SG_ 729 ACU_Balance_St "Object Audio.Balance

Balance.St



Level -7..0..7


Method: AHU_Balance";
CM_ SG_ 729 ACU_AVC_St "Object Audio.AVC
Off, Level 1 .. Level 7

Method: AHU_Speed_Comp_Vol.St";
CM_ SG_ 727 ACU_LoadEjectMode_St "Object Indash CD Changer.LoadEject(Action)";
CM_ SG_ 727 ACU_LoadEjectDisc_St "Object Indash CD Changer.LoadEject(Disc Number)";
CM_ SG_ 726 ACU_SelectedPTYCodes_St "Object Tuner.SelectedPTYCodes

Bit 0: 0: invalid, 1: valid
Bit 1: 0: PTY code 2 not selected; 1: PTY code 2 selected
...
Bit 28: 0: PTY code 29 not selected; 1: PTY code 29 selected";
CM_ SG_ 726 ACU_TAMode_St "Object Tuner.TAMode";
CM_ SG_ 726 ACU_NEWSMode_St "Object Tuner.NEWSMode";
CM_ SG_ 726 ACU_AFJump_St "Object Tuner.AFJump.St";
CM_ SG_ 1071 CluPdl_PcRate_Actl "Signal not transmitted on HEV variants.";
CM_ SG_ 1071 CluPdlPosPcMeas_D_Qf "Signal not transmitted on HEV variants.";
CM_ SG_ 1071 CluPdlPos_Pc_Meas "Signal not transmitted on HEV variants.";
CM_ SG_ 1071 EngAoutIdl_N_Ntrl "Signal not transmitted on HEV variants and diesel.";
CM_ BO_ 891 "DACMC Tx";
BA_DEF_ BO_  "FrameRouting" STRING ;
BA_DEF_ BO_  "FrameGatewayNetwork" STRING ;
BA_DEF_ BO_  "NetworkInitialization" ENUM  "No","Yes";
BA_DEF_ BO_  "FrameGatewayId" HEX 0 1407;
BA_DEF_ BO_  "EventRateOfChange" INT 10 10000;
BA_DEF_ BO_  "GenMsgStartDelayTime" INT 0 10000;
BA_DEF_ BO_  "GenMsgNrOfRepetition" INT 0 100;
BA_DEF_ BO_  "GenMsgDelayTime" INT 0 1000;
BA_DEF_ BO_  "GenMsgCycleTime" INT 0 100000;
BA_DEF_ BO_  "GenMsgSendType" ENUM  "FixedPeriodic","Event","EnabledPeriodic","NotUsed","NotUsed","EventPeriodic","NotUsed","NotUsed","NoMsgSendType";
BA_DEF_ SG_  "U_CD764_MY2022_Tx" ENUM  "No","Yes";
BA_DEF_ SG_  "U_U55X_MY2022_Tx" ENUM  "No","Yes";
BA_DEF_ SG_  "U_CD542_MY2021_Tx" ENUM  "No","Yes";
BA_DEF_ SG_  "ECGUsedTxSignal" ENUM  "No","Yes";
BA_DEF_ SG_  "U_T6_MCA_MY2020_Tx" ENUM  "No","Yes";
BA_DEF_ SG_  "U_P702_MY2021_Tx" ENUM  "No","Yes";
BA_DEF_ SG_  "U_CX727_MY2021_Tx" ENUM  "No","Yes";
BA_DEF_ SG_  "U_CD764_MY2022_Rx" ENUM  "No","Yes";
BA_DEF_ SG_  "U_FNV2_IVI_Rx" ENUM  "No","Yes";
BA_DEF_ SG_  "U_U55X_MY2022_Rx" ENUM  "No","Yes";
BA_DEF_ SG_  "U_CD542_MY2021_Rx" ENUM  "No","Yes";
BA_DEF_ SG_  "ECGUsedRxSignal" ENUM  "No","Yes";
BA_DEF_ SG_  "U_T6_MCA_MY2020_Rx" ENUM  "No","Yes";
BA_DEF_ SG_  "U_P702_MY2021_Rx" ENUM  "No","Yes";
BA_DEF_ SG_  "U_CX727_MY2021_Rx" ENUM  "No","Yes";
BA_DEF_ SG_  "GenSigStartValue" HEX 0 268435455;
BA_DEF_ SG_  "MetaData" ENUM  "No","Yes";
BA_DEF_ SG_  "ContentDependant" ENUM  "No","Yes";
BA_DEF_ SG_  "GenSigStartValueInteger" INT 0 1000000000;
BA_DEF_ SG_  "UsedOnPgmDBC" ENUM  "No","Yes";
BA_DEF_ SG_  "WakeupSignal" ENUM  "No","Yes";
BA_DEF_ SG_  "GenSigInactiveValue" INT 0 100000;
BA_DEF_ SG_  "GenSigSendType" ENUM  "Cyclic","OnWrite","vector_leerstring","OnChange","vector_leerstring","IfActive","vector_leerstring","NoSigSendType";
BA_DEF_ BO_  "OvtpPushApplication" ENUM  "FALSE","TRUE";
BA_DEF_ BO_  "SCP_FreshnessValueLength" INT 0 512;
BA_DEF_ BO_  "SCP_FreshnessValueTxLength" INT 0 512;
BA_DEF_ BO_  "SCP_AuthInfoTxLength" INT 0 512;
BA_DEF_ BO_  "GenMsgRoutingTimeoutTime" INT 0 5000;
BA_DEF_ BO_  "MessageGateway" ENUM  "No","Yes";
BA_DEF_ BO_  "NmAsrMessage" ENUM  "No","Yes";
BA_DEF_ BO_  "DiagState" ENUM  "No","Yes";
BA_DEF_ BO_  "TpTxIndex" INT 0 536870911;
BA_DEF_ BO_  "DiagRequest" ENUM  "No","Yes";
BA_DEF_ BO_  "DiagResponse" ENUM  "No","Yes";
BA_DEF_ BO_  "GenMsgILSupport" ENUM  "No","Yes";
BA_DEF_DEF_  "FrameRouting" "";
BA_DEF_DEF_  "FrameGatewayNetwork" "NONE";
BA_DEF_DEF_  "NetworkInitialization" "Yes";
BA_DEF_DEF_  "FrameGatewayId" 0;
BA_DEF_DEF_  "EventRateOfChange" 10000;
BA_DEF_DEF_  "GenMsgStartDelayTime" 0;
BA_DEF_DEF_  "GenMsgNrOfRepetition" 1;
BA_DEF_DEF_  "GenMsgDelayTime" 20;
BA_DEF_DEF_  "GenMsgCycleTime" 0;
BA_DEF_DEF_  "GenMsgSendType" "NoMsgSendType";
BA_DEF_DEF_  "U_CD764_MY2022_Tx" "No";
BA_DEF_DEF_  "U_U55X_MY2022_Tx" "No";
BA_DEF_DEF_  "U_CD542_MY2021_Tx" "No";
BA_DEF_DEF_  "ECGUsedTxSignal" "No";
BA_DEF_DEF_  "U_T6_MCA_MY2020_Tx" "No";
BA_DEF_DEF_  "U_P702_MY2021_Tx" "No";
BA_DEF_DEF_  "U_CX727_MY2021_Tx" "No";
BA_DEF_DEF_  "U_CD764_MY2022_Rx" "No";
BA_DEF_DEF_  "U_FNV2_IVI_Rx" "No";
BA_DEF_DEF_  "U_U55X_MY2022_Rx" "No";
BA_DEF_DEF_  "U_CD542_MY2021_Rx" "No";
BA_DEF_DEF_  "ECGUsedRxSignal" "No";
BA_DEF_DEF_  "U_T6_MCA_MY2020_Rx" "No";
BA_DEF_DEF_  "U_P702_MY2021_Rx" "No";
BA_DEF_DEF_  "U_CX727_MY2021_Rx" "No";
BA_DEF_DEF_  "GenSigStartValue" 0;
BA_DEF_DEF_  "MetaData" "No";
BA_DEF_DEF_  "ContentDependant" "No";
BA_DEF_DEF_  "GenSigStartValueInteger" 0;
BA_DEF_DEF_  "UsedOnPgmDBC" "Yes";
BA_DEF_DEF_  "WakeupSignal" "No";
BA_DEF_DEF_  "GenSigInactiveValue" 0;
BA_DEF_DEF_  "GenSigSendType" "NoSigSendType";
BA_DEF_DEF_  "OvtpPushApplication" "FALSE";
BA_DEF_DEF_  "SCP_FreshnessValueLength" 64;
BA_DEF_DEF_  "SCP_FreshnessValueTxLength" 11;
BA_DEF_DEF_  "SCP_AuthInfoTxLength" 53;
BA_DEF_DEF_  "GenMsgRoutingTimeoutTime" 0;
BA_DEF_DEF_  "MessageGateway" "No";
BA_DEF_DEF_  "NmAsrMessage" "No";
BA_DEF_DEF_  "DiagState" "No";
BA_DEF_DEF_  "TpTxIndex" 0;
BA_DEF_DEF_  "DiagRequest" "No";
BA_DEF_DEF_  "DiagResponse" "No";
BA_DEF_DEF_  "GenMsgILSupport" "Yes";
BA_ "FrameRouting" BO_ 531 "FD1_CAN,0x213;";
BA_ "FrameGatewayNetwork" BO_ 531 "FD1_CAN";
BA_ "FrameGatewayId" BO_ 531 531;
BA_ "GenMsgRoutingTimeoutTime" BO_ 531 60;
BA_ "NetworkInitialization" BO_ 702 0;
BA_ "TpTxIndex" BO_ 702 17;
BA_ "TpTxIndex" BO_ 711 24;
BA_ "GenMsgCycleTime" BO_ 549 1000;
BA_ "GenMsgSendType" BO_ 549 5;
BA_ "GenMsgCycleTime" BO_ 765 1000;
BA_ "GenMsgSendType" BO_ 765 5;
BA_ "GenMsgSendType" BO_ 508 1;
BA_ "GenMsgSendType" BO_ 507 1;
BA_ "GenMsgSendType" BO_ 506 1;
BA_ "GenMsgSendType" BO_ 505 1;
BA_ "NetworkInitialization" BO_ 403 0;
BA_ "GenMsgSendType" BO_ 403 1;
BA_ "GenMsgSendType" BO_ 401 1;
BA_ "FrameRouting" BO_ 1143 "FD1_CAN,0x477;";
BA_ "FrameGatewayNetwork" BO_ 1143 "FD1_CAN";
BA_ "FrameGatewayId" BO_ 1143 1143;
BA_ "FrameRouting" BO_ 1142 "FD1_CAN,0x476;";
BA_ "FrameGatewayNetwork" BO_ 1142 "FD1_CAN";
BA_ "FrameGatewayId" BO_ 1142 1142;
BA_ "GenMsgCycleTime" BO_ 947 1000;
BA_ "GenMsgSendType" BO_ 947 5;
BA_ "FrameRouting" BO_ 973 "FD1_CAN,0x3CD;HS2_CAN,0x3CD";
BA_ "NetworkInitialization" BO_ 405 0;
BA_ "GenMsgSendType" BO_ 405 1;
BA_ "GenMsgCycleTime" BO_ 756 1000;
BA_ "GenMsgSendType" BO_ 756 5;
BA_ "GenMsgCycleTime" BO_ 544 1000;
BA_ "GenMsgSendType" BO_ 544 5;
BA_ "NetworkInitialization" BO_ 291 0;
BA_ "GenMsgSendType" BO_ 291 1;
BA_ "GenMsgSendType" BO_ 400 1;
BA_ "GenMsgCycleTime" BO_ 647 200;
BA_ "GenMsgSendType" BO_ 647 5;
BA_ "FrameRouting" BO_ 359 "FD1_CAN,0x167;";
BA_ "FrameGatewayNetwork" BO_ 359 "FD1_CAN";
BA_ "FrameGatewayId" BO_ 359 359;
BA_ "GenMsgDelayTime" BO_ 359 0;
BA_ "FrameRouting" BO_ 990 "MS1_CAN,0x3DE;";
BA_ "FrameGatewayNetwork" BO_ 990 "MS1_CAN";
BA_ "FrameGatewayId" BO_ 990 990;
BA_ "FrameRouting" BO_ 989 "FD1_CAN,0x3DD;HS2_CAN,0x3DD";
BA_ "GenMsgCycleTime" BO_ 1246 100;
BA_ "GenMsgSendType" BO_ 1246 5;
BA_ "GenMsgCycleTime" BO_ 890 1000;
BA_ "GenMsgSendType" BO_ 890 5;
BA_ "NetworkInitialization" BO_ 1439 0;
BA_ "GenMsgCycleTime" BO_ 1439 1000;
BA_ "GenMsgSendType" BO_ 1439 0;
BA_ "NmAsrMessage" BO_ 1439 1;
BA_ "GenMsgILSupport" BO_ 1439 0;
BA_ "GenMsgSendType" BO_ 261 1;
BA_ "FrameRouting" BO_ 995 "HS1_CAN,0x3E3;";
BA_ "FrameGatewayNetwork" BO_ 995 "HS1_CAN";
BA_ "FrameGatewayId" BO_ 995 995;
BA_ "GenMsgCycleTime" BO_ 753 1000;
BA_ "GenMsgSendType" BO_ 753 5;
BA_ "GenMsgCycleTime" BO_ 1000 1000;
BA_ "GenMsgSendType" BO_ 1000 5;
BA_ "GenMsgCycleTime" BO_ 992 1000;
BA_ "GenMsgSendType" BO_ 992 5;
BA_ "FrameRouting" BO_ 991 "FD1_CAN,0x3DF;HS2_CAN,0x3DF;";
BA_ "FrameRouting" BO_ 1004 "HS1_CAN,0x3EB;";
BA_ "FrameGatewayNetwork" BO_ 1004 "HS1_CAN";
BA_ "FrameGatewayId" BO_ 1004 1003;
BA_ "GenMsgDelayTime" BO_ 522 10;
BA_ "GenMsgCycleTime" BO_ 522 20;
BA_ "GenMsgSendType" BO_ 522 0;
BA_ "GenMsgCycleTime" BO_ 497 1000;
BA_ "GenMsgSendType" BO_ 497 5;
BA_ "GenMsgCycleTime" BO_ 1049 1000;
BA_ "GenMsgSendType" BO_ 1049 5;
BA_ "TpTxIndex" BO_ 584 41;
BA_ "FrameRouting" BO_ 1052 "FD1_CAN,0x41C;";
BA_ "FrameGatewayNetwork" BO_ 1052 "FD1_CAN";
BA_ "FrameGatewayId" BO_ 1052 1052;
BA_ "GenMsgCycleTime" BO_ 754 1000;
BA_ "GenMsgSendType" BO_ 754 5;
BA_ "GenMsgCycleTime" BO_ 729 1000;
BA_ "GenMsgSendType" BO_ 729 5;
BA_ "GenMsgCycleTime" BO_ 727 1000;
BA_ "GenMsgSendType" BO_ 727 5;
BA_ "GenMsgCycleTime" BO_ 726 1000;
BA_ "GenMsgSendType" BO_ 726 5;
BA_ "FrameRouting" BO_ 369 "FD1_CAN,0x171;";
BA_ "FrameGatewayNetwork" BO_ 369 "FD1_CAN";
BA_ "FrameGatewayId" BO_ 369 369;
BA_ "GenMsgDelayTime" BO_ 369 15;
BA_ "NetworkInitialization" BO_ 1832 0;
BA_ "GenMsgDelayTime" BO_ 1832 0;
BA_ "GenMsgSendType" BO_ 1832 1;
BA_ "DiagResponse" BO_ 1832 1;
BA_ "GenMsgILSupport" BO_ 1832 0;
BA_ "GenMsgCycleTime" BO_ 1071 50;
BA_ "GenMsgSendType" BO_ 1071 0;
BA_ "GenMsgRoutingTimeoutTime" BO_ 1071 90;
BA_ "MessageGateway" BO_ 1071 1;
BA_ "GenMsgCycleTime" BO_ 848 1000;
BA_ "GenMsgSendType" BO_ 848 0;
BA_ "GenMsgCycleTime" BO_ 891 100;
BA_ "GenMsgSendType" BO_ 891 0;
BA_ "FrameRouting" BO_ 513 "FD1_CAN,0x201;";
BA_ "FrameGatewayNetwork" BO_ 513 "FD1_CAN";
BA_ "FrameGatewayId" BO_ 513 513;
BA_ "FrameRouting" BO_ 610 "FD1_CAN,0x262;";
BA_ "FrameGatewayNetwork" BO_ 610 "FD1_CAN";
BA_ "FrameGatewayId" BO_ 610 610;
BA_ "GenSigStartValue" SG_ 531 VehStop_D_Stat 2;
BA_ "GenSigStartValueInteger" SG_ 531 VehStop_D_Stat 2;
BA_ "U_U55X_MY2022_Rx" SG_ 531 PrkBrkYwLamp_D_Rq 1;
BA_ "U_CD542_MY2021_Rx" SG_ 531 PrkBrkYwLamp_D_Rq 1;
BA_ "U_T6_MCA_MY2020_Rx" SG_ 531 PrkBrkYwLamp_D_Rq 1;
BA_ "U_P702_MY2021_Rx" SG_ 531 PrkBrkYwLamp_D_Rq 1;
BA_ "WakeupSignal" SG_ 531 PrkBrkYwLamp_D_Rq 1;
BA_ "U_U55X_MY2022_Rx" SG_ 531 PrkBrkRedLamp_D_Rq 1;
BA_ "U_CD542_MY2021_Rx" SG_ 531 PrkBrkRedLamp_D_Rq 1;
BA_ "U_T6_MCA_MY2020_Rx" SG_ 531 PrkBrkRedLamp_D_Rq 1;
BA_ "U_P702_MY2021_Rx" SG_ 531 PrkBrkRedLamp_D_Rq 1;
BA_ "WakeupSignal" SG_ 531 PrkBrkRedLamp_D_Rq 1;
BA_ "U_U55X_MY2022_Rx" SG_ 531 PrkBrkMsgTxt_D_Rq 1;
BA_ "U_CD542_MY2021_Rx" SG_ 531 PrkBrkMsgTxt_D_Rq 1;
BA_ "U_T6_MCA_MY2020_Rx" SG_ 531 PrkBrkMsgTxt_D_Rq 1;
BA_ "U_P702_MY2021_Rx" SG_ 531 PrkBrkMsgTxt_D_Rq 1;
BA_ "WakeupSignal" SG_ 531 PrkBrkMsgTxt_D_Rq 1;
BA_ "U_CD764_MY2022_Rx" SG_ 531 PrkBrkStatus 1;
BA_ "U_U55X_MY2022_Rx" SG_ 531 PrkBrkStatus 1;
BA_ "U_CD542_MY2021_Rx" SG_ 531 PrkBrkStatus 1;
BA_ "U_T6_MCA_MY2020_Rx" SG_ 531 PrkBrkStatus 1;
BA_ "GenSigStartValue" SG_ 531 PrkBrkStatus 7;
BA_ "GenSigStartValueInteger" SG_ 531 PrkBrkStatus 7;
BA_ "U_CD542_MY2021_Rx" SG_ 531 LscmbbMntr_B_Err 1;
BA_ "U_T6_MCA_MY2020_Rx" SG_ 531 LscmbbMntr_B_Err 1;
BA_ "U_CD764_MY2022_Rx" SG_ 531 StabCtlBrkActv_B_Actl 1;
BA_ "U_U55X_MY2022_Rx" SG_ 531 StabCtlBrkActv_B_Actl 1;
BA_ "U_CD542_MY2021_Rx" SG_ 531 StabCtlBrkActv_B_Actl 1;
BA_ "U_T6_MCA_MY2020_Rx" SG_ 531 StabCtlBrkActv_B_Actl 1;
BA_ "U_U55X_MY2022_Rx" SG_ 531 CmbbBrkPrchg_B_Actl 1;
BA_ "U_T6_MCA_MY2020_Rx" SG_ 531 CmbbBrkPrchg_B_Actl 1;
BA_ "U_P702_MY2021_Rx" SG_ 531 CmbbBrkPrchg_B_Actl 1;
BA_ "U_U55X_MY2022_Rx" SG_ 531 CmbbBrkDecel_B_Actl 1;
BA_ "U_T6_MCA_MY2020_Rx" SG_ 531 CmbbBrkDecel_B_Actl 1;
BA_ "U_P702_MY2021_Rx" SG_ 531 CmbbBrkDecel_B_Actl 1;
BA_ "U_U55X_MY2022_Rx" SG_ 531 AccBrkTotTqMn_B_Actl 1;
BA_ "U_T6_MCA_MY2020_Rx" SG_ 531 AccBrkTotTqMn_B_Actl 1;
BA_ "U_P702_MY2021_Rx" SG_ 531 AccBrkTotTqMn_B_Actl 1;
BA_ "U_P702_MY2021_Rx" SG_ 531 AbsActv_B_Actl 1;
BA_ "U_U55X_MY2022_Rx" SG_ 531 AbsActv_B_Actl 1;
BA_ "U_CD542_MY2021_Rx" SG_ 531 AbsActv_B_Actl 1;
BA_ "U_T6_MCA_MY2020_Rx" SG_ 531 AbsActv_B_Actl 1;
BA_ "U_U55X_MY2022_Rx" SG_ 531 VehLongOvrGnd_A_Est 1;
BA_ "U_T6_MCA_MY2020_Rx" SG_ 531 VehLongOvrGnd_A_Est 1;
BA_ "U_P702_MY2021_Rx" SG_ 531 VehLongOvrGnd_A_Est 1;
BA_ "GenSigStartValueInteger" SG_ 531 VehLongOvrGnd_A_Est 511;
BA_ "U_CD764_MY2022_Tx" SG_ 702 PHONE_MC_WORD_Rx 1;
BA_ "U_U55X_MY2022_Tx" SG_ 702 PHONE_MC_WORD_Rx 1;
BA_ "U_CD542_MY2021_Tx" SG_ 702 PHONE_MC_WORD_Rx 1;
BA_ "U_T6_MCA_MY2020_Tx" SG_ 702 PHONE_MC_WORD_Rx 1;
BA_ "U_CD764_MY2022_Rx" SG_ 702 PHONE_MC_WORD_Rx 1;
BA_ "U_U55X_MY2022_Rx" SG_ 702 PHONE_MC_WORD_Rx 1;
BA_ "U_CD542_MY2021_Rx" SG_ 702 PHONE_MC_WORD_Rx 1;
BA_ "U_T6_MCA_MY2020_Rx" SG_ 702 PHONE_MC_WORD_Rx 1;
BA_ "U_P702_MY2021_Rx" SG_ 702 PHONE_MC_WORD_Rx 1;
BA_ "U_U55X_MY2022_Tx" SG_ 711 MyKeySrvr_Clnt_Word_Tx 1;
BA_ "U_T6_MCA_MY2020_Tx" SG_ 711 MyKeySrvr_Clnt_Word_Tx 1;
BA_ "U_U55X_MY2022_Rx" SG_ 711 MyKeySrvr_Clnt_Word_Tx 1;
BA_ "U_CD542_MY2021_Rx" SG_ 711 MyKeySrvr_Clnt_Word_Tx 1;
BA_ "U_T6_MCA_MY2020_Rx" SG_ 711 MyKeySrvr_Clnt_Word_Tx 1;
BA_ "U_P702_MY2021_Rx" SG_ 711 MyKeySrvr_Clnt_Word_Tx 1;
BA_ "U_CD764_MY2022_Tx" SG_ 549 CCOI_PolicyClient_St2 1;
BA_ "U_CD764_MY2022_Rx" SG_ 549 CCOI_PolicyClient_St2 1;
BA_ "ECGUsedRxSignal" SG_ 549 CCOI_PolicyClient_St2 1;
BA_ "GenSigSendType" SG_ 549 CCOI_PolicyClient_St2 3;
BA_ "U_CD764_MY2022_Tx" SG_ 549 FactoryReset_Rq2 1;
BA_ "U_CD764_MY2022_Rx" SG_ 549 FactoryReset_Rq2 1;
BA_ "ECGUsedRxSignal" SG_ 549 FactoryReset_Rq2 1;
BA_ "GenSigSendType" SG_ 549 FactoryReset_Rq2 3;
BA_ "U_CD764_MY2022_Tx" SG_ 549 NavIod_D_Rq 1;
BA_ "GenSigSendType" SG_ 549 NavIod_D_Rq 3;
BA_ "U_CD764_MY2022_Tx" SG_ 549 WwaActv_B_Stat 1;
BA_ "U_CD542_MY2021_Tx" SG_ 549 WwaActv_B_Stat 1;
BA_ "U_T6_MCA_MY2020_Tx" SG_ 549 WwaActv_B_Stat 1;
BA_ "U_U55X_MY2022_Rx" SG_ 549 WwaActv_B_Stat 1;
BA_ "U_CD542_MY2021_Rx" SG_ 549 WwaActv_B_Stat 1;
BA_ "U_T6_MCA_MY2020_Rx" SG_ 549 WwaActv_B_Stat 1;
BA_ "GenSigSendType" SG_ 549 WwaActv_B_Stat 3;
BA_ "U_CD764_MY2022_Tx" SG_ 549 StrtInGearOk_D_Stat 1;
BA_ "U_U55X_MY2022_Tx" SG_ 549 StrtInGearOk_D_Stat 1;
BA_ "GenSigSendType" SG_ 549 StrtInGearOk_D_Stat 3;
BA_ "U_CD764_MY2022_Tx" SG_ 549 Veh_V2_Dsply 1;
BA_ "U_U55X_MY2022_Tx" SG_ 549 Veh_V2_Dsply 1;
BA_ "U_CD542_MY2021_Tx" SG_ 549 Veh_V2_Dsply 1;
BA_ "U_T6_MCA_MY2020_Tx" SG_ 549 Veh_V2_Dsply 1;
BA_ "U_P702_MY2021_Tx" SG_ 549 Veh_V2_Dsply 1;
BA_ "U_CD542_MY2021_Rx" SG_ 549 Veh_V2_Dsply 1;
BA_ "U_U55X_MY2022_Rx" SG_ 549 Veh_V2_Dsply 1;
BA_ "U_T6_MCA_MY2020_Rx" SG_ 549 Veh_V2_Dsply 1;
BA_ "GenSigSendType" SG_ 549 Veh_V2_Dsply 3;
BA_ "U_CD764_MY2022_Tx" SG_ 549 IPC_MyKeyVolLimit_St 1;
BA_ "U_U55X_MY2022_Tx" SG_ 549 IPC_MyKeyVolLimit_St 1;
BA_ "U_CD542_MY2021_Tx" SG_ 549 IPC_MyKeyVolLimit_St 1;
BA_ "U_T6_MCA_MY2020_Tx" SG_ 549 IPC_MyKeyVolLimit_St 1;
BA_ "U_P702_MY2021_Tx" SG_ 549 IPC_MyKeyVolLimit_St 1;
BA_ "U_CD764_MY2022_Rx" SG_ 549 IPC_MyKeyVolLimit_St 1;
BA_ "U_U55X_MY2022_Rx" SG_ 549 IPC_MyKeyVolLimit_St 1;
BA_ "U_CD542_MY2021_Rx" SG_ 549 IPC_MyKeyVolLimit_St 1;
BA_ "U_T6_MCA_MY2020_Rx" SG_ 549 IPC_MyKeyVolLimit_St 1;
BA_ "U_P702_MY2021_Rx" SG_ 549 IPC_MyKeyVolLimit_St 1;
BA_ "GenSigSendType" SG_ 549 IPC_MyKeyVolLimit_St 3;
BA_ "U_CD764_MY2022_Tx" SG_ 549 HudVertSzMnuOn_B_Rq 1;
BA_ "U_U55X_MY2022_Tx" SG_ 549 HudVertSzMnuOn_B_Rq 1;
BA_ "U_T6_MCA_MY2020_Tx" SG_ 549 HudVertSzMnuOn_B_Rq 1;
BA_ "U_U55X_MY2022_Rx" SG_ 549 HudVertSzMnuOn_B_Rq 1;
BA_ "U_T6_MCA_MY2020_Rx" SG_ 549 HudVertSzMnuOn_B_Rq 1;
BA_ "GenSigSendType" SG_ 549 HudVertSzMnuOn_B_Rq 3;
BA_ "U_CD764_MY2022_Tx" SG_ 549 HudVertMnuOn_B_Rq 1;
BA_ "U_U55X_MY2022_Tx" SG_ 549 HudVertMnuOn_B_Rq 1;
BA_ "U_T6_MCA_MY2020_Tx" SG_ 549 HudVertMnuOn_B_Rq 1;
BA_ "U_U55X_MY2022_Rx" SG_ 549 HudVertMnuOn_B_Rq 1;
BA_ "U_T6_MCA_MY2020_Rx" SG_ 549 HudVertMnuOn_B_Rq 1;
BA_ "GenSigSendType" SG_ 549 HudVertMnuOn_B_Rq 3;
BA_ "U_CD764_MY2022_Tx" SG_ 549 HudRotatMnuOn_B_Rq 1;
BA_ "U_U55X_MY2022_Tx" SG_ 549 HudRotatMnuOn_B_Rq 1;
BA_ "U_T6_MCA_MY2020_Tx" SG_ 549 HudRotatMnuOn_B_Rq 1;
BA_ "U_U55X_MY2022_Rx" SG_ 549 HudRotatMnuOn_B_Rq 1;
BA_ "U_T6_MCA_MY2020_Rx" SG_ 549 HudRotatMnuOn_B_Rq 1;
BA_ "GenSigSendType" SG_ 549 HudRotatMnuOn_B_Rq 3;
BA_ "U_CD764_MY2022_Tx" SG_ 549 HudCntntMnuOn_B_Rq 1;
BA_ "U_U55X_MY2022_Tx" SG_ 549 HudCntntMnuOn_B_Rq 1;
BA_ "U_T6_MCA_MY2020_Tx" SG_ 549 HudCntntMnuOn_B_Rq 1;
BA_ "U_U55X_MY2022_Rx" SG_ 549 HudCntntMnuOn_B_Rq 1;
BA_ "U_T6_MCA_MY2020_Rx" SG_ 549 HudCntntMnuOn_B_Rq 1;
BA_ "GenSigSendType" SG_ 549 HudCntntMnuOn_B_Rq 3;
BA_ "U_CD764_MY2022_Tx" SG_ 549 HudBrightMnuOn_B_Rq 1;
BA_ "U_U55X_MY2022_Tx" SG_ 549 HudBrightMnuOn_B_Rq 1;
BA_ "U_T6_MCA_MY2020_Tx" SG_ 549 HudBrightMnuOn_B_Rq 1;
BA_ "U_U55X_MY2022_Rx" SG_ 549 HudBrightMnuOn_B_Rq 1;
BA_ "U_T6_MCA_MY2020_Rx" SG_ 549 HudBrightMnuOn_B_Rq 1;
BA_ "GenSigSendType" SG_ 549 HudBrightMnuOn_B_Rq 3;
BA_ "U_CD764_MY2022_Tx" SG_ 549 HdcOn_B_Rq 1;
BA_ "U_U55X_MY2022_Tx" SG_ 549 HdcOn_B_Rq 1;
BA_ "U_CD542_MY2021_Tx" SG_ 549 HdcOn_B_Rq 1;
BA_ "U_T6_MCA_MY2020_Tx" SG_ 549 HdcOn_B_Rq 1;
BA_ "U_P702_MY2021_Tx" SG_ 549 HdcOn_B_Rq 1;
BA_ "GenSigSendType" SG_ 549 HdcOn_B_Rq 3;
BA_ "U_CD764_MY2022_Tx" SG_ 549 IPC_Attn_Info_Audio 1;
BA_ "U_U55X_MY2022_Tx" SG_ 549 IPC_Attn_Info_Audio 1;
BA_ "U_CD542_MY2021_Tx" SG_ 549 IPC_Attn_Info_Audio 1;
BA_ "U_T6_MCA_MY2020_Tx" SG_ 549 IPC_Attn_Info_Audio 1;
BA_ "U_P702_MY2021_Tx" SG_ 549 IPC_Attn_Info_Audio 1;
BA_ "U_CD764_MY2022_Rx" SG_ 549 IPC_Attn_Info_Audio 1;
BA_ "U_U55X_MY2022_Rx" SG_ 549 IPC_Attn_Info_Audio 1;
BA_ "U_CD542_MY2021_Rx" SG_ 549 IPC_Attn_Info_Audio 1;
BA_ "U_T6_MCA_MY2020_Rx" SG_ 549 IPC_Attn_Info_Audio 1;
BA_ "U_P702_MY2021_Rx" SG_ 549 IPC_Attn_Info_Audio 1;
BA_ "GenSigSendType" SG_ 549 IPC_Attn_Info_Audio 3;
BA_ "U_CD764_MY2022_Tx" SG_ 549 BeltminderAudioMute 1;
BA_ "U_U55X_MY2022_Tx" SG_ 549 BeltminderAudioMute 1;
BA_ "U_CD542_MY2021_Tx" SG_ 549 BeltminderAudioMute 1;
BA_ "U_T6_MCA_MY2020_Tx" SG_ 549 BeltminderAudioMute 1;
BA_ "U_P702_MY2021_Tx" SG_ 549 BeltminderAudioMute 1;
BA_ "U_CD764_MY2022_Rx" SG_ 549 BeltminderAudioMute 1;
BA_ "U_U55X_MY2022_Rx" SG_ 549 BeltminderAudioMute 1;
BA_ "U_CD542_MY2021_Rx" SG_ 549 BeltminderAudioMute 1;
BA_ "U_T6_MCA_MY2020_Rx" SG_ 549 BeltminderAudioMute 1;
BA_ "U_P702_MY2021_Rx" SG_ 549 BeltminderAudioMute 1;
BA_ "GenSigSendType" SG_ 549 BeltminderAudioMute 3;
BA_ "U_CD764_MY2022_Tx" SG_ 549 Power_Up_Chime_Modules 1;
BA_ "U_U55X_MY2022_Tx" SG_ 549 Power_Up_Chime_Modules 1;
BA_ "U_CD542_MY2021_Tx" SG_ 549 Power_Up_Chime_Modules 1;
BA_ "U_T6_MCA_MY2020_Tx" SG_ 549 Power_Up_Chime_Modules 1;
BA_ "U_P702_MY2021_Tx" SG_ 549 Power_Up_Chime_Modules 1;
BA_ "ECGUsedRxSignal" SG_ 549 Power_Up_Chime_Modules 1;
BA_ "U_CD764_MY2022_Rx" SG_ 549 Power_Up_Chime_Modules 1;
BA_ "U_U55X_MY2022_Rx" SG_ 549 Power_Up_Chime_Modules 1;
BA_ "U_CD542_MY2021_Rx" SG_ 549 Power_Up_Chime_Modules 1;
BA_ "U_T6_MCA_MY2020_Rx" SG_ 549 Power_Up_Chime_Modules 1;
BA_ "U_P702_MY2021_Rx" SG_ 549 Power_Up_Chime_Modules 1;
BA_ "GenSigSendType" SG_ 549 Power_Up_Chime_Modules 3;
BA_ "WakeupSignal" SG_ 549 Power_Up_Chime_Modules 1;
BA_ "U_CD764_MY2022_Tx" SG_ 549 Chime_Source 1;
BA_ "U_U55X_MY2022_Tx" SG_ 549 Chime_Source 1;
BA_ "U_CD542_MY2021_Tx" SG_ 549 Chime_Source 1;
BA_ "U_T6_MCA_MY2020_Tx" SG_ 549 Chime_Source 1;
BA_ "U_P702_MY2021_Tx" SG_ 549 Chime_Source 1;
BA_ "U_CD764_MY2022_Rx" SG_ 549 Chime_Source 1;
BA_ "U_U55X_MY2022_Rx" SG_ 549 Chime_Source 1;
BA_ "U_CD542_MY2021_Rx" SG_ 549 Chime_Source 1;
BA_ "U_T6_MCA_MY2020_Rx" SG_ 549 Chime_Source 1;
BA_ "U_P702_MY2021_Rx" SG_ 549 Chime_Source 1;
BA_ "GenSigSendType" SG_ 549 Chime_Source 3;
BA_ "U_CD764_MY2022_Tx" SG_ 549 IPC_New_Attn_Event 1;
BA_ "U_U55X_MY2022_Tx" SG_ 549 IPC_New_Attn_Event 1;
BA_ "U_CD542_MY2021_Tx" SG_ 549 IPC_New_Attn_Event 1;
BA_ "U_T6_MCA_MY2020_Tx" SG_ 549 IPC_New_Attn_Event 1;
BA_ "U_P702_MY2021_Tx" SG_ 549 IPC_New_Attn_Event 1;
BA_ "U_CD764_MY2022_Rx" SG_ 549 IPC_New_Attn_Event 1;
BA_ "U_U55X_MY2022_Rx" SG_ 549 IPC_New_Attn_Event 1;
BA_ "U_CD542_MY2021_Rx" SG_ 549 IPC_New_Attn_Event 1;
BA_ "U_T6_MCA_MY2020_Rx" SG_ 549 IPC_New_Attn_Event 1;
BA_ "U_P702_MY2021_Rx" SG_ 549 IPC_New_Attn_Event 1;
BA_ "GenSigSendType" SG_ 549 IPC_New_Attn_Event 3;
BA_ "U_CD764_MY2022_Tx" SG_ 549 MetricActv_B_Dsply 1;
BA_ "U_U55X_MY2022_Tx" SG_ 549 MetricActv_B_Dsply 1;
BA_ "U_CD542_MY2021_Tx" SG_ 549 MetricActv_B_Dsply 1;
BA_ "U_T6_MCA_MY2020_Tx" SG_ 549 MetricActv_B_Dsply 1;
BA_ "U_P702_MY2021_Tx" SG_ 549 MetricActv_B_Dsply 1;
BA_ "U_U55X_MY2022_Rx" SG_ 549 MetricActv_B_Dsply 1;
BA_ "U_T6_MCA_MY2020_Rx" SG_ 549 MetricActv_B_Dsply 1;
BA_ "GenSigSendType" SG_ 549 MetricActv_B_Dsply 3;
BA_ "U_CD764_MY2022_Tx" SG_ 765 BalrSwtch_D_Stat 1;
BA_ "U_U55X_MY2022_Tx" SG_ 765 BalrSwtch_D_Stat 1;
BA_ "U_CD542_MY2021_Tx" SG_ 765 BalrSwtch_D_Stat 1;
BA_ "U_T6_MCA_MY2020_Tx" SG_ 765 BalrSwtch_D_Stat 1;
BA_ "U_P702_MY2021_Tx" SG_ 765 BalrSwtch_D_Stat 1;
BA_ "GenSigSendType" SG_ 765 BalrSwtch_D_Stat 3;
BA_ "GenSigStartValue" SG_ 765 BalrSwtch_D_Stat 1;
BA_ "GenSigStartValueInteger" SG_ 765 BalrSwtch_D_Stat 1;
BA_ "U_CD764_MY2022_Tx" SG_ 765 BalrMde_D_Rq 1;
BA_ "U_U55X_MY2022_Tx" SG_ 765 BalrMde_D_Rq 1;
BA_ "U_CD542_MY2021_Tx" SG_ 765 BalrMde_D_Rq 1;
BA_ "U_T6_MCA_MY2020_Tx" SG_ 765 BalrMde_D_Rq 1;
BA_ "U_P702_MY2021_Tx" SG_ 765 BalrMde_D_Rq 1;
BA_ "GenSigSendType" SG_ 765 BalrMde_D_Rq 3;
BA_ "U_CD764_MY2022_Tx" SG_ 765 RstrnOnPsngr_D_RqMnu 1;
BA_ "U_CD542_MY2021_Tx" SG_ 765 RstrnOnPsngr_D_RqMnu 1;
BA_ "U_T6_MCA_MY2020_Tx" SG_ 765 RstrnOnPsngr_D_RqMnu 1;
BA_ "GenSigSendType" SG_ 765 RstrnOnPsngr_D_RqMnu 3;
BA_ "U_CD764_MY2022_Tx" SG_ 765 WaitToStartLamp_D_Falt 1;
BA_ "U_CD542_MY2021_Tx" SG_ 765 WaitToStartLamp_D_Falt 1;
BA_ "U_T6_MCA_MY2020_Tx" SG_ 765 WaitToStartLamp_D_Falt 1;
BA_ "U_P702_MY2021_Tx" SG_ 765 WaitToStartLamp_D_Falt 1;
BA_ "GenSigSendType" SG_ 765 WaitToStartLamp_D_Falt 3;
BA_ "GenSigStartValue" SG_ 765 WaitToStartLamp_D_Falt 1;
BA_ "GenSigStartValueInteger" SG_ 765 WaitToStartLamp_D_Falt 1;
BA_ "U_CD764_MY2022_Tx" SG_ 765 EsaOn_B_Rq 1;
BA_ "U_U55X_MY2022_Tx" SG_ 765 EsaOn_B_Rq 1;
BA_ "U_CD542_MY2021_Tx" SG_ 765 EsaOn_B_Rq 1;
BA_ "U_T6_MCA_MY2020_Tx" SG_ 765 EsaOn_B_Rq 1;
BA_ "U_P702_MY2021_Tx" SG_ 765 EsaOn_B_Rq 1;
BA_ "GenSigSendType" SG_ 765 EsaOn_B_Rq 3;
BA_ "GenSigStartValue" SG_ 765 EsaOn_B_Rq 1;
BA_ "GenSigStartValueInteger" SG_ 765 EsaOn_B_Rq 1;
BA_ "U_CD764_MY2022_Tx" SG_ 765 BttOn_B_Rq 1;
BA_ "U_U55X_MY2022_Tx" SG_ 765 BttOn_B_Rq 1;
BA_ "U_CD542_MY2021_Tx" SG_ 765 BttOn_B_Rq 1;
BA_ "U_T6_MCA_MY2020_Tx" SG_ 765 BttOn_B_Rq 1;
BA_ "U_P702_MY2021_Tx" SG_ 765 BttOn_B_Rq 1;
BA_ "GenSigSendType" SG_ 765 BttOn_B_Rq 3;
BA_ "U_CD764_MY2022_Tx" SG_ 765 Btt_L_Actl 1;
BA_ "U_U55X_MY2022_Tx" SG_ 765 Btt_L_Actl 1;
BA_ "U_CD542_MY2021_Tx" SG_ 765 Btt_L_Actl 1;
BA_ "U_T6_MCA_MY2020_Tx" SG_ 765 Btt_L_Actl 1;
BA_ "U_P702_MY2021_Tx" SG_ 765 Btt_L_Actl 1;
BA_ "GenSigStartValue" SG_ 765 Btt_L_Actl 126;
BA_ "GenSigStartValueInteger" SG_ 765 Btt_L_Actl 126;
BA_ "U_CD764_MY2022_Tx" SG_ 765 RearDiffLck_D_RqArb 1;
BA_ "U_T6_MCA_MY2020_Tx" SG_ 765 RearDiffLck_D_RqArb 1;
BA_ "GenSigSendType" SG_ 765 RearDiffLck_D_RqArb 3;
BA_ "GenSigStartValue" SG_ 765 RearDiffLck_D_RqArb 3;
BA_ "GenSigStartValueInteger" SG_ 765 RearDiffLck_D_RqArb 3;
BA_ "U_CD764_MY2022_Tx" SG_ 765 AwdMde_D_RqArb 1;
BA_ "U_T6_MCA_MY2020_Tx" SG_ 765 AwdMde_D_RqArb 1;
BA_ "GenSigSendType" SG_ 765 AwdMde_D_RqArb 3;
BA_ "GenSigStartValue" SG_ 765 AwdMde_D_RqArb 5;
BA_ "GenSigStartValueInteger" SG_ 765 AwdMde_D_RqArb 5;
BA_ "U_CD764_MY2022_Tx" SG_ 765 SelDrvMdeTxtReset_B_Rq 1;
BA_ "U_U55X_MY2022_Tx" SG_ 765 SelDrvMdeTxtReset_B_Rq 1;
BA_ "U_CD542_MY2021_Tx" SG_ 765 SelDrvMdeTxtReset_B_Rq 1;
BA_ "U_T6_MCA_MY2020_Tx" SG_ 765 SelDrvMdeTxtReset_B_Rq 1;
BA_ "U_P702_MY2021_Tx" SG_ 765 SelDrvMdeTxtReset_B_Rq 1;
BA_ "GenSigSendType" SG_ 765 SelDrvMdeTxtReset_B_Rq 3;
BA_ "U_CD764_MY2022_Tx" SG_ 765 AutoTowAllw_D_RqMnu 1;
BA_ "U_U55X_MY2022_Tx" SG_ 765 AutoTowAllw_D_RqMnu 1;
BA_ "U_CD542_MY2021_Tx" SG_ 765 AutoTowAllw_D_RqMnu 1;
BA_ "U_T6_MCA_MY2020_Tx" SG_ 765 AutoTowAllw_D_RqMnu 1;
BA_ "GenSigSendType" SG_ 765 AutoTowAllw_D_RqMnu 3;
BA_ "U_CD764_MY2022_Tx" SG_ 765 DrvInputRequired_B_Rq 1;
BA_ "U_U55X_MY2022_Tx" SG_ 765 DrvInputRequired_B_Rq 1;
BA_ "U_CD542_MY2021_Tx" SG_ 765 DrvInputRequired_B_Rq 1;
BA_ "U_T6_MCA_MY2020_Tx" SG_ 765 DrvInputRequired_B_Rq 1;
BA_ "U_P702_MY2021_Tx" SG_ 765 DrvInputRequired_B_Rq 1;
BA_ "GenSigSendType" SG_ 765 DrvInputRequired_B_Rq 3;
BA_ "WakeupSignal" SG_ 765 DrvInputRequired_B_Rq 1;
BA_ "U_CD764_MY2022_Tx" SG_ 765 SelDrvMdeDsply_B_Avail 1;
BA_ "U_U55X_MY2022_Tx" SG_ 765 SelDrvMdeDsply_B_Avail 1;
BA_ "U_CD542_MY2021_Tx" SG_ 765 SelDrvMdeDsply_B_Avail 1;
BA_ "U_T6_MCA_MY2020_Tx" SG_ 765 SelDrvMdeDsply_B_Avail 1;
BA_ "U_P702_MY2021_Tx" SG_ 765 SelDrvMdeDsply_B_Avail 1;
BA_ "GenSigSendType" SG_ 765 SelDrvMdeDsply_B_Avail 3;
BA_ "U_CD764_MY2022_Tx" SG_ 765 EngExhMdeQuiet_D_Rq 1;
BA_ "U_T6_MCA_MY2020_Tx" SG_ 765 EngExhMdeQuiet_D_Rq 1;
BA_ "GenSigSendType" SG_ 765 EngExhMdeQuiet_D_Rq 3;
BA_ "GenSigStartValue" SG_ 765 EngExhMdeQuiet_D_Rq 2;
BA_ "GenSigStartValueInteger" SG_ 765 EngExhMdeQuiet_D_Rq 2;
BA_ "U_CD764_MY2022_Tx" SG_ 765 AirSusp_D_RqDrv 1;
BA_ "U_U55X_MY2022_Tx" SG_ 765 AirSusp_D_RqDrv 1;
BA_ "U_T6_MCA_MY2020_Tx" SG_ 765 AirSusp_D_RqDrv 1;
BA_ "GenSigSendType" SG_ 765 AirSusp_D_RqDrv 3;
BA_ "U_CD764_MY2022_Tx" SG_ 765 Mc_VehUntTrpCoUsrSel_St 1;
BA_ "U_U55X_MY2022_Tx" SG_ 765 Mc_VehUntTrpCoUsrSel_St 1;
BA_ "U_CD542_MY2021_Tx" SG_ 765 Mc_VehUntTrpCoUsrSel_St 1;
BA_ "U_T6_MCA_MY2020_Tx" SG_ 765 Mc_VehUntTrpCoUsrSel_St 1;
BA_ "U_P702_MY2021_Tx" SG_ 765 Mc_VehUntTrpCoUsrSel_St 1;
BA_ "U_P702_MY2021_Rx" SG_ 765 Mc_VehUntTrpCoUsrSel_St 1;
BA_ "U_CD542_MY2021_Rx" SG_ 765 Mc_VehUntTrpCoUsrSel_St 1;
BA_ "ECGUsedRxSignal" SG_ 765 Mc_VehUntTrpCoUsrSel_St 1;
BA_ "U_CD764_MY2022_Rx" SG_ 765 Mc_VehUntTrpCoUsrSel_St 1;
BA_ "U_U55X_MY2022_Rx" SG_ 765 Mc_VehUntTrpCoUsrSel_St 1;
BA_ "U_T6_MCA_MY2020_Rx" SG_ 765 Mc_VehUntTrpCoUsrSel_St 1;
BA_ "GenSigSendType" SG_ 765 Mc_VehUntTrpCoUsrSel_St 3;
BA_ "U_CD764_MY2022_Tx" SG_ 765 Mc_VehUnitTempUsrSel_St 1;
BA_ "U_U55X_MY2022_Tx" SG_ 765 Mc_VehUnitTempUsrSel_St 1;
BA_ "U_CD542_MY2021_Tx" SG_ 765 Mc_VehUnitTempUsrSel_St 1;
BA_ "U_T6_MCA_MY2020_Tx" SG_ 765 Mc_VehUnitTempUsrSel_St 1;
BA_ "U_P702_MY2021_Tx" SG_ 765 Mc_VehUnitTempUsrSel_St 1;
BA_ "U_CD542_MY2021_Rx" SG_ 765 Mc_VehUnitTempUsrSel_St 1;
BA_ "U_P702_MY2021_Rx" SG_ 765 Mc_VehUnitTempUsrSel_St 1;
BA_ "U_CD764_MY2022_Rx" SG_ 765 Mc_VehUnitTempUsrSel_St 1;
BA_ "U_T6_MCA_MY2020_Rx" SG_ 765 Mc_VehUnitTempUsrSel_St 1;
BA_ "U_U55X_MY2022_Rx" SG_ 765 Mc_VehUnitTempUsrSel_St 1;
BA_ "GenSigSendType" SG_ 765 Mc_VehUnitTempUsrSel_St 3;
BA_ "U_CD764_MY2022_Tx" SG_ 765 Mc_VehDayNightUsrSel_St 1;
BA_ "U_CD542_MY2021_Tx" SG_ 765 Mc_VehDayNightUsrSel_St 1;
BA_ "U_T6_MCA_MY2020_Tx" SG_ 765 Mc_VehDayNightUsrSel_St 1;
BA_ "U_U55X_MY2022_Rx" SG_ 765 Mc_VehDayNightUsrSel_St 1;
BA_ "U_CD542_MY2021_Rx" SG_ 765 Mc_VehDayNightUsrSel_St 1;
BA_ "U_T6_MCA_MY2020_Rx" SG_ 765 Mc_VehDayNightUsrSel_St 1;
BA_ "U_P702_MY2021_Rx" SG_ 765 Mc_VehDayNightUsrSel_St 1;
BA_ "GenSigSendType" SG_ 765 Mc_VehDayNightUsrSel_St 3;
BA_ "U_CD764_MY2022_Tx" SG_ 765 Mc_VehTimeFrmtUsrSel_St 1;
BA_ "U_U55X_MY2022_Tx" SG_ 765 Mc_VehTimeFrmtUsrSel_St 1;
BA_ "U_CD542_MY2021_Tx" SG_ 765 Mc_VehTimeFrmtUsrSel_St 1;
BA_ "U_T6_MCA_MY2020_Tx" SG_ 765 Mc_VehTimeFrmtUsrSel_St 1;
BA_ "U_CD542_MY2021_Rx" SG_ 765 Mc_VehTimeFrmtUsrSel_St 1;
BA_ "U_P702_MY2021_Rx" SG_ 765 Mc_VehTimeFrmtUsrSel_St 1;
BA_ "U_CD764_MY2022_Rx" SG_ 765 Mc_VehTimeFrmtUsrSel_St 1;
BA_ "U_T6_MCA_MY2020_Rx" SG_ 765 Mc_VehTimeFrmtUsrSel_St 1;
BA_ "U_U55X_MY2022_Rx" SG_ 765 Mc_VehTimeFrmtUsrSel_St 1;
BA_ "GenSigSendType" SG_ 765 Mc_VehTimeFrmtUsrSel_St 3;
BA_ "U_CD764_MY2022_Tx" SG_ 765 Mc_VehThemeUsrSel_St 1;
BA_ "U_CD542_MY2021_Tx" SG_ 765 Mc_VehThemeUsrSel_St 1;
BA_ "U_T6_MCA_MY2020_Tx" SG_ 765 Mc_VehThemeUsrSel_St 1;
BA_ "U_U55X_MY2022_Rx" SG_ 765 Mc_VehThemeUsrSel_St 1;
BA_ "U_CD542_MY2021_Rx" SG_ 765 Mc_VehThemeUsrSel_St 1;
BA_ "U_T6_MCA_MY2020_Rx" SG_ 765 Mc_VehThemeUsrSel_St 1;
BA_ "U_P702_MY2021_Rx" SG_ 765 Mc_VehThemeUsrSel_St 1;
BA_ "GenSigSendType" SG_ 765 Mc_VehThemeUsrSel_St 3;
BA_ "U_CD764_MY2022_Tx" SG_ 765 Mc_VehLangUsrSel_St 1;
BA_ "U_U55X_MY2022_Tx" SG_ 765 Mc_VehLangUsrSel_St 1;
BA_ "U_CD542_MY2021_Tx" SG_ 765 Mc_VehLangUsrSel_St 1;
BA_ "U_T6_MCA_MY2020_Tx" SG_ 765 Mc_VehLangUsrSel_St 1;
BA_ "U_P702_MY2021_Tx" SG_ 765 Mc_VehLangUsrSel_St 1;
BA_ "U_CD764_MY2022_Rx" SG_ 765 Mc_VehLangUsrSel_St 1;
BA_ "U_U55X_MY2022_Rx" SG_ 765 Mc_VehLangUsrSel_St 1;
BA_ "U_CD542_MY2021_Rx" SG_ 765 Mc_VehLangUsrSel_St 1;
BA_ "U_T6_MCA_MY2020_Rx" SG_ 765 Mc_VehLangUsrSel_St 1;
BA_ "U_P702_MY2021_Rx" SG_ 765 Mc_VehLangUsrSel_St 1;
BA_ "GenSigSendType" SG_ 765 Mc_VehLangUsrSel_St 3;
BA_ "U_CD764_MY2022_Tx" SG_ 765 AwdRnge_D_ActlIpc 1;
BA_ "U_U55X_MY2022_Tx" SG_ 765 AwdRnge_D_ActlIpc 1;
BA_ "U_T6_MCA_MY2020_Tx" SG_ 765 AwdRnge_D_ActlIpc 1;
BA_ "U_P702_MY2021_Tx" SG_ 765 AwdRnge_D_ActlIpc 1;
BA_ "GenSigSendType" SG_ 765 AwdRnge_D_ActlIpc 3;
BA_ "GenSigStartValue" SG_ 765 AwdRnge_D_ActlIpc 7;
BA_ "GenSigStartValueInteger" SG_ 765 AwdRnge_D_ActlIpc 7;
BA_ "U_CD764_MY2022_Tx" SG_ 765 AwdDrvMde_D_Rq 1;
BA_ "U_CD542_MY2021_Tx" SG_ 765 AwdDrvMde_D_Rq 1;
BA_ "U_T6_MCA_MY2020_Tx" SG_ 765 AwdDrvMde_D_Rq 1;
BA_ "GenSigSendType" SG_ 765 AwdDrvMde_D_Rq 3;
BA_ "U_CD764_MY2022_Tx" SG_ 765 EngExhMdeQuiet_D2_Rq 1;
BA_ "U_T6_MCA_MY2020_Tx" SG_ 765 EngExhMdeQuiet_D2_Rq 1;
BA_ "GenSigSendType" SG_ 765 EngExhMdeQuiet_D2_Rq 3;
BA_ "U_CD764_MY2022_Tx" SG_ 765 BrkLineLck_D_Rq 1;
BA_ "U_T6_MCA_MY2020_Tx" SG_ 765 BrkLineLck_D_Rq 1;
BA_ "GenSigSendType" SG_ 765 BrkLineLck_D_Rq 3;
BA_ "U_CD764_MY2022_Tx" SG_ 765 EdmSailMde_B_RqDrv 1;
BA_ "U_U55X_MY2022_Tx" SG_ 765 EdmSailMde_B_RqDrv 1;
BA_ "U_CD542_MY2021_Tx" SG_ 765 EdmSailMde_B_RqDrv 1;
BA_ "U_T6_MCA_MY2020_Tx" SG_ 765 EdmSailMde_B_RqDrv 1;
BA_ "GenSigSendType" SG_ 765 EdmSailMde_B_RqDrv 3;
BA_ "U_CD764_MY2022_Tx" SG_ 765 Running_Board_Cmd 1;
BA_ "U_U55X_MY2022_Tx" SG_ 765 Running_Board_Cmd 1;
BA_ "U_T6_MCA_MY2020_Tx" SG_ 765 Running_Board_Cmd 1;
BA_ "GenSigSendType" SG_ 765 Running_Board_Cmd 3;
BA_ "U_U55X_MY2022_Tx" SG_ 508 Mc_DB1GetInfStartInd_Rq 1;
BA_ "U_T6_MCA_MY2020_Tx" SG_ 508 Mc_DB1GetInfStartInd_Rq 1;
BA_ "U_U55X_MY2022_Rx" SG_ 508 Mc_DB1GetInfStartInd_Rq 1;
BA_ "U_T6_MCA_MY2020_Rx" SG_ 508 Mc_DB1GetInfStartInd_Rq 1;
BA_ "GenSigSendType" SG_ 508 Mc_DB1GetInfStartInd_Rq 1;
BA_ "U_U55X_MY2022_Tx" SG_ 508 Mc_DB1GtInfNbrOfItms_Rq 1;
BA_ "U_T6_MCA_MY2020_Tx" SG_ 508 Mc_DB1GtInfNbrOfItms_Rq 1;
BA_ "U_U55X_MY2022_Rx" SG_ 508 Mc_DB1GtInfNbrOfItms_Rq 1;
BA_ "U_T6_MCA_MY2020_Rx" SG_ 508 Mc_DB1GtInfNbrOfItms_Rq 1;
BA_ "U_U55X_MY2022_Tx" SG_ 508 Mc_DB1GetInfSetConf_Rq 1;
BA_ "U_T6_MCA_MY2020_Tx" SG_ 508 Mc_DB1GetInfSetConf_Rq 1;
BA_ "U_U55X_MY2022_Rx" SG_ 508 Mc_DB1GetInfSetConf_Rq 1;
BA_ "U_T6_MCA_MY2020_Rx" SG_ 508 Mc_DB1GetInfSetConf_Rq 1;
BA_ "U_U55X_MY2022_Tx" SG_ 508 Mc_DB1GetInfSetFilt3_Rq 1;
BA_ "U_T6_MCA_MY2020_Tx" SG_ 508 Mc_DB1GetInfSetFilt3_Rq 1;
BA_ "U_U55X_MY2022_Rx" SG_ 508 Mc_DB1GetInfSetFilt3_Rq 1;
BA_ "U_T6_MCA_MY2020_Rx" SG_ 508 Mc_DB1GetInfSetFilt3_Rq 1;
BA_ "U_U55X_MY2022_Tx" SG_ 508 Mc_DB1GetInfSetFilt2_Rq 1;
BA_ "U_T6_MCA_MY2020_Tx" SG_ 508 Mc_DB1GetInfSetFilt2_Rq 1;
BA_ "U_U55X_MY2022_Rx" SG_ 508 Mc_DB1GetInfSetFilt2_Rq 1;
BA_ "U_T6_MCA_MY2020_Rx" SG_ 508 Mc_DB1GetInfSetFilt2_Rq 1;
BA_ "U_U55X_MY2022_Tx" SG_ 508 Mc_DB1GetInfSetFilt1_Rq 1;
BA_ "U_T6_MCA_MY2020_Tx" SG_ 508 Mc_DB1GetInfSetFilt1_Rq 1;
BA_ "U_U55X_MY2022_Rx" SG_ 508 Mc_DB1GetInfSetFilt1_Rq 1;
BA_ "U_T6_MCA_MY2020_Rx" SG_ 508 Mc_DB1GetInfSetFilt1_Rq 1;
BA_ "U_U55X_MY2022_Tx" SG_ 507 Mc_DB1SetTrkItmIndex_Rq 1;
BA_ "U_T6_MCA_MY2020_Tx" SG_ 507 Mc_DB1SetTrkItmIndex_Rq 1;
BA_ "U_U55X_MY2022_Rx" SG_ 507 Mc_DB1SetTrkItmIndex_Rq 1;
BA_ "U_T6_MCA_MY2020_Rx" SG_ 507 Mc_DB1SetTrkItmIndex_Rq 1;
BA_ "GenSigSendType" SG_ 507 Mc_DB1SetTrkItmIndex_Rq 1;
BA_ "U_U55X_MY2022_Tx" SG_ 507 Mc_DB1SetTrkSetConf_Rq 1;
BA_ "U_T6_MCA_MY2020_Tx" SG_ 507 Mc_DB1SetTrkSetConf_Rq 1;
BA_ "U_U55X_MY2022_Rx" SG_ 507 Mc_DB1SetTrkSetConf_Rq 1;
BA_ "U_T6_MCA_MY2020_Rx" SG_ 507 Mc_DB1SetTrkSetConf_Rq 1;
BA_ "U_U55X_MY2022_Tx" SG_ 507 Mc_DB1SetTrkSetFilt3_Rq 1;
BA_ "U_T6_MCA_MY2020_Tx" SG_ 507 Mc_DB1SetTrkSetFilt3_Rq 1;
BA_ "U_U55X_MY2022_Rx" SG_ 507 Mc_DB1SetTrkSetFilt3_Rq 1;
BA_ "U_T6_MCA_MY2020_Rx" SG_ 507 Mc_DB1SetTrkSetFilt3_Rq 1;
BA_ "U_U55X_MY2022_Tx" SG_ 507 Mc_DB1SetTrkSetFilt2_Rq 1;
BA_ "U_T6_MCA_MY2020_Tx" SG_ 507 Mc_DB1SetTrkSetFilt2_Rq 1;
BA_ "U_U55X_MY2022_Rx" SG_ 507 Mc_DB1SetTrkSetFilt2_Rq 1;
BA_ "U_T6_MCA_MY2020_Rx" SG_ 507 Mc_DB1SetTrkSetFilt2_Rq 1;
BA_ "U_U55X_MY2022_Tx" SG_ 507 Mc_DB1SetTrkSetFilt1_Rq 1;
BA_ "U_T6_MCA_MY2020_Tx" SG_ 507 Mc_DB1SetTrkSetFilt1_Rq 1;
BA_ "U_U55X_MY2022_Rx" SG_ 507 Mc_DB1SetTrkSetFilt1_Rq 1;
BA_ "U_T6_MCA_MY2020_Rx" SG_ 507 Mc_DB1SetTrkSetFilt1_Rq 1;
BA_ "U_U55X_MY2022_Tx" SG_ 506 Mc_AudioSourceSel3_Rq 1;
BA_ "U_T6_MCA_MY2020_Tx" SG_ 506 Mc_AudioSourceSel3_Rq 1;
BA_ "U_U55X_MY2022_Rx" SG_ 506 Mc_AudioSourceSel3_Rq 1;
BA_ "U_T6_MCA_MY2020_Rx" SG_ 506 Mc_AudioSourceSel3_Rq 1;
BA_ "GenSigSendType" SG_ 506 Mc_AudioSourceSel3_Rq 3;
BA_ "U_U55X_MY2022_Tx" SG_ 506 Mc_PlayFrstTrInFldr_Rq 1;
BA_ "U_T6_MCA_MY2020_Tx" SG_ 506 Mc_PlayFrstTrInFldr_Rq 1;
BA_ "U_U55X_MY2022_Rx" SG_ 506 Mc_PlayFrstTrInFldr_Rq 1;
BA_ "U_T6_MCA_MY2020_Rx" SG_ 506 Mc_PlayFrstTrInFldr_Rq 1;
BA_ "U_U55X_MY2022_Tx" SG_ 506 Mc_ItemIndex_Rq 1;
BA_ "U_T6_MCA_MY2020_Tx" SG_ 506 Mc_ItemIndex_Rq 1;
BA_ "U_U55X_MY2022_Rx" SG_ 506 Mc_ItemIndex_Rq 1;
BA_ "U_T6_MCA_MY2020_Rx" SG_ 506 Mc_ItemIndex_Rq 1;
BA_ "U_U55X_MY2022_Tx" SG_ 506 Mc_FolderNumber3_Rq 1;
BA_ "U_T6_MCA_MY2020_Tx" SG_ 506 Mc_FolderNumber3_Rq 1;
BA_ "U_U55X_MY2022_Rx" SG_ 506 Mc_FolderNumber3_Rq 1;
BA_ "U_T6_MCA_MY2020_Rx" SG_ 506 Mc_FolderNumber3_Rq 1;
BA_ "U_CD764_MY2022_Tx" SG_ 505 Mc_AudioSourceSel2_Rq 1;
BA_ "U_U55X_MY2022_Tx" SG_ 505 Mc_AudioSourceSel2_Rq 1;
BA_ "U_T6_MCA_MY2020_Tx" SG_ 505 Mc_AudioSourceSel2_Rq 1;
BA_ "U_U55X_MY2022_Rx" SG_ 505 Mc_AudioSourceSel2_Rq 1;
BA_ "U_T6_MCA_MY2020_Rx" SG_ 505 Mc_AudioSourceSel2_Rq 1;
BA_ "GenSigSendType" SG_ 505 Mc_AudioSourceSel2_Rq 3;
BA_ "U_CD764_MY2022_Tx" SG_ 505 Mc_StartItemIndexRq 1;
BA_ "U_U55X_MY2022_Tx" SG_ 505 Mc_StartItemIndexRq 1;
BA_ "U_T6_MCA_MY2020_Tx" SG_ 505 Mc_StartItemIndexRq 1;
BA_ "U_U55X_MY2022_Rx" SG_ 505 Mc_StartItemIndexRq 1;
BA_ "U_T6_MCA_MY2020_Rx" SG_ 505 Mc_StartItemIndexRq 1;
BA_ "U_CD764_MY2022_Tx" SG_ 505 Mc_NbrOfItems2_Rq 1;
BA_ "U_U55X_MY2022_Tx" SG_ 505 Mc_NbrOfItems2_Rq 1;
BA_ "U_T6_MCA_MY2020_Tx" SG_ 505 Mc_NbrOfItems2_Rq 1;
BA_ "U_U55X_MY2022_Rx" SG_ 505 Mc_NbrOfItems2_Rq 1;
BA_ "U_T6_MCA_MY2020_Rx" SG_ 505 Mc_NbrOfItems2_Rq 1;
BA_ "U_CD764_MY2022_Tx" SG_ 505 Mc_ItemNameLength2_Rq 1;
BA_ "U_U55X_MY2022_Tx" SG_ 505 Mc_ItemNameLength2_Rq 1;
BA_ "U_T6_MCA_MY2020_Tx" SG_ 505 Mc_ItemNameLength2_Rq 1;
BA_ "U_U55X_MY2022_Rx" SG_ 505 Mc_ItemNameLength2_Rq 1;
BA_ "U_T6_MCA_MY2020_Rx" SG_ 505 Mc_ItemNameLength2_Rq 1;
BA_ "U_CD764_MY2022_Tx" SG_ 505 Mc_CutItem2_Rq 1;
BA_ "U_U55X_MY2022_Tx" SG_ 505 Mc_CutItem2_Rq 1;
BA_ "U_T6_MCA_MY2020_Tx" SG_ 505 Mc_CutItem2_Rq 1;
BA_ "U_U55X_MY2022_Rx" SG_ 505 Mc_CutItem2_Rq 1;
BA_ "U_T6_MCA_MY2020_Rx" SG_ 505 Mc_CutItem2_Rq 1;
BA_ "U_CD764_MY2022_Tx" SG_ 505 Mc_FolderNumber2_Rq 1;
BA_ "U_U55X_MY2022_Tx" SG_ 505 Mc_FolderNumber2_Rq 1;
BA_ "U_T6_MCA_MY2020_Tx" SG_ 505 Mc_FolderNumber2_Rq 1;
BA_ "U_U55X_MY2022_Rx" SG_ 505 Mc_FolderNumber2_Rq 1;
BA_ "U_T6_MCA_MY2020_Rx" SG_ 505 Mc_FolderNumber2_Rq 1;
BA_ "U_CD764_MY2022_Tx" SG_ 505 Mc_FolderContent_Rq 1;
BA_ "U_U55X_MY2022_Tx" SG_ 505 Mc_FolderContent_Rq 1;
BA_ "U_T6_MCA_MY2020_Tx" SG_ 505 Mc_FolderContent_Rq 1;
BA_ "U_U55X_MY2022_Rx" SG_ 505 Mc_FolderContent_Rq 1;
BA_ "U_T6_MCA_MY2020_Rx" SG_ 505 Mc_FolderContent_Rq 1;
BA_ "U_CD764_MY2022_Tx" SG_ 403 McLangSel2_Rq 1;
BA_ "U_U55X_MY2022_Tx" SG_ 403 McLangSel2_Rq 1;
BA_ "U_CD542_MY2021_Tx" SG_ 403 McLangSel2_Rq 1;
BA_ "U_T6_MCA_MY2020_Tx" SG_ 403 McLangSel2_Rq 1;
BA_ "U_CD764_MY2022_Rx" SG_ 403 McLangSel2_Rq 1;
BA_ "U_CD542_MY2021_Rx" SG_ 403 McLangSel2_Rq 1;
BA_ "U_U55X_MY2022_Rx" SG_ 403 McLangSel2_Rq 1;
BA_ "U_T6_MCA_MY2020_Rx" SG_ 403 McLangSel2_Rq 1;
BA_ "U_P702_MY2021_Rx" SG_ 403 McLangSel2_Rq 1;
BA_ "GenSigSendType" SG_ 403 McLangSel2_Rq 3;
BA_ "U_CD764_MY2022_Tx" SG_ 403 DealerCall_B_Rq 1;
BA_ "U_U55X_MY2022_Tx" SG_ 403 DealerCall_B_Rq 1;
BA_ "U_CD542_MY2021_Tx" SG_ 403 DealerCall_B_Rq 1;
BA_ "U_T6_MCA_MY2020_Tx" SG_ 403 DealerCall_B_Rq 1;
BA_ "U_CD542_MY2021_Rx" SG_ 403 DealerCall_B_Rq 1;
BA_ "U_U55X_MY2022_Rx" SG_ 403 DealerCall_B_Rq 1;
BA_ "U_T6_MCA_MY2020_Rx" SG_ 403 DealerCall_B_Rq 1;
BA_ "GenSigSendType" SG_ 403 DealerCall_B_Rq 3;
BA_ "U_CD764_MY2022_Tx" SG_ 403 Mc_RepeatGuidance_Rq 1;
BA_ "U_CD542_MY2021_Tx" SG_ 403 Mc_RepeatGuidance_Rq 1;
BA_ "U_T6_MCA_MY2020_Tx" SG_ 403 Mc_RepeatGuidance_Rq 1;
BA_ "U_CD764_MY2022_Rx" SG_ 403 Mc_RepeatGuidance_Rq 1;
BA_ "U_U55X_MY2022_Rx" SG_ 403 Mc_RepeatGuidance_Rq 1;
BA_ "U_CD542_MY2021_Rx" SG_ 403 Mc_RepeatGuidance_Rq 1;
BA_ "U_T6_MCA_MY2020_Rx" SG_ 403 Mc_RepeatGuidance_Rq 1;
BA_ "U_P702_MY2021_Rx" SG_ 403 Mc_RepeatGuidance_Rq 1;
BA_ "GenSigSendType" SG_ 403 Mc_RepeatGuidance_Rq 3;
BA_ "U_CD764_MY2022_Tx" SG_ 403 Mc_CancelRoute_Rq 1;
BA_ "U_U55X_MY2022_Tx" SG_ 403 Mc_CancelRoute_Rq 1;
BA_ "U_CD542_MY2021_Tx" SG_ 403 Mc_CancelRoute_Rq 1;
BA_ "U_T6_MCA_MY2020_Tx" SG_ 403 Mc_CancelRoute_Rq 1;
BA_ "U_CD764_MY2022_Rx" SG_ 403 Mc_CancelRoute_Rq 1;
BA_ "U_U55X_MY2022_Rx" SG_ 403 Mc_CancelRoute_Rq 1;
BA_ "U_CD542_MY2021_Rx" SG_ 403 Mc_CancelRoute_Rq 1;
BA_ "U_T6_MCA_MY2020_Rx" SG_ 403 Mc_CancelRoute_Rq 1;
BA_ "U_P702_MY2021_Rx" SG_ 403 Mc_CancelRoute_Rq 1;
BA_ "GenSigSendType" SG_ 403 Mc_CancelRoute_Rq 3;
BA_ "U_CD764_MY2022_Tx" SG_ 403 Mc_CancelCurrWaypt_Rq 1;
BA_ "U_CD542_MY2021_Tx" SG_ 403 Mc_CancelCurrWaypt_Rq 1;
BA_ "U_T6_MCA_MY2020_Tx" SG_ 403 Mc_CancelCurrWaypt_Rq 1;
BA_ "U_CD764_MY2022_Rx" SG_ 403 Mc_CancelCurrWaypt_Rq 1;
BA_ "U_U55X_MY2022_Rx" SG_ 403 Mc_CancelCurrWaypt_Rq 1;
BA_ "U_CD542_MY2021_Rx" SG_ 403 Mc_CancelCurrWaypt_Rq 1;
BA_ "U_T6_MCA_MY2020_Rx" SG_ 403 Mc_CancelCurrWaypt_Rq 1;
BA_ "U_P702_MY2021_Rx" SG_ 403 Mc_CancelCurrWaypt_Rq 1;
BA_ "GenSigSendType" SG_ 403 Mc_CancelCurrWaypt_Rq 3;
BA_ "U_CD764_MY2022_Tx" SG_ 403 Mc_TextMessage_Rq 1;
BA_ "U_CD542_MY2021_Tx" SG_ 403 Mc_TextMessage_Rq 1;
BA_ "U_T6_MCA_MY2020_Tx" SG_ 403 Mc_TextMessage_Rq 1;
BA_ "U_CD542_MY2021_Rx" SG_ 403 Mc_TextMessage_Rq 1;
BA_ "U_U55X_MY2022_Rx" SG_ 403 Mc_TextMessage_Rq 1;
BA_ "U_T6_MCA_MY2020_Rx" SG_ 403 Mc_TextMessage_Rq 1;
BA_ "U_P702_MY2021_Rx" SG_ 403 Mc_TextMessage_Rq 1;
BA_ "GenSigSendType" SG_ 403 Mc_TextMessage_Rq 3;
BA_ "U_CD764_MY2022_Tx" SG_ 403 Mc_BTInCallOptions_Rq 1;
BA_ "U_U55X_MY2022_Tx" SG_ 403 Mc_BTInCallOptions_Rq 1;
BA_ "U_CD542_MY2021_Tx" SG_ 403 Mc_BTInCallOptions_Rq 1;
BA_ "U_T6_MCA_MY2020_Tx" SG_ 403 Mc_BTInCallOptions_Rq 1;
BA_ "U_U55X_MY2022_Rx" SG_ 403 Mc_BTInCallOptions_Rq 1;
BA_ "U_CD542_MY2021_Rx" SG_ 403 Mc_BTInCallOptions_Rq 1;
BA_ "U_T6_MCA_MY2020_Rx" SG_ 403 Mc_BTInCallOptions_Rq 1;
BA_ "U_P702_MY2021_Rx" SG_ 403 Mc_BTInCallOptions_Rq 1;
BA_ "GenSigSendType" SG_ 403 Mc_BTInCallOptions_Rq 3;
BA_ "U_CD764_MY2022_Tx" SG_ 403 Mc_PhMicrophoneMute_Rq 1;
BA_ "U_U55X_MY2022_Tx" SG_ 403 Mc_PhMicrophoneMute_Rq 1;
BA_ "U_CD542_MY2021_Tx" SG_ 403 Mc_PhMicrophoneMute_Rq 1;
BA_ "U_T6_MCA_MY2020_Tx" SG_ 403 Mc_PhMicrophoneMute_Rq 1;
BA_ "U_CD764_MY2022_Rx" SG_ 403 Mc_PhMicrophoneMute_Rq 1;
BA_ "U_U55X_MY2022_Rx" SG_ 403 Mc_PhMicrophoneMute_Rq 1;
BA_ "U_CD542_MY2021_Rx" SG_ 403 Mc_PhMicrophoneMute_Rq 1;
BA_ "U_T6_MCA_MY2020_Rx" SG_ 403 Mc_PhMicrophoneMute_Rq 1;
BA_ "U_P702_MY2021_Rx" SG_ 403 Mc_PhMicrophoneMute_Rq 1;
BA_ "GenSigSendType" SG_ 403 Mc_PhMicrophoneMute_Rq 3;
BA_ "U_CD764_MY2022_Tx" SG_ 403 Mc_LangSel_Rq 1;
BA_ "U_U55X_MY2022_Tx" SG_ 403 Mc_LangSel_Rq 1;
BA_ "U_CD542_MY2021_Tx" SG_ 403 Mc_LangSel_Rq 1;
BA_ "U_T6_MCA_MY2020_Tx" SG_ 403 Mc_LangSel_Rq 1;
BA_ "U_P702_MY2021_Tx" SG_ 403 Mc_LangSel_Rq 1;
BA_ "U_CD764_MY2022_Rx" SG_ 403 Mc_LangSel_Rq 1;
BA_ "U_U55X_MY2022_Rx" SG_ 403 Mc_LangSel_Rq 1;
BA_ "U_CD542_MY2021_Rx" SG_ 403 Mc_LangSel_Rq 1;
BA_ "U_T6_MCA_MY2020_Rx" SG_ 403 Mc_LangSel_Rq 1;
BA_ "U_P702_MY2021_Rx" SG_ 403 Mc_LangSel_Rq 1;
BA_ "GenSigSendType" SG_ 403 Mc_LangSel_Rq 3;
BA_ "U_CD764_MY2022_Tx" SG_ 401 Bezel_Beeps_Rq 1;
BA_ "U_U55X_MY2022_Tx" SG_ 401 Bezel_Beeps_Rq 1;
BA_ "U_CD542_MY2021_Tx" SG_ 401 Bezel_Beeps_Rq 1;
BA_ "U_T6_MCA_MY2020_Tx" SG_ 401 Bezel_Beeps_Rq 1;
BA_ "U_P702_MY2021_Tx" SG_ 401 Bezel_Beeps_Rq 1;
BA_ "GenSigSendType" SG_ 401 Bezel_Beeps_Rq 3;
BA_ "WakeupSignal" SG_ 401 Bezel_Beeps_Rq 1;
BA_ "U_CD764_MY2022_Tx" SG_ 401 Disp_VehUntTripCoUsrSel 1;
BA_ "U_U55X_MY2022_Tx" SG_ 401 Disp_VehUntTripCoUsrSel 1;
BA_ "U_CD542_MY2021_Tx" SG_ 401 Disp_VehUntTripCoUsrSel 1;
BA_ "U_T6_MCA_MY2020_Tx" SG_ 401 Disp_VehUntTripCoUsrSel 1;
BA_ "U_P702_MY2021_Tx" SG_ 401 Disp_VehUntTripCoUsrSel 1;
BA_ "U_CD764_MY2022_Rx" SG_ 401 Disp_VehUntTripCoUsrSel 1;
BA_ "U_U55X_MY2022_Rx" SG_ 401 Disp_VehUntTripCoUsrSel 1;
BA_ "U_CD542_MY2021_Rx" SG_ 401 Disp_VehUntTripCoUsrSel 1;
BA_ "U_T6_MCA_MY2020_Rx" SG_ 401 Disp_VehUntTripCoUsrSel 1;
BA_ "U_P702_MY2021_Rx" SG_ 401 Disp_VehUntTripCoUsrSel 1;
BA_ "GenSigSendType" SG_ 401 Disp_VehUntTripCoUsrSel 3;
BA_ "GenSigStartValue" SG_ 401 Disp_VehUntTripCoUsrSel 3;
BA_ "GenSigStartValueInteger" SG_ 401 Disp_VehUntTripCoUsrSel 3;
BA_ "U_CD764_MY2022_Tx" SG_ 401 Disp_VehUnitTempUsrSel 1;
BA_ "U_U55X_MY2022_Tx" SG_ 401 Disp_VehUnitTempUsrSel 1;
BA_ "U_CD542_MY2021_Tx" SG_ 401 Disp_VehUnitTempUsrSel 1;
BA_ "U_T6_MCA_MY2020_Tx" SG_ 401 Disp_VehUnitTempUsrSel 1;
BA_ "U_P702_MY2021_Tx" SG_ 401 Disp_VehUnitTempUsrSel 1;
BA_ "U_CD764_MY2022_Rx" SG_ 401 Disp_VehUnitTempUsrSel 1;
BA_ "U_U55X_MY2022_Rx" SG_ 401 Disp_VehUnitTempUsrSel 1;
BA_ "U_CD542_MY2021_Rx" SG_ 401 Disp_VehUnitTempUsrSel 1;
BA_ "U_T6_MCA_MY2020_Rx" SG_ 401 Disp_VehUnitTempUsrSel 1;
BA_ "U_P702_MY2021_Rx" SG_ 401 Disp_VehUnitTempUsrSel 1;
BA_ "GenSigSendType" SG_ 401 Disp_VehUnitTempUsrSel 3;
BA_ "GenSigStartValue" SG_ 401 Disp_VehUnitTempUsrSel 3;
BA_ "GenSigStartValueInteger" SG_ 401 Disp_VehUnitTempUsrSel 3;
BA_ "U_CD764_MY2022_Tx" SG_ 401 Disp_LangSel_Rq 1;
BA_ "U_U55X_MY2022_Tx" SG_ 401 Disp_LangSel_Rq 1;
BA_ "U_CD542_MY2021_Tx" SG_ 401 Disp_LangSel_Rq 1;
BA_ "U_T6_MCA_MY2020_Tx" SG_ 401 Disp_LangSel_Rq 1;
BA_ "U_P702_MY2021_Tx" SG_ 401 Disp_LangSel_Rq 1;
BA_ "U_CD764_MY2022_Rx" SG_ 401 Disp_LangSel_Rq 1;
BA_ "U_U55X_MY2022_Rx" SG_ 401 Disp_LangSel_Rq 1;
BA_ "U_CD542_MY2021_Rx" SG_ 401 Disp_LangSel_Rq 1;
BA_ "U_T6_MCA_MY2020_Rx" SG_ 401 Disp_LangSel_Rq 1;
BA_ "U_P702_MY2021_Rx" SG_ 401 Disp_LangSel_Rq 1;
BA_ "GenSigSendType" SG_ 401 Disp_LangSel_Rq 3;
BA_ "U_CD764_MY2022_Tx" SG_ 401 Disp_LangSel2_Rq 1;
BA_ "U_U55X_MY2022_Tx" SG_ 401 Disp_LangSel2_Rq 1;
BA_ "U_CD542_MY2021_Tx" SG_ 401 Disp_LangSel2_Rq 1;
BA_ "U_T6_MCA_MY2020_Tx" SG_ 401 Disp_LangSel2_Rq 1;
BA_ "U_P702_MY2021_Tx" SG_ 401 Disp_LangSel2_Rq 1;
BA_ "U_CD764_MY2022_Rx" SG_ 401 Disp_LangSel2_Rq 1;
BA_ "U_U55X_MY2022_Rx" SG_ 401 Disp_LangSel2_Rq 1;
BA_ "U_CD542_MY2021_Rx" SG_ 401 Disp_LangSel2_Rq 1;
BA_ "U_T6_MCA_MY2020_Rx" SG_ 401 Disp_LangSel2_Rq 1;
BA_ "U_P702_MY2021_Rx" SG_ 401 Disp_LangSel2_Rq 1;
BA_ "GenSigSendType" SG_ 401 Disp_LangSel2_Rq 3;
BA_ "U_CD764_MY2022_Rx" SG_ 1143 ConsTipUnitPt_D_Dsply 1;
BA_ "U_U55X_MY2022_Rx" SG_ 1143 ConsTipUnitPt_D_Dsply 1;
BA_ "U_CD542_MY2021_Rx" SG_ 1143 ConsTipUnitPt_D_Dsply 1;
BA_ "U_T6_MCA_MY2020_Rx" SG_ 1143 ConsTipUnitPt_D_Dsply 1;
BA_ "U_P702_MY2021_Rx" SG_ 1143 ConsTipUnitPt_D_Dsply 1;
BA_ "GenSigStartValue" SG_ 1143 ConsTipTot_Pc_Dsply 1022;
BA_ "GenSigStartValueInteger" SG_ 1143 ConsTipTot_Pc_Dsply 1022;
BA_ "U_U55X_MY2022_Rx" SG_ 1143 ChrgCompltMsgTxt_D_Rq 1;
BA_ "U_CD542_MY2021_Rx" SG_ 1143 ChrgCompltMsgTxt_D_Rq 1;
BA_ "U_T6_MCA_MY2020_Rx" SG_ 1143 ChrgCompltMsgTxt_D_Rq 1;
BA_ "U_P702_MY2021_Rx" SG_ 1143 ChrgCompltMsgTxt_D_Rq 1;
BA_ "U_CD764_MY2022_Rx" SG_ 1142 ConsTipV_No_Dsply 1;
BA_ "U_U55X_MY2022_Rx" SG_ 1142 ConsTipV_No_Dsply 1;
BA_ "U_CD542_MY2021_Rx" SG_ 1142 ConsTipV_No_Dsply 1;
BA_ "U_T6_MCA_MY2020_Rx" SG_ 1142 ConsTipV_No_Dsply 1;
BA_ "U_P702_MY2021_Rx" SG_ 1142 ConsTipV_No_Dsply 1;
BA_ "U_CD764_MY2022_Rx" SG_ 1142 ConsTipMsg3_D_Dsply 1;
BA_ "U_U55X_MY2022_Rx" SG_ 1142 ConsTipMsg3_D_Dsply 1;
BA_ "U_CD542_MY2021_Rx" SG_ 1142 ConsTipMsg3_D_Dsply 1;
BA_ "U_T6_MCA_MY2020_Rx" SG_ 1142 ConsTipMsg3_D_Dsply 1;
BA_ "U_P702_MY2021_Rx" SG_ 1142 ConsTipMsg3_D_Dsply 1;
BA_ "U_CD764_MY2022_Rx" SG_ 1142 ConsTipMsg2_D_Dsply 1;
BA_ "U_U55X_MY2022_Rx" SG_ 1142 ConsTipMsg2_D_Dsply 1;
BA_ "U_CD542_MY2021_Rx" SG_ 1142 ConsTipMsg2_D_Dsply 1;
BA_ "U_T6_MCA_MY2020_Rx" SG_ 1142 ConsTipMsg2_D_Dsply 1;
BA_ "U_P702_MY2021_Rx" SG_ 1142 ConsTipMsg2_D_Dsply 1;
BA_ "U_CD764_MY2022_Rx" SG_ 1142 ConsTipMsg1_D_Dsply 1;
BA_ "U_U55X_MY2022_Rx" SG_ 1142 ConsTipMsg1_D_Dsply 1;
BA_ "U_CD542_MY2021_Rx" SG_ 1142 ConsTipMsg1_D_Dsply 1;
BA_ "U_T6_MCA_MY2020_Rx" SG_ 1142 ConsTipMsg1_D_Dsply 1;
BA_ "U_P702_MY2021_Rx" SG_ 1142 ConsTipMsg1_D_Dsply 1;
BA_ "U_CD764_MY2022_Rx" SG_ 1142 ConsTipDecel_No_Dsply 1;
BA_ "U_U55X_MY2022_Rx" SG_ 1142 ConsTipDecel_No_Dsply 1;
BA_ "U_CD542_MY2021_Rx" SG_ 1142 ConsTipDecel_No_Dsply 1;
BA_ "U_T6_MCA_MY2020_Rx" SG_ 1142 ConsTipDecel_No_Dsply 1;
BA_ "U_P702_MY2021_Rx" SG_ 1142 ConsTipDecel_No_Dsply 1;
BA_ "U_CD764_MY2022_Rx" SG_ 1142 ConsTipA_No_Dsply 1;
BA_ "U_U55X_MY2022_Rx" SG_ 1142 ConsTipA_No_Dsply 1;
BA_ "U_CD542_MY2021_Rx" SG_ 1142 ConsTipA_No_Dsply 1;
BA_ "U_T6_MCA_MY2020_Rx" SG_ 1142 ConsTipA_No_Dsply 1;
BA_ "U_P702_MY2021_Rx" SG_ 1142 ConsTipA_No_Dsply 1;
BA_ "U_CD764_MY2022_Rx" SG_ 947 Outside_Air_Temp_Stat_UB 1;
BA_ "U_P702_MY2021_Rx" SG_ 947 Outside_Air_Temp_Stat_UB 1;
BA_ "U_U55X_MY2022_Rx" SG_ 947 Outside_Air_Temp_Stat_UB 1;
BA_ "U_CD542_MY2021_Rx" SG_ 947 Outside_Air_Temp_Stat_UB 1;
BA_ "U_T6_MCA_MY2020_Rx" SG_ 947 Outside_Air_Temp_Stat_UB 1;
BA_ "U_CD764_MY2022_Rx" SG_ 947 Outside_Air_Temp_Stat 1;
BA_ "U_P702_MY2021_Rx" SG_ 947 Outside_Air_Temp_Stat 1;
BA_ "U_U55X_MY2022_Rx" SG_ 947 Outside_Air_Temp_Stat 1;
BA_ "U_CD542_MY2021_Rx" SG_ 947 Outside_Air_Temp_Stat 1;
BA_ "U_T6_MCA_MY2020_Rx" SG_ 947 Outside_Air_Temp_Stat 1;
BA_ "GenSigSendType" SG_ 947 Outside_Air_Temp_Stat 3;
BA_ "GenSigStartValue" SG_ 947 Outside_Air_Temp_Stat 254;
BA_ "GenSigStartValueInteger" SG_ 947 Outside_Air_Temp_Stat 254;
BA_ "U_CD764_MY2022_Rx" SG_ 973 LaSysOffStat_D_Dsply 1;
BA_ "U_CD542_MY2021_Rx" SG_ 973 LaSysOffStat_D_Dsply 1;
BA_ "U_T6_MCA_MY2020_Rx" SG_ 973 LaSysOffStat_D_Dsply 1;
BA_ "U_CD764_MY2022_Rx" SG_ 973 TsrVl1RstrcMsgTxt2_D_Rq 1;
BA_ "U_U55X_MY2022_Rx" SG_ 973 TsrVl1RstrcMsgTxt2_D_Rq 1;
BA_ "U_CD542_MY2021_Rx" SG_ 973 TsrVl1RstrcMsgTxt2_D_Rq 1;
BA_ "U_T6_MCA_MY2020_Rx" SG_ 973 TsrVl1RstrcMsgTxt2_D_Rq 1;
BA_ "U_P702_MY2021_Rx" SG_ 973 TsrVl1RstrcMsgTxt2_D_Rq 1;
BA_ "GenSigStartValue" SG_ 973 TsrVl1RstrcMsgTxt2_D_Rq 1;
BA_ "GenSigStartValueInteger" SG_ 973 TsrVl1RstrcMsgTxt2_D_Rq 1;
BA_ "U_CD764_MY2022_Rx" SG_ 973 TsrVl2RstrcMsgTxt2_D_Rq 1;
BA_ "U_U55X_MY2022_Rx" SG_ 973 TsrVl2RstrcMsgTxt2_D_Rq 1;
BA_ "U_CD542_MY2021_Rx" SG_ 973 TsrVl2RstrcMsgTxt2_D_Rq 1;
BA_ "U_T6_MCA_MY2020_Rx" SG_ 973 TsrVl2RstrcMsgTxt2_D_Rq 1;
BA_ "U_P702_MY2021_Rx" SG_ 973 TsrVl2RstrcMsgTxt2_D_Rq 1;
BA_ "GenSigStartValue" SG_ 973 TsrVl2RstrcMsgTxt2_D_Rq 1;
BA_ "GenSigStartValueInteger" SG_ 973 TsrVl2RstrcMsgTxt2_D_Rq 1;
BA_ "U_CD764_MY2022_Rx" SG_ 973 TsrVl2PrmntMsgTxt_D_Rq 1;
BA_ "U_U55X_MY2022_Rx" SG_ 973 TsrVl2PrmntMsgTxt_D_Rq 1;
BA_ "U_CD542_MY2021_Rx" SG_ 973 TsrVl2PrmntMsgTxt_D_Rq 1;
BA_ "U_T6_MCA_MY2020_Rx" SG_ 973 TsrVl2PrmntMsgTxt_D_Rq 1;
BA_ "U_P702_MY2021_Rx" SG_ 973 TsrVl2PrmntMsgTxt_D_Rq 1;
BA_ "U_CD764_MY2022_Rx" SG_ 973 TsrVl1PrmntMsgTxt_D_Rq 1;
BA_ "U_U55X_MY2022_Rx" SG_ 973 TsrVl1PrmntMsgTxt_D_Rq 1;
BA_ "U_CD542_MY2021_Rx" SG_ 973 TsrVl1PrmntMsgTxt_D_Rq 1;
BA_ "U_T6_MCA_MY2020_Rx" SG_ 973 TsrVl1PrmntMsgTxt_D_Rq 1;
BA_ "U_P702_MY2021_Rx" SG_ 973 TsrVl1PrmntMsgTxt_D_Rq 1;
BA_ "U_CD764_MY2022_Rx" SG_ 973 TsrOvtkMsgTxt2_D_Rq 1;
BA_ "U_U55X_MY2022_Rx" SG_ 973 TsrOvtkMsgTxt2_D_Rq 1;
BA_ "U_CD542_MY2021_Rx" SG_ 973 TsrOvtkMsgTxt2_D_Rq 1;
BA_ "U_T6_MCA_MY2020_Rx" SG_ 973 TsrOvtkMsgTxt2_D_Rq 1;
BA_ "U_P702_MY2021_Rx" SG_ 973 TsrOvtkMsgTxt2_D_Rq 1;
BA_ "U_U55X_MY2022_Rx" SG_ 973 WwaWarn_B_Rq 1;
BA_ "U_CD764_MY2022_Rx" SG_ 973 WwaWarn_B_Rq 1;
BA_ "U_CD542_MY2021_Rx" SG_ 973 WwaWarn_B_Rq 1;
BA_ "U_T6_MCA_MY2020_Rx" SG_ 973 WwaWarn_B_Rq 1;
BA_ "U_CD764_MY2022_Rx" SG_ 973 TsrVlUnitMsgTxt_D_Rq 1;
BA_ "U_U55X_MY2022_Rx" SG_ 973 TsrVlUnitMsgTxt_D_Rq 1;
BA_ "U_CD542_MY2021_Rx" SG_ 973 TsrVlUnitMsgTxt_D_Rq 1;
BA_ "U_T6_MCA_MY2020_Rx" SG_ 973 TsrVlUnitMsgTxt_D_Rq 1;
BA_ "U_P702_MY2021_Rx" SG_ 973 TsrVlUnitMsgTxt_D_Rq 1;
BA_ "GenSigStartValue" SG_ 973 TsrVlUnitMsgTxt_D_Rq 2;
BA_ "GenSigStartValueInteger" SG_ 973 TsrVlUnitMsgTxt_D_Rq 2;
BA_ "U_CD764_MY2022_Rx" SG_ 973 TsrVLim2MsgTxt_D_Rq 1;
BA_ "U_U55X_MY2022_Rx" SG_ 973 TsrVLim2MsgTxt_D_Rq 1;
BA_ "U_CD542_MY2021_Rx" SG_ 973 TsrVLim2MsgTxt_D_Rq 1;
BA_ "U_T6_MCA_MY2020_Rx" SG_ 973 TsrVLim2MsgTxt_D_Rq 1;
BA_ "U_P702_MY2021_Rx" SG_ 973 TsrVLim2MsgTxt_D_Rq 1;
BA_ "GenSigStartValue" SG_ 973 TsrVLim2MsgTxt_D_Rq 255;
BA_ "GenSigStartValueInteger" SG_ 973 TsrVLim2MsgTxt_D_Rq 255;
BA_ "U_CD764_MY2022_Rx" SG_ 973 TsrVLim1MsgTxt_D_Rq 1;
BA_ "U_U55X_MY2022_Rx" SG_ 973 TsrVLim1MsgTxt_D_Rq 1;
BA_ "U_CD542_MY2021_Rx" SG_ 973 TsrVLim1MsgTxt_D_Rq 1;
BA_ "U_T6_MCA_MY2020_Rx" SG_ 973 TsrVLim1MsgTxt_D_Rq 1;
BA_ "U_P702_MY2021_Rx" SG_ 973 TsrVLim1MsgTxt_D_Rq 1;
BA_ "GenSigStartValue" SG_ 973 TsrVLim1MsgTxt_D_Rq 255;
BA_ "GenSigStartValueInteger" SG_ 973 TsrVLim1MsgTxt_D_Rq 255;
BA_ "U_CD764_MY2022_Rx" SG_ 973 TsrVl2StatMsgTxt_D_Rq 1;
BA_ "U_U55X_MY2022_Rx" SG_ 973 TsrVl2StatMsgTxt_D_Rq 1;
BA_ "U_CD542_MY2021_Rx" SG_ 973 TsrVl2StatMsgTxt_D_Rq 1;
BA_ "U_T6_MCA_MY2020_Rx" SG_ 973 TsrVl2StatMsgTxt_D_Rq 1;
BA_ "U_P702_MY2021_Rx" SG_ 973 TsrVl2StatMsgTxt_D_Rq 1;
BA_ "U_U55X_MY2022_Rx" SG_ 973 TsrVl2RstrcMsgTxt_D_Rq 1;
BA_ "U_CD764_MY2022_Rx" SG_ 973 TsrVl2RstrcMsgTxt_D_Rq 1;
BA_ "U_CD542_MY2021_Rx" SG_ 973 TsrVl2RstrcMsgTxt_D_Rq 1;
BA_ "U_T6_MCA_MY2020_Rx" SG_ 973 TsrVl2RstrcMsgTxt_D_Rq 1;
BA_ "U_CD764_MY2022_Rx" SG_ 973 TsrVl1StatMsgTxt_D_Rq 1;
BA_ "U_U55X_MY2022_Rx" SG_ 973 TsrVl1StatMsgTxt_D_Rq 1;
BA_ "U_CD542_MY2021_Rx" SG_ 973 TsrVl1StatMsgTxt_D_Rq 1;
BA_ "U_T6_MCA_MY2020_Rx" SG_ 973 TsrVl1StatMsgTxt_D_Rq 1;
BA_ "U_P702_MY2021_Rx" SG_ 973 TsrVl1StatMsgTxt_D_Rq 1;
BA_ "U_CD764_MY2022_Rx" SG_ 973 TsrVl1RstrcMsgTxt_D_Rq 1;
BA_ "U_CD542_MY2021_Rx" SG_ 973 TsrVl1RstrcMsgTxt_D_Rq 1;
BA_ "U_T6_MCA_MY2020_Rx" SG_ 973 TsrVl1RstrcMsgTxt_D_Rq 1;
BA_ "U_CD764_MY2022_Rx" SG_ 973 TsrStatMsgTxt_D_Rq 1;
BA_ "U_CD542_MY2021_Rx" SG_ 973 TsrStatMsgTxt_D_Rq 1;
BA_ "U_T6_MCA_MY2020_Rx" SG_ 973 TsrStatMsgTxt_D_Rq 1;
BA_ "U_CD764_MY2022_Rx" SG_ 973 TsrOvtkStatMsgTxt_D_Rq 1;
BA_ "U_U55X_MY2022_Rx" SG_ 973 TsrOvtkStatMsgTxt_D_Rq 1;
BA_ "U_CD542_MY2021_Rx" SG_ 973 TsrOvtkStatMsgTxt_D_Rq 1;
BA_ "U_T6_MCA_MY2020_Rx" SG_ 973 TsrOvtkStatMsgTxt_D_Rq 1;
BA_ "U_P702_MY2021_Rx" SG_ 973 TsrOvtkStatMsgTxt_D_Rq 1;
BA_ "U_CD764_MY2022_Rx" SG_ 973 TsrOvtkMsgTxt_D_Rq 1;
BA_ "U_U55X_MY2022_Rx" SG_ 973 TsrOvtkMsgTxt_D_Rq 1;
BA_ "U_CD542_MY2021_Rx" SG_ 973 TsrOvtkMsgTxt_D_Rq 1;
BA_ "U_T6_MCA_MY2020_Rx" SG_ 973 TsrOvtkMsgTxt_D_Rq 1;
BA_ "U_P702_MY2021_Rx" SG_ 973 TsrOvtkMsgTxt_D_Rq 1;
BA_ "GenSigStartValue" SG_ 973 TsrOvtkMsgTxt_D_Rq 1;
BA_ "GenSigStartValueInteger" SG_ 973 TsrOvtkMsgTxt_D_Rq 1;
BA_ "U_CD764_MY2022_Rx" SG_ 973 TsrOswWarnMsgTxt_D_Rq 1;
BA_ "U_U55X_MY2022_Rx" SG_ 973 TsrOswWarnMsgTxt_D_Rq 1;
BA_ "U_CD542_MY2021_Rx" SG_ 973 TsrOswWarnMsgTxt_D_Rq 1;
BA_ "U_T6_MCA_MY2020_Rx" SG_ 973 TsrOswWarnMsgTxt_D_Rq 1;
BA_ "GenSigStartValue" SG_ 973 TsrOswWarnMsgTxt_D_Rq 1;
BA_ "GenSigStartValueInteger" SG_ 973 TsrOswWarnMsgTxt_D_Rq 1;
BA_ "U_CD764_MY2022_Rx" SG_ 973 TsrMsgTxt_D_Rq 1;
BA_ "U_U55X_MY2022_Rx" SG_ 973 TsrMsgTxt_D_Rq 1;
BA_ "U_CD542_MY2021_Rx" SG_ 973 TsrMsgTxt_D_Rq 1;
BA_ "U_T6_MCA_MY2020_Rx" SG_ 973 TsrMsgTxt_D_Rq 1;
BA_ "U_P702_MY2021_Rx" SG_ 973 TsrMsgTxt_D_Rq 1;
BA_ "GenSigStartValue" SG_ 973 TsrMsgTxt_D_Rq 1;
BA_ "GenSigStartValueInteger" SG_ 973 TsrMsgTxt_D_Rq 1;
BA_ "U_CD764_MY2022_Tx" SG_ 405 LBC1_StartItemInd 1;
BA_ "U_U55X_MY2022_Tx" SG_ 405 LBC1_StartItemInd 1;
BA_ "U_CD542_MY2021_Tx" SG_ 405 LBC1_StartItemInd 1;
BA_ "U_T6_MCA_MY2020_Tx" SG_ 405 LBC1_StartItemInd 1;
BA_ "U_CD764_MY2022_Rx" SG_ 405 LBC1_StartItemInd 1;
BA_ "U_U55X_MY2022_Rx" SG_ 405 LBC1_StartItemInd 1;
BA_ "U_CD542_MY2021_Rx" SG_ 405 LBC1_StartItemInd 1;
BA_ "U_T6_MCA_MY2020_Rx" SG_ 405 LBC1_StartItemInd 1;
BA_ "U_P702_MY2021_Rx" SG_ 405 LBC1_StartItemInd 1;
BA_ "GenSigSendType" SG_ 405 LBC1_StartItemInd 3;
BA_ "U_CD764_MY2022_Tx" SG_ 405 LBC1_SetListServ 1;
BA_ "U_U55X_MY2022_Tx" SG_ 405 LBC1_SetListServ 1;
BA_ "U_CD542_MY2021_Tx" SG_ 405 LBC1_SetListServ 1;
BA_ "U_T6_MCA_MY2020_Tx" SG_ 405 LBC1_SetListServ 1;
BA_ "U_CD764_MY2022_Rx" SG_ 405 LBC1_SetListServ 1;
BA_ "U_U55X_MY2022_Rx" SG_ 405 LBC1_SetListServ 1;
BA_ "U_CD542_MY2021_Rx" SG_ 405 LBC1_SetListServ 1;
BA_ "U_T6_MCA_MY2020_Rx" SG_ 405 LBC1_SetListServ 1;
BA_ "U_P702_MY2021_Rx" SG_ 405 LBC1_SetListServ 1;
BA_ "GenSigSendType" SG_ 405 LBC1_SetListServ 3;
BA_ "U_CD764_MY2022_Tx" SG_ 405 LBC1_Opcode 1;
BA_ "U_U55X_MY2022_Tx" SG_ 405 LBC1_Opcode 1;
BA_ "U_CD542_MY2021_Tx" SG_ 405 LBC1_Opcode 1;
BA_ "U_T6_MCA_MY2020_Tx" SG_ 405 LBC1_Opcode 1;
BA_ "U_CD764_MY2022_Rx" SG_ 405 LBC1_Opcode 1;
BA_ "U_U55X_MY2022_Rx" SG_ 405 LBC1_Opcode 1;
BA_ "U_CD542_MY2021_Rx" SG_ 405 LBC1_Opcode 1;
BA_ "U_T6_MCA_MY2020_Rx" SG_ 405 LBC1_Opcode 1;
BA_ "U_P702_MY2021_Rx" SG_ 405 LBC1_Opcode 1;
BA_ "GenSigSendType" SG_ 405 LBC1_Opcode 3;
BA_ "U_CD764_MY2022_Tx" SG_ 405 LBC1_NbrOfItems 1;
BA_ "U_U55X_MY2022_Tx" SG_ 405 LBC1_NbrOfItems 1;
BA_ "U_CD542_MY2021_Tx" SG_ 405 LBC1_NbrOfItems 1;
BA_ "U_T6_MCA_MY2020_Tx" SG_ 405 LBC1_NbrOfItems 1;
BA_ "U_CD764_MY2022_Rx" SG_ 405 LBC1_NbrOfItems 1;
BA_ "U_U55X_MY2022_Rx" SG_ 405 LBC1_NbrOfItems 1;
BA_ "U_CD542_MY2021_Rx" SG_ 405 LBC1_NbrOfItems 1;
BA_ "U_T6_MCA_MY2020_Rx" SG_ 405 LBC1_NbrOfItems 1;
BA_ "U_P702_MY2021_Rx" SG_ 405 LBC1_NbrOfItems 1;
BA_ "GenSigSendType" SG_ 405 LBC1_NbrOfItems 3;
BA_ "U_CD764_MY2022_Tx" SG_ 405 LBC1_ItemIndex 1;
BA_ "U_U55X_MY2022_Tx" SG_ 405 LBC1_ItemIndex 1;
BA_ "U_CD542_MY2021_Tx" SG_ 405 LBC1_ItemIndex 1;
BA_ "U_T6_MCA_MY2020_Tx" SG_ 405 LBC1_ItemIndex 1;
BA_ "U_CD764_MY2022_Rx" SG_ 405 LBC1_ItemIndex 1;
BA_ "U_U55X_MY2022_Rx" SG_ 405 LBC1_ItemIndex 1;
BA_ "U_CD542_MY2021_Rx" SG_ 405 LBC1_ItemIndex 1;
BA_ "U_T6_MCA_MY2020_Rx" SG_ 405 LBC1_ItemIndex 1;
BA_ "U_P702_MY2021_Rx" SG_ 405 LBC1_ItemIndex 1;
BA_ "GenSigSendType" SG_ 405 LBC1_ItemIndex 3;
BA_ "U_CD764_MY2022_Tx" SG_ 405 LBC1_ActiveListID 1;
BA_ "U_U55X_MY2022_Tx" SG_ 405 LBC1_ActiveListID 1;
BA_ "U_CD542_MY2021_Tx" SG_ 405 LBC1_ActiveListID 1;
BA_ "U_T6_MCA_MY2020_Tx" SG_ 405 LBC1_ActiveListID 1;
BA_ "U_CD764_MY2022_Rx" SG_ 405 LBC1_ActiveListID 1;
BA_ "U_U55X_MY2022_Rx" SG_ 405 LBC1_ActiveListID 1;
BA_ "U_CD542_MY2021_Rx" SG_ 405 LBC1_ActiveListID 1;
BA_ "U_T6_MCA_MY2020_Rx" SG_ 405 LBC1_ActiveListID 1;
BA_ "U_P702_MY2021_Rx" SG_ 405 LBC1_ActiveListID 1;
BA_ "GenSigSendType" SG_ 405 LBC1_ActiveListID 3;
BA_ "U_CD764_MY2022_Tx" SG_ 756 AdjustableChimeVol2_Rq 1;
BA_ "U_U55X_MY2022_Tx" SG_ 756 AdjustableChimeVol2_Rq 1;
BA_ "U_CD542_MY2021_Tx" SG_ 756 AdjustableChimeVol2_Rq 1;
BA_ "U_T6_MCA_MY2020_Tx" SG_ 756 AdjustableChimeVol2_Rq 1;
BA_ "U_CD764_MY2022_Rx" SG_ 756 AdjustableChimeVol2_Rq 1;
BA_ "U_U55X_MY2022_Rx" SG_ 756 AdjustableChimeVol2_Rq 1;
BA_ "U_T6_MCA_MY2020_Rx" SG_ 756 AdjustableChimeVol2_Rq 1;
BA_ "GenSigSendType" SG_ 756 AdjustableChimeVol2_Rq 3;
BA_ "U_CD764_MY2022_Tx" SG_ 756 Off_Time_Btwn_Chime2 1;
BA_ "U_U55X_MY2022_Tx" SG_ 756 Off_Time_Btwn_Chime2 1;
BA_ "U_CD542_MY2021_Tx" SG_ 756 Off_Time_Btwn_Chime2 1;
BA_ "U_T6_MCA_MY2020_Tx" SG_ 756 Off_Time_Btwn_Chime2 1;
BA_ "U_P702_MY2021_Tx" SG_ 756 Off_Time_Btwn_Chime2 1;
BA_ "U_CD764_MY2022_Rx" SG_ 756 Off_Time_Btwn_Chime2 1;
BA_ "U_U55X_MY2022_Rx" SG_ 756 Off_Time_Btwn_Chime2 1;
BA_ "U_CD542_MY2021_Rx" SG_ 756 Off_Time_Btwn_Chime2 1;
BA_ "U_T6_MCA_MY2020_Rx" SG_ 756 Off_Time_Btwn_Chime2 1;
BA_ "U_P702_MY2021_Rx" SG_ 756 Off_Time_Btwn_Chime2 1;
BA_ "U_CD764_MY2022_Tx" SG_ 756 Chime_Vol_Level2 1;
BA_ "U_U55X_MY2022_Tx" SG_ 756 Chime_Vol_Level2 1;
BA_ "U_CD542_MY2021_Tx" SG_ 756 Chime_Vol_Level2 1;
BA_ "U_T6_MCA_MY2020_Tx" SG_ 756 Chime_Vol_Level2 1;
BA_ "U_P702_MY2021_Tx" SG_ 756 Chime_Vol_Level2 1;
BA_ "U_CD764_MY2022_Rx" SG_ 756 Chime_Vol_Level2 1;
BA_ "U_U55X_MY2022_Rx" SG_ 756 Chime_Vol_Level2 1;
BA_ "U_CD542_MY2021_Rx" SG_ 756 Chime_Vol_Level2 1;
BA_ "U_T6_MCA_MY2020_Rx" SG_ 756 Chime_Vol_Level2 1;
BA_ "U_P702_MY2021_Rx" SG_ 756 Chime_Vol_Level2 1;
BA_ "U_CD764_MY2022_Tx" SG_ 756 Chime_Time_Criticality2 1;
BA_ "U_U55X_MY2022_Tx" SG_ 756 Chime_Time_Criticality2 1;
BA_ "U_CD542_MY2021_Tx" SG_ 756 Chime_Time_Criticality2 1;
BA_ "U_T6_MCA_MY2020_Tx" SG_ 756 Chime_Time_Criticality2 1;
BA_ "U_P702_MY2021_Tx" SG_ 756 Chime_Time_Criticality2 1;
BA_ "U_CD764_MY2022_Rx" SG_ 756 Chime_Time_Criticality2 1;
BA_ "U_U55X_MY2022_Rx" SG_ 756 Chime_Time_Criticality2 1;
BA_ "U_CD542_MY2021_Rx" SG_ 756 Chime_Time_Criticality2 1;
BA_ "U_T6_MCA_MY2020_Rx" SG_ 756 Chime_Time_Criticality2 1;
BA_ "U_P702_MY2021_Rx" SG_ 756 Chime_Time_Criticality2 1;
BA_ "GenSigSendType" SG_ 756 Chime_Time_Criticality2 3;
BA_ "U_CD764_MY2022_Tx" SG_ 756 Chime_Occurence2 1;
BA_ "U_U55X_MY2022_Tx" SG_ 756 Chime_Occurence2 1;
BA_ "U_CD542_MY2021_Tx" SG_ 756 Chime_Occurence2 1;
BA_ "U_T6_MCA_MY2020_Tx" SG_ 756 Chime_Occurence2 1;
BA_ "U_P702_MY2021_Tx" SG_ 756 Chime_Occurence2 1;
BA_ "U_CD764_MY2022_Rx" SG_ 756 Chime_Occurence2 1;
BA_ "U_U55X_MY2022_Rx" SG_ 756 Chime_Occurence2 1;
BA_ "U_CD542_MY2021_Rx" SG_ 756 Chime_Occurence2 1;
BA_ "U_T6_MCA_MY2020_Rx" SG_ 756 Chime_Occurence2 1;
BA_ "U_P702_MY2021_Rx" SG_ 756 Chime_Occurence2 1;
BA_ "GenSigSendType" SG_ 756 Chime_Occurence2 3;
BA_ "U_CD764_MY2022_Tx" SG_ 756 Chime_Directionality2 1;
BA_ "U_U55X_MY2022_Tx" SG_ 756 Chime_Directionality2 1;
BA_ "U_CD542_MY2021_Tx" SG_ 756 Chime_Directionality2 1;
BA_ "U_T6_MCA_MY2020_Tx" SG_ 756 Chime_Directionality2 1;
BA_ "U_P702_MY2021_Tx" SG_ 756 Chime_Directionality2 1;
BA_ "U_CD764_MY2022_Rx" SG_ 756 Chime_Directionality2 1;
BA_ "U_U55X_MY2022_Rx" SG_ 756 Chime_Directionality2 1;
BA_ "U_CD542_MY2021_Rx" SG_ 756 Chime_Directionality2 1;
BA_ "U_T6_MCA_MY2020_Rx" SG_ 756 Chime_Directionality2 1;
BA_ "U_P702_MY2021_Rx" SG_ 756 Chime_Directionality2 1;
BA_ "GenSigSendType" SG_ 756 Chime_Directionality2 3;
BA_ "U_CD764_MY2022_Tx" SG_ 756 Chime2 1;
BA_ "U_U55X_MY2022_Tx" SG_ 756 Chime2 1;
BA_ "U_CD542_MY2021_Tx" SG_ 756 Chime2 1;
BA_ "U_T6_MCA_MY2020_Tx" SG_ 756 Chime2 1;
BA_ "U_P702_MY2021_Tx" SG_ 756 Chime2 1;
BA_ "U_CD764_MY2022_Rx" SG_ 756 Chime2 1;
BA_ "U_U55X_MY2022_Rx" SG_ 756 Chime2 1;
BA_ "U_CD542_MY2021_Rx" SG_ 756 Chime2 1;
BA_ "U_T6_MCA_MY2020_Rx" SG_ 756 Chime2 1;
BA_ "U_P702_MY2021_Rx" SG_ 756 Chime2 1;
BA_ "U_CD764_MY2022_Tx" SG_ 756 Chime2Id_No_Rq 1;
BA_ "U_U55X_MY2022_Tx" SG_ 756 Chime2Id_No_Rq 1;
BA_ "U_CD542_MY2021_Tx" SG_ 756 Chime2Id_No_Rq 1;
BA_ "U_T6_MCA_MY2020_Tx" SG_ 756 Chime2Id_No_Rq 1;
BA_ "U_P702_MY2021_Tx" SG_ 756 Chime2Id_No_Rq 1;
BA_ "U_CD542_MY2021_Rx" SG_ 756 Chime2Id_No_Rq 1;
BA_ "U_U55X_MY2022_Rx" SG_ 756 Chime2Id_No_Rq 1;
BA_ "U_P702_MY2021_Rx" SG_ 756 Chime2Id_No_Rq 1;
BA_ "U_CD764_MY2022_Rx" SG_ 756 Chime2Id_No_Rq 1;
BA_ "U_T6_MCA_MY2020_Rx" SG_ 756 Chime2Id_No_Rq 1;
BA_ "GenSigSendType" SG_ 756 Chime2Id_No_Rq 3;
BA_ "U_CD764_MY2022_Tx" SG_ 544 ChimeId_No_Rq 1;
BA_ "U_U55X_MY2022_Tx" SG_ 544 ChimeId_No_Rq 1;
BA_ "U_CD542_MY2021_Tx" SG_ 544 ChimeId_No_Rq 1;
BA_ "U_T6_MCA_MY2020_Tx" SG_ 544 ChimeId_No_Rq 1;
BA_ "U_U55X_MY2022_Rx" SG_ 544 ChimeId_No_Rq 1;
BA_ "U_T6_MCA_MY2020_Rx" SG_ 544 ChimeId_No_Rq 1;
BA_ "GenSigSendType" SG_ 544 ChimeId_No_Rq 3;
BA_ "U_CD764_MY2022_Tx" SG_ 544 AdjustableChimeVol_Rq 1;
BA_ "U_U55X_MY2022_Tx" SG_ 544 AdjustableChimeVol_Rq 1;
BA_ "U_CD542_MY2021_Tx" SG_ 544 AdjustableChimeVol_Rq 1;
BA_ "U_T6_MCA_MY2020_Tx" SG_ 544 AdjustableChimeVol_Rq 1;
BA_ "U_U55X_MY2022_Rx" SG_ 544 AdjustableChimeVol_Rq 1;
BA_ "U_CD764_MY2022_Rx" SG_ 544 AdjustableChimeVol_Rq 1;
BA_ "U_T6_MCA_MY2020_Rx" SG_ 544 AdjustableChimeVol_Rq 1;
BA_ "GenSigSendType" SG_ 544 AdjustableChimeVol_Rq 3;
BA_ "U_CD764_MY2022_Tx" SG_ 544 Chime_Occurence 1;
BA_ "U_U55X_MY2022_Tx" SG_ 544 Chime_Occurence 1;
BA_ "U_CD542_MY2021_Tx" SG_ 544 Chime_Occurence 1;
BA_ "U_T6_MCA_MY2020_Tx" SG_ 544 Chime_Occurence 1;
BA_ "U_P702_MY2021_Tx" SG_ 544 Chime_Occurence 1;
BA_ "U_CD764_MY2022_Rx" SG_ 544 Chime_Occurence 1;
BA_ "U_U55X_MY2022_Rx" SG_ 544 Chime_Occurence 1;
BA_ "U_CD542_MY2021_Rx" SG_ 544 Chime_Occurence 1;
BA_ "U_T6_MCA_MY2020_Rx" SG_ 544 Chime_Occurence 1;
BA_ "U_P702_MY2021_Rx" SG_ 544 Chime_Occurence 1;
BA_ "GenSigSendType" SG_ 544 Chime_Occurence 3;
BA_ "U_CD764_MY2022_Tx" SG_ 544 Off_Time_Btwn_Chime 1;
BA_ "U_U55X_MY2022_Tx" SG_ 544 Off_Time_Btwn_Chime 1;
BA_ "U_CD542_MY2021_Tx" SG_ 544 Off_Time_Btwn_Chime 1;
BA_ "U_T6_MCA_MY2020_Tx" SG_ 544 Off_Time_Btwn_Chime 1;
BA_ "U_P702_MY2021_Tx" SG_ 544 Off_Time_Btwn_Chime 1;
BA_ "U_CD764_MY2022_Rx" SG_ 544 Off_Time_Btwn_Chime 1;
BA_ "U_U55X_MY2022_Rx" SG_ 544 Off_Time_Btwn_Chime 1;
BA_ "U_CD542_MY2021_Rx" SG_ 544 Off_Time_Btwn_Chime 1;
BA_ "U_T6_MCA_MY2020_Rx" SG_ 544 Off_Time_Btwn_Chime 1;
BA_ "U_P702_MY2021_Rx" SG_ 544 Off_Time_Btwn_Chime 1;
BA_ "U_CD764_MY2022_Tx" SG_ 544 Chime_Time_Criticality 1;
BA_ "U_U55X_MY2022_Tx" SG_ 544 Chime_Time_Criticality 1;
BA_ "U_CD542_MY2021_Tx" SG_ 544 Chime_Time_Criticality 1;
BA_ "U_T6_MCA_MY2020_Tx" SG_ 544 Chime_Time_Criticality 1;
BA_ "U_P702_MY2021_Tx" SG_ 544 Chime_Time_Criticality 1;
BA_ "U_CD764_MY2022_Rx" SG_ 544 Chime_Time_Criticality 1;
BA_ "U_U55X_MY2022_Rx" SG_ 544 Chime_Time_Criticality 1;
BA_ "U_CD542_MY2021_Rx" SG_ 544 Chime_Time_Criticality 1;
BA_ "U_T6_MCA_MY2020_Rx" SG_ 544 Chime_Time_Criticality 1;
BA_ "U_P702_MY2021_Rx" SG_ 544 Chime_Time_Criticality 1;
BA_ "GenSigSendType" SG_ 544 Chime_Time_Criticality 3;
BA_ "U_CD764_MY2022_Tx" SG_ 544 Chime_Directionality 1;
BA_ "U_U55X_MY2022_Tx" SG_ 544 Chime_Directionality 1;
BA_ "U_CD542_MY2021_Tx" SG_ 544 Chime_Directionality 1;
BA_ "U_T6_MCA_MY2020_Tx" SG_ 544 Chime_Directionality 1;
BA_ "U_P702_MY2021_Tx" SG_ 544 Chime_Directionality 1;
BA_ "U_CD764_MY2022_Rx" SG_ 544 Chime_Directionality 1;
BA_ "U_U55X_MY2022_Rx" SG_ 544 Chime_Directionality 1;
BA_ "U_CD542_MY2021_Rx" SG_ 544 Chime_Directionality 1;
BA_ "U_T6_MCA_MY2020_Rx" SG_ 544 Chime_Directionality 1;
BA_ "U_P702_MY2021_Rx" SG_ 544 Chime_Directionality 1;
BA_ "GenSigSendType" SG_ 544 Chime_Directionality 3;
BA_ "U_CD764_MY2022_Tx" SG_ 544 Chime_Vol_Level 1;
BA_ "U_U55X_MY2022_Tx" SG_ 544 Chime_Vol_Level 1;
BA_ "U_CD542_MY2021_Tx" SG_ 544 Chime_Vol_Level 1;
BA_ "U_T6_MCA_MY2020_Tx" SG_ 544 Chime_Vol_Level 1;
BA_ "U_P702_MY2021_Tx" SG_ 544 Chime_Vol_Level 1;
BA_ "U_CD764_MY2022_Rx" SG_ 544 Chime_Vol_Level 1;
BA_ "U_U55X_MY2022_Rx" SG_ 544 Chime_Vol_Level 1;
BA_ "U_CD542_MY2021_Rx" SG_ 544 Chime_Vol_Level 1;
BA_ "U_T6_MCA_MY2020_Rx" SG_ 544 Chime_Vol_Level 1;
BA_ "U_P702_MY2021_Rx" SG_ 544 Chime_Vol_Level 1;
BA_ "U_CD764_MY2022_Tx" SG_ 544 Chime 1;
BA_ "U_U55X_MY2022_Tx" SG_ 544 Chime 1;
BA_ "U_CD542_MY2021_Tx" SG_ 544 Chime 1;
BA_ "U_T6_MCA_MY2020_Tx" SG_ 544 Chime 1;
BA_ "U_P702_MY2021_Tx" SG_ 544 Chime 1;
BA_ "U_CD764_MY2022_Rx" SG_ 544 Chime 1;
BA_ "U_U55X_MY2022_Rx" SG_ 544 Chime 1;
BA_ "U_CD542_MY2021_Rx" SG_ 544 Chime 1;
BA_ "U_T6_MCA_MY2020_Rx" SG_ 544 Chime 1;
BA_ "U_P702_MY2021_Rx" SG_ 544 Chime 1;
BA_ "WakeupSignal" SG_ 544 Chime 1;
BA_ "U_U55X_MY2022_Tx" SG_ 291 LangUpdate_Rsp 1;
BA_ "U_CD542_MY2021_Tx" SG_ 291 LangUpdate_Rsp 1;
BA_ "U_T6_MCA_MY2020_Tx" SG_ 291 LangUpdate_Rsp 1;
BA_ "U_P702_MY2021_Tx" SG_ 291 LangUpdate_Rsp 1;
BA_ "U_CD764_MY2022_Rx" SG_ 291 LangUpdate_Rsp 1;
BA_ "U_U55X_MY2022_Rx" SG_ 291 LangUpdate_Rsp 1;
BA_ "U_CD542_MY2021_Rx" SG_ 291 LangUpdate_Rsp 1;
BA_ "U_T6_MCA_MY2020_Rx" SG_ 291 LangUpdate_Rsp 1;
BA_ "GenSigSendType" SG_ 291 LangUpdate_Rsp 3;
BA_ "U_U55X_MY2022_Rx" SG_ 400 Mc_SetCurrStatMCCh_Rq 1;
BA_ "U_T6_MCA_MY2020_Rx" SG_ 400 Mc_SetCurrStatMCCh_Rq 1;
BA_ "U_U55X_MY2022_Rx" SG_ 400 Mc_SetCurrntStatFreq_Rq 1;
BA_ "U_T6_MCA_MY2020_Rx" SG_ 400 Mc_SetCurrntStatFreq_Rq 1;
BA_ "U_U55X_MY2022_Rx" SG_ 400 Mc_SetCurrentStatOp_Rq 1;
BA_ "U_T6_MCA_MY2020_Rx" SG_ 400 Mc_SetCurrentStatOp_Rq 1;
BA_ "GenSigSendType" SG_ 400 Mc_SetCurrentStatOp_Rq 3;
BA_ "U_T6_MCA_MY2020_Tx" SG_ 400 Mc_PerTUStartIndex2_Rq 1;
BA_ "U_U55X_MY2022_Rx" SG_ 400 Mc_PerTUStartIndex2_Rq 1;
BA_ "U_CD542_MY2021_Rx" SG_ 400 Mc_PerTUStartIndex2_Rq 1;
BA_ "U_T6_MCA_MY2020_Rx" SG_ 400 Mc_PerTUStartIndex2_Rq 1;
BA_ "U_T6_MCA_MY2020_Tx" SG_ 400 Mc_PerTUPresetArea_Rq 1;
BA_ "U_U55X_MY2022_Rx" SG_ 400 Mc_PerTUPresetArea_Rq 1;
BA_ "U_CD542_MY2021_Rx" SG_ 400 Mc_PerTUPresetArea_Rq 1;
BA_ "U_T6_MCA_MY2020_Rx" SG_ 400 Mc_PerTUPresetArea_Rq 1;
BA_ "GenSigSendType" SG_ 400 Mc_PerTUPresetArea_Rq 3;
BA_ "U_T6_MCA_MY2020_Tx" SG_ 400 Mc_PerTUNbrOfPresets_Rq 1;
BA_ "U_U55X_MY2022_Rx" SG_ 400 Mc_PerTUNbrOfPresets_Rq 1;
BA_ "U_CD542_MY2021_Rx" SG_ 400 Mc_PerTUNbrOfPresets_Rq 1;
BA_ "U_T6_MCA_MY2020_Rx" SG_ 400 Mc_PerTUNbrOfPresets_Rq 1;
BA_ "U_CD764_MY2022_Tx" SG_ 647 HEC_BTIncomingCall_Rq 1;
BA_ "U_T6_MCA_MY2020_Tx" SG_ 647 HEC_BTIncomingCall_Rq 1;
BA_ "U_CD764_MY2022_Rx" SG_ 647 HEC_BTIncomingCall_Rq 1;
BA_ "U_U55X_MY2022_Rx" SG_ 647 HEC_BTIncomingCall_Rq 1;
BA_ "U_T6_MCA_MY2020_Rx" SG_ 647 HEC_BTIncomingCall_Rq 1;
BA_ "GenSigSendType" SG_ 647 HEC_BTIncomingCall_Rq 3;
BA_ "U_CD764_MY2022_Tx" SG_ 647 HEC_BTEndTelService_Rq 1;
BA_ "U_T6_MCA_MY2020_Tx" SG_ 647 HEC_BTEndTelService_Rq 1;
BA_ "U_CD764_MY2022_Rx" SG_ 647 HEC_BTEndTelService_Rq 1;
BA_ "U_U55X_MY2022_Rx" SG_ 647 HEC_BTEndTelService_Rq 1;
BA_ "U_T6_MCA_MY2020_Rx" SG_ 647 HEC_BTEndTelService_Rq 1;
BA_ "GenSigSendType" SG_ 647 HEC_BTEndTelService_Rq 3;
BA_ "GenSigStartValueInteger" SG_ 359 PrplWhlRgenMn_Tq_Actl 4095;
BA_ "U_CD764_MY2022_Rx" SG_ 359 TrnAin_Tq_Actl 1;
BA_ "U_U55X_MY2022_Rx" SG_ 359 TrnAin_Tq_Actl 1;
BA_ "U_CD542_MY2021_Rx" SG_ 359 TrnAin_Tq_Actl 1;
BA_ "U_T6_MCA_MY2020_Rx" SG_ 359 TrnAin_Tq_Actl 1;
BA_ "U_P702_MY2021_Rx" SG_ 359 TrnAin_Tq_Actl 1;
BA_ "ContentDependant" SG_ 359 TrnAin_Tq_Actl 1;
BA_ "U_CD764_MY2022_Rx" SG_ 359 PrplWhlTot2_Tq_Actl 1;
BA_ "U_U55X_MY2022_Rx" SG_ 359 PrplWhlTot2_Tq_Actl 1;
BA_ "U_CD542_MY2021_Rx" SG_ 359 PrplWhlTot2_Tq_Actl 1;
BA_ "U_T6_MCA_MY2020_Rx" SG_ 359 PrplWhlTot2_Tq_Actl 1;
BA_ "U_P702_MY2021_Rx" SG_ 359 PrplWhlTot2_Tq_Actl 1;
BA_ "U_CX727_MY2021_Rx" SG_ 359 PwPckTq_D_Stat 1;
BA_ "U_CD764_MY2022_Rx" SG_ 359 PwPckTq_D_Stat 1;
BA_ "U_U55X_MY2022_Rx" SG_ 359 PwPckTq_D_Stat 1;
BA_ "U_CD542_MY2021_Rx" SG_ 359 PwPckTq_D_Stat 1;
BA_ "U_T6_MCA_MY2020_Rx" SG_ 359 PwPckTq_D_Stat 1;
BA_ "U_P702_MY2021_Rx" SG_ 359 PwPckTq_D_Stat 1;
BA_ "U_CD764_MY2022_Rx" SG_ 359 Eng_D_Stat 1;
BA_ "U_U55X_MY2022_Rx" SG_ 359 Eng_D_Stat 1;
BA_ "U_CD542_MY2021_Rx" SG_ 359 Eng_D_Stat 1;
BA_ "U_T6_MCA_MY2020_Rx" SG_ 359 Eng_D_Stat 1;
BA_ "U_P702_MY2021_Rx" SG_ 359 Eng_D_Stat 1;
BA_ "U_CD764_MY2022_Rx" SG_ 359 PlgActvArb_B_Actl 1;
BA_ "GenSigStartValue" SG_ 359 PlgActvArb_B_Actl 1;
BA_ "ContentDependant" SG_ 359 PlgActvArb_B_Actl 1;
BA_ "GenSigStartValueInteger" SG_ 359 PlgActvArb_B_Actl 1;
BA_ "U_CD764_MY2022_Rx" SG_ 359 ElPw_D_Stat 1;
BA_ "U_U55X_MY2022_Rx" SG_ 359 ElPw_D_Stat 1;
BA_ "U_CD542_MY2021_Rx" SG_ 359 ElPw_D_Stat 1;
BA_ "U_T6_MCA_MY2020_Rx" SG_ 359 ElPw_D_Stat 1;
BA_ "U_P702_MY2021_Rx" SG_ 359 ElPw_D_Stat 1;
BA_ "U_U55X_MY2022_Rx" SG_ 359 TrnAinTq_D_Qf 1;
BA_ "U_CD542_MY2021_Rx" SG_ 359 TrnAinTq_D_Qf 1;
BA_ "U_T6_MCA_MY2020_Rx" SG_ 359 TrnAinTq_D_Qf 1;
BA_ "U_P702_MY2021_Rx" SG_ 359 TrnAinTq_D_Qf 1;
BA_ "MetaData" SG_ 359 TrnAinTq_D_Qf 1;
BA_ "ContentDependant" SG_ 359 TrnAinTq_D_Qf 1;
BA_ "U_CD764_MY2022_Rx" SG_ 990 PersIndexDdm_D_Actl 1;
BA_ "U_CD542_MY2021_Rx" SG_ 990 PersIndexDdm_D_Actl 1;
BA_ "U_P702_MY2021_Rx" SG_ 990 PersIndexDdm_D_Actl 1;
BA_ "U_U55X_MY2022_Rx" SG_ 990 PersIndexDdm_D_Actl 1;
BA_ "U_T6_MCA_MY2020_Rx" SG_ 990 PersIndexDdm_D_Actl 1;
BA_ "GenSigStartValue" SG_ 990 PersIndexDdm_D_Actl 4;
BA_ "GenSigStartValueInteger" SG_ 990 PersIndexDdm_D_Actl 4;
BA_ "U_CD764_MY2022_Rx" SG_ 990 FeatNoDdm_No_Actl 1;
BA_ "U_U55X_MY2022_Rx" SG_ 990 FeatNoDdm_No_Actl 1;
BA_ "U_CD542_MY2021_Rx" SG_ 990 FeatNoDdm_No_Actl 1;
BA_ "U_T6_MCA_MY2020_Rx" SG_ 990 FeatNoDdm_No_Actl 1;
BA_ "U_P702_MY2021_Rx" SG_ 990 FeatNoDdm_No_Actl 1;
BA_ "U_CD764_MY2022_Rx" SG_ 990 FeatConfigDdmActl 1;
BA_ "U_U55X_MY2022_Rx" SG_ 990 FeatConfigDdmActl 1;
BA_ "U_CD542_MY2021_Rx" SG_ 990 FeatConfigDdmActl 1;
BA_ "U_T6_MCA_MY2020_Rx" SG_ 990 FeatConfigDdmActl 1;
BA_ "U_P702_MY2021_Rx" SG_ 990 FeatConfigDdmActl 1;
BA_ "U_CD764_MY2022_Rx" SG_ 989 FeatNoHcm_No_Actl 1;
BA_ "U_U55X_MY2022_Rx" SG_ 989 FeatNoHcm_No_Actl 1;
BA_ "U_CD542_MY2021_Rx" SG_ 989 FeatNoHcm_No_Actl 1;
BA_ "U_T6_MCA_MY2020_Rx" SG_ 989 FeatNoHcm_No_Actl 1;
BA_ "U_P702_MY2021_Rx" SG_ 989 FeatNoHcm_No_Actl 1;
BA_ "U_CD764_MY2022_Rx" SG_ 989 FeatConfigHcmActl 1;
BA_ "U_U55X_MY2022_Rx" SG_ 989 FeatConfigHcmActl 1;
BA_ "U_CD542_MY2021_Rx" SG_ 989 FeatConfigHcmActl 1;
BA_ "U_T6_MCA_MY2020_Rx" SG_ 989 FeatConfigHcmActl 1;
BA_ "U_P702_MY2021_Rx" SG_ 989 FeatConfigHcmActl 1;
BA_ "MetaData" SG_ 1246 TrlrBrkCtl2BFalt_No_Cs 1;
BA_ "MetaData" SG_ 1246 TrlrBrkCtl2BFalt_No_Cnt 1;
BA_ "GenSigSendType" SG_ 1246 TrlrBrkCtl2_B_Falt 3;
BA_ "GenSigSendType" SG_ 890 ActvNseMute_D_Rq 3;
BA_ "U_U55X_MY2022_Tx" SG_ 890 ActvNseAudio_D_Stat 1;
BA_ "U_T6_MCA_MY2020_Tx" SG_ 890 ActvNseAudio_D_Stat 1;
BA_ "U_CD764_MY2022_Rx" SG_ 890 ActvNseAudio_D_Stat 1;
BA_ "U_U55X_MY2022_Rx" SG_ 890 ActvNseAudio_D_Stat 1;
BA_ "U_CD542_MY2021_Rx" SG_ 890 ActvNseAudio_D_Stat 1;
BA_ "U_T6_MCA_MY2020_Rx" SG_ 890 ActvNseAudio_D_Stat 1;
BA_ "U_P702_MY2021_Rx" SG_ 890 ActvNseAudio_D_Stat 1;
BA_ "GenSigSendType" SG_ 890 ActvNseAudio_D_Stat 3;
BA_ "U_U55X_MY2022_Tx" SG_ 890 ActvNse_B_Actv 1;
BA_ "U_T6_MCA_MY2020_Tx" SG_ 890 ActvNse_B_Actv 1;
BA_ "U_CD764_MY2022_Rx" SG_ 890 ActvNse_B_Actv 1;
BA_ "U_U55X_MY2022_Rx" SG_ 890 ActvNse_B_Actv 1;
BA_ "U_CD542_MY2021_Rx" SG_ 890 ActvNse_B_Actv 1;
BA_ "U_T6_MCA_MY2020_Rx" SG_ 890 ActvNse_B_Actv 1;
BA_ "U_P702_MY2021_Rx" SG_ 890 ActvNse_B_Actv 1;
BA_ "GenSigSendType" SG_ 890 ActvNse_B_Actv 3;
BA_ "U_CD764_MY2022_Tx" SG_ 1439 WCM_GWOnBoardTester 1;
BA_ "U_U55X_MY2022_Tx" SG_ 1439 WCM_GWOnBoardTester 1;
BA_ "U_CD542_MY2021_Tx" SG_ 1439 WCM_GWOnBoardTester 1;
BA_ "U_T6_MCA_MY2020_Tx" SG_ 1439 WCM_GWOnBoardTester 1;
BA_ "U_P702_MY2021_Tx" SG_ 1439 WCM_GWOnBoardTester 1;
BA_ "U_CX727_MY2021_Tx" SG_ 1439 WCM_GWOnBoardTester 1;
BA_ "U_CD764_MY2022_Rx" SG_ 1439 WCM_GWOnBoardTester 1;
BA_ "U_U55X_MY2022_Rx" SG_ 1439 WCM_GWOnBoardTester 1;
BA_ "U_T6_MCA_MY2020_Rx" SG_ 1439 WCM_GWOnBoardTester 1;
BA_ "GenSigStartValue" SG_ 1439 WCM_GWOnBoardTester 255;
BA_ "ContentDependant" SG_ 1439 WCM_GWOnBoardTester 1;
BA_ "GenSigStartValueInteger" SG_ 1439 WCM_GWOnBoardTester 255;
BA_ "U_CD764_MY2022_Tx" SG_ 1439 WCM_GWNMProxy 1;
BA_ "U_U55X_MY2022_Tx" SG_ 1439 WCM_GWNMProxy 1;
BA_ "U_CD542_MY2021_Tx" SG_ 1439 WCM_GWNMProxy 1;
BA_ "U_T6_MCA_MY2020_Tx" SG_ 1439 WCM_GWNMProxy 1;
BA_ "U_P702_MY2021_Tx" SG_ 1439 WCM_GWNMProxy 1;
BA_ "U_CX727_MY2021_Tx" SG_ 1439 WCM_GWNMProxy 1;
BA_ "U_CD764_MY2022_Rx" SG_ 1439 WCM_GWNMProxy 1;
BA_ "U_U55X_MY2022_Rx" SG_ 1439 WCM_GWNMProxy 1;
BA_ "U_T6_MCA_MY2020_Rx" SG_ 1439 WCM_GWNMProxy 1;
BA_ "GenSigStartValue" SG_ 1439 WCM_GWNMProxy 255;
BA_ "ContentDependant" SG_ 1439 WCM_GWNMProxy 1;
BA_ "GenSigStartValueInteger" SG_ 1439 WCM_GWNMProxy 255;
BA_ "U_CD764_MY2022_Tx" SG_ 1439 WCM_AutoSarNMReserved4 1;
BA_ "U_U55X_MY2022_Tx" SG_ 1439 WCM_AutoSarNMReserved4 1;
BA_ "U_CD542_MY2021_Tx" SG_ 1439 WCM_AutoSarNMReserved4 1;
BA_ "U_T6_MCA_MY2020_Tx" SG_ 1439 WCM_AutoSarNMReserved4 1;
BA_ "U_P702_MY2021_Tx" SG_ 1439 WCM_AutoSarNMReserved4 1;
BA_ "U_CX727_MY2021_Tx" SG_ 1439 WCM_AutoSarNMReserved4 1;
BA_ "U_CD764_MY2022_Rx" SG_ 1439 WCM_AutoSarNMReserved4 1;
BA_ "U_U55X_MY2022_Rx" SG_ 1439 WCM_AutoSarNMReserved4 1;
BA_ "U_T6_MCA_MY2020_Rx" SG_ 1439 WCM_AutoSarNMReserved4 1;
BA_ "GenSigStartValue" SG_ 1439 WCM_AutoSarNMReserved4 255;
BA_ "ContentDependant" SG_ 1439 WCM_AutoSarNMReserved4 1;
BA_ "GenSigStartValueInteger" SG_ 1439 WCM_AutoSarNMReserved4 255;
BA_ "U_CD764_MY2022_Tx" SG_ 1439 WCM_AutoSarNMReserved3 1;
BA_ "U_U55X_MY2022_Tx" SG_ 1439 WCM_AutoSarNMReserved3 1;
BA_ "U_CD542_MY2021_Tx" SG_ 1439 WCM_AutoSarNMReserved3 1;
BA_ "U_T6_MCA_MY2020_Tx" SG_ 1439 WCM_AutoSarNMReserved3 1;
BA_ "U_P702_MY2021_Tx" SG_ 1439 WCM_AutoSarNMReserved3 1;
BA_ "U_CX727_MY2021_Tx" SG_ 1439 WCM_AutoSarNMReserved3 1;
BA_ "U_CD764_MY2022_Rx" SG_ 1439 WCM_AutoSarNMReserved3 1;
BA_ "U_U55X_MY2022_Rx" SG_ 1439 WCM_AutoSarNMReserved3 1;
BA_ "U_T6_MCA_MY2020_Rx" SG_ 1439 WCM_AutoSarNMReserved3 1;
BA_ "GenSigStartValue" SG_ 1439 WCM_AutoSarNMReserved3 255;
BA_ "ContentDependant" SG_ 1439 WCM_AutoSarNMReserved3 1;
BA_ "GenSigStartValueInteger" SG_ 1439 WCM_AutoSarNMReserved3 255;
BA_ "U_CD764_MY2022_Tx" SG_ 1439 WCM_AutoSarNMReserved2 1;
BA_ "U_U55X_MY2022_Tx" SG_ 1439 WCM_AutoSarNMReserved2 1;
BA_ "U_CD542_MY2021_Tx" SG_ 1439 WCM_AutoSarNMReserved2 1;
BA_ "U_T6_MCA_MY2020_Tx" SG_ 1439 WCM_AutoSarNMReserved2 1;
BA_ "U_P702_MY2021_Tx" SG_ 1439 WCM_AutoSarNMReserved2 1;
BA_ "U_CX727_MY2021_Tx" SG_ 1439 WCM_AutoSarNMReserved2 1;
BA_ "U_CD764_MY2022_Rx" SG_ 1439 WCM_AutoSarNMReserved2 1;
BA_ "U_U55X_MY2022_Rx" SG_ 1439 WCM_AutoSarNMReserved2 1;
BA_ "U_T6_MCA_MY2020_Rx" SG_ 1439 WCM_AutoSarNMReserved2 1;
BA_ "GenSigStartValue" SG_ 1439 WCM_AutoSarNMReserved2 255;
BA_ "ContentDependant" SG_ 1439 WCM_AutoSarNMReserved2 1;
BA_ "GenSigStartValueInteger" SG_ 1439 WCM_AutoSarNMReserved2 255;
BA_ "U_CD764_MY2022_Tx" SG_ 1439 WCM_AutoSarNMReserved1 1;
BA_ "U_U55X_MY2022_Tx" SG_ 1439 WCM_AutoSarNMReserved1 1;
BA_ "U_CD542_MY2021_Tx" SG_ 1439 WCM_AutoSarNMReserved1 1;
BA_ "U_T6_MCA_MY2020_Tx" SG_ 1439 WCM_AutoSarNMReserved1 1;
BA_ "U_P702_MY2021_Tx" SG_ 1439 WCM_AutoSarNMReserved1 1;
BA_ "U_CX727_MY2021_Tx" SG_ 1439 WCM_AutoSarNMReserved1 1;
BA_ "U_CD764_MY2022_Rx" SG_ 1439 WCM_AutoSarNMReserved1 1;
BA_ "U_U55X_MY2022_Rx" SG_ 1439 WCM_AutoSarNMReserved1 1;
BA_ "U_T6_MCA_MY2020_Rx" SG_ 1439 WCM_AutoSarNMReserved1 1;
BA_ "GenSigStartValue" SG_ 1439 WCM_AutoSarNMReserved1 255;
BA_ "ContentDependant" SG_ 1439 WCM_AutoSarNMReserved1 1;
BA_ "GenSigStartValueInteger" SG_ 1439 WCM_AutoSarNMReserved1 255;
BA_ "U_CD764_MY2022_Tx" SG_ 1439 WCM_AutoSarNMNodeId 1;
BA_ "U_U55X_MY2022_Tx" SG_ 1439 WCM_AutoSarNMNodeId 1;
BA_ "U_CD542_MY2021_Tx" SG_ 1439 WCM_AutoSarNMNodeId 1;
BA_ "U_T6_MCA_MY2020_Tx" SG_ 1439 WCM_AutoSarNMNodeId 1;
BA_ "U_P702_MY2021_Tx" SG_ 1439 WCM_AutoSarNMNodeId 1;
BA_ "U_CX727_MY2021_Tx" SG_ 1439 WCM_AutoSarNMNodeId 1;
BA_ "U_CD764_MY2022_Rx" SG_ 1439 WCM_AutoSarNMNodeId 1;
BA_ "U_U55X_MY2022_Rx" SG_ 1439 WCM_AutoSarNMNodeId 1;
BA_ "U_T6_MCA_MY2020_Rx" SG_ 1439 WCM_AutoSarNMNodeId 1;
BA_ "GenSigStartValue" SG_ 1439 WCM_AutoSarNMNodeId 159;
BA_ "ContentDependant" SG_ 1439 WCM_AutoSarNMNodeId 1;
BA_ "GenSigStartValueInteger" SG_ 1439 WCM_AutoSarNMNodeId 31;
BA_ "U_CD764_MY2022_Tx" SG_ 1439 WCM_AutoSarNMControl 1;
BA_ "U_U55X_MY2022_Tx" SG_ 1439 WCM_AutoSarNMControl 1;
BA_ "U_CD542_MY2021_Tx" SG_ 1439 WCM_AutoSarNMControl 1;
BA_ "U_T6_MCA_MY2020_Tx" SG_ 1439 WCM_AutoSarNMControl 1;
BA_ "U_P702_MY2021_Tx" SG_ 1439 WCM_AutoSarNMControl 1;
BA_ "U_CX727_MY2021_Tx" SG_ 1439 WCM_AutoSarNMControl 1;
BA_ "U_CD764_MY2022_Rx" SG_ 1439 WCM_AutoSarNMControl 1;
BA_ "U_U55X_MY2022_Rx" SG_ 1439 WCM_AutoSarNMControl 1;
BA_ "U_T6_MCA_MY2020_Rx" SG_ 1439 WCM_AutoSarNMControl 1;
BA_ "ContentDependant" SG_ 1439 WCM_AutoSarNMControl 1;
BA_ "U_CD764_MY2022_Tx" SG_ 261 ChrgStatDsply_D_Rq 1;
BA_ "U_CD542_MY2021_Tx" SG_ 261 ChrgStatDsply_D_Rq 1;
BA_ "U_U55X_MY2022_Tx" SG_ 261 ChrgStatDsply_D_Rq 1;
BA_ "U_T6_MCA_MY2020_Tx" SG_ 261 ChrgStatDsply_D_Rq 1;
BA_ "U_P702_MY2021_Tx" SG_ 261 ChrgStatDsply_D_Rq 1;
BA_ "GenSigSendType" SG_ 261 ChrgStatDsply_D_Rq 3;
BA_ "GenSigStartValue" SG_ 261 ChrgStatDsply_D_Rq 1;
BA_ "GenSigStartValueInteger" SG_ 261 ChrgStatDsply_D_Rq 1;
BA_ "U_T6_MCA_MY2020_Tx" SG_ 261 AudioToneTouchY_D_Rq 1;
BA_ "U_CD542_MY2021_Tx" SG_ 261 AudioToneTouchY_D_Rq 1;
BA_ "U_U55X_MY2022_Tx" SG_ 261 AudioToneTouchY_D_Rq 1;
BA_ "U_T6_MCA_MY2020_Rx" SG_ 261 AudioToneTouchY_D_Rq 1;
BA_ "GenSigSendType" SG_ 261 AudioToneTouchY_D_Rq 3;
BA_ "U_CD542_MY2021_Tx" SG_ 261 AudioToneTouchX_D_Rq 1;
BA_ "U_T6_MCA_MY2020_Tx" SG_ 261 AudioToneTouchX_D_Rq 1;
BA_ "U_U55X_MY2022_Tx" SG_ 261 AudioToneTouchX_D_Rq 1;
BA_ "U_T6_MCA_MY2020_Rx" SG_ 261 AudioToneTouchX_D_Rq 1;
BA_ "GenSigSendType" SG_ 261 AudioToneTouchX_D_Rq 3;
BA_ "U_CD542_MY2021_Tx" SG_ 261 AudioToneTouch_D_Rq 1;
BA_ "U_T6_MCA_MY2020_Tx" SG_ 261 AudioToneTouch_D_Rq 1;
BA_ "U_U55X_MY2022_Tx" SG_ 261 AudioToneTouch_D_Rq 1;
BA_ "U_T6_MCA_MY2020_Rx" SG_ 261 AudioToneTouch_D_Rq 1;
BA_ "GenSigSendType" SG_ 261 AudioToneTouch_D_Rq 3;
BA_ "U_CD542_MY2021_Tx" SG_ 261 OffPeakTimeSetMin_Rq 1;
BA_ "U_U55X_MY2022_Tx" SG_ 261 OffPeakTimeSetMin_Rq 1;
BA_ "U_T6_MCA_MY2020_Tx" SG_ 261 OffPeakTimeSetMin_Rq 1;
BA_ "U_P702_MY2021_Tx" SG_ 261 OffPeakTimeSetMin_Rq 1;
BA_ "GenSigSendType" SG_ 261 OffPeakTimeSetMin_Rq 3;
BA_ "U_CD542_MY2021_Tx" SG_ 261 OffPeakTimeSetHR_Rq 1;
BA_ "U_U55X_MY2022_Tx" SG_ 261 OffPeakTimeSetHR_Rq 1;
BA_ "U_T6_MCA_MY2020_Tx" SG_ 261 OffPeakTimeSetHR_Rq 1;
BA_ "U_P702_MY2021_Tx" SG_ 261 OffPeakTimeSetHR_Rq 1;
BA_ "GenSigSendType" SG_ 261 OffPeakTimeSetHR_Rq 3;
BA_ "U_CD542_MY2021_Tx" SG_ 261 NextUsageTimeToggle_Rq 1;
BA_ "U_U55X_MY2022_Tx" SG_ 261 NextUsageTimeToggle_Rq 1;
BA_ "U_T6_MCA_MY2020_Tx" SG_ 261 NextUsageTimeToggle_Rq 1;
BA_ "U_P702_MY2021_Tx" SG_ 261 NextUsageTimeToggle_Rq 1;
BA_ "GenSigSendType" SG_ 261 NextUsageTimeToggle_Rq 3;
BA_ "U_CD542_MY2021_Tx" SG_ 261 LongTermParking_Rq 1;
BA_ "U_U55X_MY2022_Tx" SG_ 261 LongTermParking_Rq 1;
BA_ "U_T6_MCA_MY2020_Tx" SG_ 261 LongTermParking_Rq 1;
BA_ "U_P702_MY2021_Tx" SG_ 261 LongTermParking_Rq 1;
BA_ "GenSigSendType" SG_ 261 LongTermParking_Rq 3;
BA_ "U_CD542_MY2021_Tx" SG_ 261 CbnCmrtPrefLstNmItm_Rq 1;
BA_ "U_U55X_MY2022_Tx" SG_ 261 CbnCmrtPrefLstNmItm_Rq 1;
BA_ "U_T6_MCA_MY2020_Tx" SG_ 261 CbnCmrtPrefLstNmItm_Rq 1;
BA_ "U_P702_MY2021_Tx" SG_ 261 CbnCmrtPrefLstNmItm_Rq 1;
BA_ "GenSigSendType" SG_ 261 CbnCmrtPrefLstNmItm_Rq 3;
BA_ "U_CD542_MY2021_Tx" SG_ 261 CbnCmrtPrefListIndx_Rq 1;
BA_ "U_U55X_MY2022_Tx" SG_ 261 CbnCmrtPrefListIndx_Rq 1;
BA_ "U_T6_MCA_MY2020_Tx" SG_ 261 CbnCmrtPrefListIndx_Rq 1;
BA_ "U_P702_MY2021_Tx" SG_ 261 CbnCmrtPrefListIndx_Rq 1;
BA_ "GenSigSendType" SG_ 261 CbnCmrtPrefListIndx_Rq 3;
BA_ "U_CD764_MY2022_Tx" SG_ 261 ModemReset_D_Rq 1;
BA_ "U_CD542_MY2021_Tx" SG_ 261 ModemReset_D_Rq 1;
BA_ "U_U55X_MY2022_Tx" SG_ 261 ModemReset_D_Rq 1;
BA_ "U_T6_MCA_MY2020_Tx" SG_ 261 ModemReset_D_Rq 1;
BA_ "U_P702_MY2021_Tx" SG_ 261 ModemReset_D_Rq 1;
BA_ "U_CD764_MY2022_Rx" SG_ 261 ModemReset_D_Rq 1;
BA_ "U_U55X_MY2022_Rx" SG_ 261 ModemReset_D_Rq 1;
BA_ "U_CD542_MY2021_Rx" SG_ 261 ModemReset_D_Rq 1;
BA_ "ECGUsedRxSignal" SG_ 261 ModemReset_D_Rq 1;
BA_ "U_T6_MCA_MY2020_Rx" SG_ 261 ModemReset_D_Rq 1;
BA_ "GenSigSendType" SG_ 261 ModemReset_D_Rq 3;
BA_ "U_CD764_MY2022_Tx" SG_ 261 StopStrtDrvMde_B_RqBtn3 1;
BA_ "U_CD542_MY2021_Tx" SG_ 261 StopStrtDrvMde_B_RqBtn3 1;
BA_ "U_U55X_MY2022_Tx" SG_ 261 StopStrtDrvMde_B_RqBtn3 1;
BA_ "U_T6_MCA_MY2020_Tx" SG_ 261 StopStrtDrvMde_B_RqBtn3 1;
BA_ "U_P702_MY2021_Tx" SG_ 261 StopStrtDrvMde_B_RqBtn3 1;
BA_ "GenSigSendType" SG_ 261 StopStrtDrvMde_B_RqBtn3 3;
BA_ "U_CD542_MY2021_Tx" SG_ 261 TCU_ESN_D_Rq 1;
BA_ "U_P702_MY2021_Tx" SG_ 261 TCU_ESN_D_Rq 1;
BA_ "U_U55X_MY2022_Tx" SG_ 261 TCU_ESN_D_Rq 1;
BA_ "U_T6_MCA_MY2020_Tx" SG_ 261 TCU_ESN_D_Rq 1;
BA_ "GenSigSendType" SG_ 261 TCU_ESN_D_Rq 3;
BA_ "U_CD764_MY2022_Tx" SG_ 261 FactoryReset_Rq 1;
BA_ "U_CD542_MY2021_Tx" SG_ 261 FactoryReset_Rq 1;
BA_ "U_U55X_MY2022_Tx" SG_ 261 FactoryReset_Rq 1;
BA_ "U_T6_MCA_MY2020_Tx" SG_ 261 FactoryReset_Rq 1;
BA_ "U_P702_MY2021_Tx" SG_ 261 FactoryReset_Rq 1;
BA_ "U_CD764_MY2022_Rx" SG_ 261 FactoryReset_Rq 1;
BA_ "U_U55X_MY2022_Rx" SG_ 261 FactoryReset_Rq 1;
BA_ "U_CD542_MY2021_Rx" SG_ 261 FactoryReset_Rq 1;
BA_ "ECGUsedRxSignal" SG_ 261 FactoryReset_Rq 1;
BA_ "U_T6_MCA_MY2020_Rx" SG_ 261 FactoryReset_Rq 1;
BA_ "GenSigSendType" SG_ 261 FactoryReset_Rq 3;
BA_ "U_CD542_MY2021_Tx" SG_ 261 OffPeakTimeSetType_Rq 1;
BA_ "U_U55X_MY2022_Tx" SG_ 261 OffPeakTimeSetType_Rq 1;
BA_ "U_T6_MCA_MY2020_Tx" SG_ 261 OffPeakTimeSetType_Rq 1;
BA_ "U_P702_MY2021_Tx" SG_ 261 OffPeakTimeSetType_Rq 1;
BA_ "GenSigSendType" SG_ 261 OffPeakTimeSetType_Rq 3;
BA_ "U_CD764_MY2022_Rx" SG_ 995 KeyAssocCmplt_B_Rq 1;
BA_ "U_U55X_MY2022_Rx" SG_ 995 KeyAssocCmplt_B_Rq 1;
BA_ "U_CD542_MY2021_Rx" SG_ 995 KeyAssocCmplt_B_Rq 1;
BA_ "U_T6_MCA_MY2020_Rx" SG_ 995 KeyAssocCmplt_B_Rq 1;
BA_ "U_CD764_MY2022_Rx" SG_ 995 FobAssocChime_B_Rq 1;
BA_ "U_U55X_MY2022_Rx" SG_ 995 FobAssocChime_B_Rq 1;
BA_ "U_CD542_MY2021_Rx" SG_ 995 FobAssocChime_B_Rq 1;
BA_ "U_T6_MCA_MY2020_Rx" SG_ 995 FobAssocChime_B_Rq 1;
BA_ "U_CD764_MY2022_Rx" SG_ 995 PersIndexBcm_D_Actl 1;
BA_ "U_U55X_MY2022_Rx" SG_ 995 PersIndexBcm_D_Actl 1;
BA_ "U_CD542_MY2021_Rx" SG_ 995 PersIndexBcm_D_Actl 1;
BA_ "U_T6_MCA_MY2020_Rx" SG_ 995 PersIndexBcm_D_Actl 1;
BA_ "U_P702_MY2021_Rx" SG_ 995 PersIndexBcm_D_Actl 1;
BA_ "GenSigStartValue" SG_ 995 PersIndexBcm_D_Actl 4;
BA_ "GenSigStartValueInteger" SG_ 995 PersIndexBcm_D_Actl 4;
BA_ "U_CD764_MY2022_Rx" SG_ 995 FeatNoBcm_No_Actl 1;
BA_ "U_U55X_MY2022_Rx" SG_ 995 FeatNoBcm_No_Actl 1;
BA_ "U_CD542_MY2021_Rx" SG_ 995 FeatNoBcm_No_Actl 1;
BA_ "U_T6_MCA_MY2020_Rx" SG_ 995 FeatNoBcm_No_Actl 1;
BA_ "U_P702_MY2021_Rx" SG_ 995 FeatNoBcm_No_Actl 1;
BA_ "U_CD764_MY2022_Rx" SG_ 995 FeatConfigBcmActl 1;
BA_ "U_U55X_MY2022_Rx" SG_ 995 FeatConfigBcmActl 1;
BA_ "U_CD542_MY2021_Rx" SG_ 995 FeatConfigBcmActl 1;
BA_ "U_T6_MCA_MY2020_Rx" SG_ 995 FeatConfigBcmActl 1;
BA_ "U_P702_MY2021_Rx" SG_ 995 FeatConfigBcmActl 1;
BA_ "U_CD764_MY2022_Rx" SG_ 995 LightAmbIntsty_No_Actl 1;
BA_ "U_U55X_MY2022_Rx" SG_ 995 LightAmbIntsty_No_Actl 1;
BA_ "U_CD542_MY2021_Rx" SG_ 995 LightAmbIntsty_No_Actl 1;
BA_ "U_T6_MCA_MY2020_Rx" SG_ 995 LightAmbIntsty_No_Actl 1;
BA_ "U_P702_MY2021_Rx" SG_ 995 LightAmbIntsty_No_Actl 1;
BA_ "U_CD764_MY2022_Rx" SG_ 995 LightAmbColor_No_Actl 1;
BA_ "U_U55X_MY2022_Rx" SG_ 995 LightAmbColor_No_Actl 1;
BA_ "U_CD542_MY2021_Rx" SG_ 995 LightAmbColor_No_Actl 1;
BA_ "U_T6_MCA_MY2020_Rx" SG_ 995 LightAmbColor_No_Actl 1;
BA_ "U_P702_MY2021_Rx" SG_ 995 LightAmbColor_No_Actl 1;
BA_ "U_U55X_MY2022_Tx" SG_ 753 RollCodeValet 1;
BA_ "U_CD542_MY2021_Tx" SG_ 753 RollCodeValet 1;
BA_ "U_T6_MCA_MY2020_Tx" SG_ 753 RollCodeValet 1;
BA_ "GenSigSendType" SG_ 753 RollCodeValet 3;
BA_ "U_CD764_MY2022_Tx" SG_ 1000 AHU_Bezel_Diag_St 1;
BA_ "U_U55X_MY2022_Tx" SG_ 1000 AHU_Bezel_Diag_St 1;
BA_ "U_CD542_MY2021_Tx" SG_ 1000 AHU_Bezel_Diag_St 1;
BA_ "U_T6_MCA_MY2020_Tx" SG_ 1000 AHU_Bezel_Diag_St 1;
BA_ "U_P702_MY2021_Tx" SG_ 1000 AHU_Bezel_Diag_St 1;
BA_ "U_U55X_MY2022_Rx" SG_ 1000 AHU_Bezel_Diag_St 1;
BA_ "U_CD542_MY2021_Rx" SG_ 1000 AHU_Bezel_Diag_St 1;
BA_ "U_T6_MCA_MY2020_Rx" SG_ 1000 AHU_Bezel_Diag_St 1;
BA_ "U_P702_MY2021_Rx" SG_ 1000 AHU_Bezel_Diag_St 1;
BA_ "GenSigSendType" SG_ 1000 AHU_Bezel_Diag_St 3;
BA_ "U_CD764_MY2022_Tx" SG_ 1000 ThermalReduction_St 1;
BA_ "U_U55X_MY2022_Tx" SG_ 1000 ThermalReduction_St 1;
BA_ "U_CD542_MY2021_Tx" SG_ 1000 ThermalReduction_St 1;
BA_ "U_T6_MCA_MY2020_Tx" SG_ 1000 ThermalReduction_St 1;
BA_ "U_P702_MY2021_Tx" SG_ 1000 ThermalReduction_St 1;
BA_ "U_CD764_MY2022_Rx" SG_ 1000 ThermalReduction_St 1;
BA_ "U_U55X_MY2022_Rx" SG_ 1000 ThermalReduction_St 1;
BA_ "U_CD542_MY2021_Rx" SG_ 1000 ThermalReduction_St 1;
BA_ "U_T6_MCA_MY2020_Rx" SG_ 1000 ThermalReduction_St 1;
BA_ "U_P702_MY2021_Rx" SG_ 1000 ThermalReduction_St 1;
BA_ "GenSigSendType" SG_ 1000 ThermalReduction_St 3;
BA_ "U_CD764_MY2022_Tx" SG_ 1000 AHU_Shaker_St 1;
BA_ "U_U55X_MY2022_Tx" SG_ 1000 AHU_Shaker_St 1;
BA_ "U_CD542_MY2021_Tx" SG_ 1000 AHU_Shaker_St 1;
BA_ "U_T6_MCA_MY2020_Tx" SG_ 1000 AHU_Shaker_St 1;
BA_ "U_P702_MY2021_Tx" SG_ 1000 AHU_Shaker_St 1;
BA_ "U_U55X_MY2022_Rx" SG_ 1000 AHU_Shaker_St 1;
BA_ "U_CD542_MY2021_Rx" SG_ 1000 AHU_Shaker_St 1;
BA_ "U_T6_MCA_MY2020_Rx" SG_ 1000 AHU_Shaker_St 1;
BA_ "U_P702_MY2021_Rx" SG_ 1000 AHU_Shaker_St 1;
BA_ "GenSigSendType" SG_ 1000 AHU_Shaker_St 3;
BA_ "U_CD764_MY2022_Tx" SG_ 1000 ACM_BeltminderAudioSt 1;
BA_ "U_U55X_MY2022_Tx" SG_ 1000 ACM_BeltminderAudioSt 1;
BA_ "U_CD542_MY2021_Tx" SG_ 1000 ACM_BeltminderAudioSt 1;
BA_ "U_T6_MCA_MY2020_Tx" SG_ 1000 ACM_BeltminderAudioSt 1;
BA_ "U_P702_MY2021_Tx" SG_ 1000 ACM_BeltminderAudioSt 1;
BA_ "U_U55X_MY2022_Rx" SG_ 1000 ACM_BeltminderAudioSt 1;
BA_ "U_CD542_MY2021_Rx" SG_ 1000 ACM_BeltminderAudioSt 1;
BA_ "U_T6_MCA_MY2020_Rx" SG_ 1000 ACM_BeltminderAudioSt 1;
BA_ "U_P702_MY2021_Rx" SG_ 1000 ACM_BeltminderAudioSt 1;
BA_ "GenSigSendType" SG_ 1000 ACM_BeltminderAudioSt 3;
BA_ "U_CD764_MY2022_Tx" SG_ 1000 MyKeyVolumeLimitUp 1;
BA_ "U_U55X_MY2022_Tx" SG_ 1000 MyKeyVolumeLimitUp 1;
BA_ "U_CD542_MY2021_Tx" SG_ 1000 MyKeyVolumeLimitUp 1;
BA_ "U_T6_MCA_MY2020_Tx" SG_ 1000 MyKeyVolumeLimitUp 1;
BA_ "U_P702_MY2021_Tx" SG_ 1000 MyKeyVolumeLimitUp 1;
BA_ "U_U55X_MY2022_Rx" SG_ 1000 MyKeyVolumeLimitUp 1;
BA_ "U_CD542_MY2021_Rx" SG_ 1000 MyKeyVolumeLimitUp 1;
BA_ "U_T6_MCA_MY2020_Rx" SG_ 1000 MyKeyVolumeLimitUp 1;
BA_ "U_P702_MY2021_Rx" SG_ 1000 MyKeyVolumeLimitUp 1;
BA_ "GenSigSendType" SG_ 1000 MyKeyVolumeLimitUp 3;
BA_ "U_CD764_MY2022_Tx" SG_ 1000 MyKeyVolumeLimitMode 1;
BA_ "U_U55X_MY2022_Tx" SG_ 1000 MyKeyVolumeLimitMode 1;
BA_ "U_CD542_MY2021_Tx" SG_ 1000 MyKeyVolumeLimitMode 1;
BA_ "U_T6_MCA_MY2020_Tx" SG_ 1000 MyKeyVolumeLimitMode 1;
BA_ "U_P702_MY2021_Tx" SG_ 1000 MyKeyVolumeLimitMode 1;
BA_ "U_U55X_MY2022_Rx" SG_ 1000 MyKeyVolumeLimitMode 1;
BA_ "U_CD542_MY2021_Rx" SG_ 1000 MyKeyVolumeLimitMode 1;
BA_ "U_T6_MCA_MY2020_Rx" SG_ 1000 MyKeyVolumeLimitMode 1;
BA_ "U_P702_MY2021_Rx" SG_ 1000 MyKeyVolumeLimitMode 1;
BA_ "GenSigSendType" SG_ 1000 MyKeyVolumeLimitMode 3;
BA_ "U_CD764_MY2022_Tx" SG_ 992 MsgCntrPersIndex_D_Rq 1;
BA_ "U_U55X_MY2022_Tx" SG_ 992 MsgCntrPersIndex_D_Rq 1;
BA_ "U_CD542_MY2021_Tx" SG_ 992 MsgCntrPersIndex_D_Rq 1;
BA_ "U_T6_MCA_MY2020_Tx" SG_ 992 MsgCntrPersIndex_D_Rq 1;
BA_ "U_P702_MY2021_Tx" SG_ 992 MsgCntrPersIndex_D_Rq 1;
BA_ "U_U55X_MY2022_Rx" SG_ 992 MsgCntrPersIndex_D_Rq 1;
BA_ "U_T6_MCA_MY2020_Rx" SG_ 992 MsgCntrPersIndex_D_Rq 1;
BA_ "GenSigSendType" SG_ 992 MsgCntrPersIndex_D_Rq 3;
BA_ "GenSigStartValue" SG_ 992 MsgCntrPersIndex_D_Rq 4;
BA_ "GenSigStartValueInteger" SG_ 992 MsgCntrPersIndex_D_Rq 4;
BA_ "U_CD764_MY2022_Tx" SG_ 992 MsgCntrFeatConfigRq 1;
BA_ "U_U55X_MY2022_Tx" SG_ 992 MsgCntrFeatConfigRq 1;
BA_ "U_CD542_MY2021_Tx" SG_ 992 MsgCntrFeatConfigRq 1;
BA_ "U_T6_MCA_MY2020_Tx" SG_ 992 MsgCntrFeatConfigRq 1;
BA_ "U_P702_MY2021_Tx" SG_ 992 MsgCntrFeatConfigRq 1;
BA_ "U_U55X_MY2022_Rx" SG_ 992 MsgCntrFeatConfigRq 1;
BA_ "U_T6_MCA_MY2020_Rx" SG_ 992 MsgCntrFeatConfigRq 1;
BA_ "GenSigSendType" SG_ 992 MsgCntrFeatConfigRq 3;
BA_ "U_CD764_MY2022_Tx" SG_ 992 MsgCntrFeatNoRq 1;
BA_ "U_U55X_MY2022_Tx" SG_ 992 MsgCntrFeatNoRq 1;
BA_ "U_CD542_MY2021_Tx" SG_ 992 MsgCntrFeatNoRq 1;
BA_ "U_T6_MCA_MY2020_Tx" SG_ 992 MsgCntrFeatNoRq 1;
BA_ "U_P702_MY2021_Tx" SG_ 992 MsgCntrFeatNoRq 1;
BA_ "U_U55X_MY2022_Rx" SG_ 992 MsgCntrFeatNoRq 1;
BA_ "U_T6_MCA_MY2020_Rx" SG_ 992 MsgCntrFeatNoRq 1;
BA_ "GenSigSendType" SG_ 992 MsgCntrFeatNoRq 3;
BA_ "U_CD764_MY2022_Tx" SG_ 992 MsgCntrDsplyOp_D_Rq 1;
BA_ "U_U55X_MY2022_Tx" SG_ 992 MsgCntrDsplyOp_D_Rq 1;
BA_ "U_CD542_MY2021_Tx" SG_ 992 MsgCntrDsplyOp_D_Rq 1;
BA_ "U_T6_MCA_MY2020_Tx" SG_ 992 MsgCntrDsplyOp_D_Rq 1;
BA_ "U_P702_MY2021_Tx" SG_ 992 MsgCntrDsplyOp_D_Rq 1;
BA_ "U_U55X_MY2022_Rx" SG_ 992 MsgCntrDsplyOp_D_Rq 1;
BA_ "U_T6_MCA_MY2020_Rx" SG_ 992 MsgCntrDsplyOp_D_Rq 1;
BA_ "GenSigSendType" SG_ 992 MsgCntrDsplyOp_D_Rq 3;
BA_ "GenSigStartValue" SG_ 991 TrlrTngLoad_D_Stat 6;
BA_ "GenSigStartValue" SG_ 991 Trlr_M_Actl 2046;
BA_ "U_CD764_MY2022_Rx" SG_ 991 PersIndexVdm_D_Actl 1;
BA_ "U_U55X_MY2022_Rx" SG_ 991 PersIndexVdm_D_Actl 1;
BA_ "U_CD542_MY2021_Rx" SG_ 991 PersIndexVdm_D_Actl 1;
BA_ "U_T6_MCA_MY2020_Rx" SG_ 991 PersIndexVdm_D_Actl 1;
BA_ "GenSigStartValue" SG_ 991 PersIndexVdm_D_Actl 4;
BA_ "GenSigStartValueInteger" SG_ 991 PersIndexVdm_D_Actl 4;
BA_ "U_P702_MY2021_Rx" SG_ 991 FeatNoVdmActl 1;
BA_ "U_CD764_MY2022_Rx" SG_ 991 FeatNoVdmActl 1;
BA_ "U_U55X_MY2022_Rx" SG_ 991 FeatNoVdmActl 1;
BA_ "U_CD542_MY2021_Rx" SG_ 991 FeatNoVdmActl 1;
BA_ "U_T6_MCA_MY2020_Rx" SG_ 991 FeatNoVdmActl 1;
BA_ "U_P702_MY2021_Rx" SG_ 991 FeatConfigVdmActl 1;
BA_ "U_CD764_MY2022_Rx" SG_ 991 FeatConfigVdmActl 1;
BA_ "U_U55X_MY2022_Rx" SG_ 991 FeatConfigVdmActl 1;
BA_ "U_CD542_MY2021_Rx" SG_ 991 FeatConfigVdmActl 1;
BA_ "U_T6_MCA_MY2020_Rx" SG_ 991 FeatConfigVdmActl 1;
BA_ "U_CD764_MY2022_Rx" SG_ 1004 Pers4Key_D_Stat 1;
BA_ "U_U55X_MY2022_Rx" SG_ 1004 Pers4Key_D_Stat 1;
BA_ "U_CD542_MY2021_Rx" SG_ 1004 Pers4Key_D_Stat 1;
BA_ "U_T6_MCA_MY2020_Rx" SG_ 1004 Pers4Key_D_Stat 1;
BA_ "U_P702_MY2021_Rx" SG_ 1004 Pers4Key_D_Stat 1;
BA_ "U_CD764_MY2022_Rx" SG_ 1004 Pers3Key_D_Stat 1;
BA_ "U_U55X_MY2022_Rx" SG_ 1004 Pers3Key_D_Stat 1;
BA_ "U_CD542_MY2021_Rx" SG_ 1004 Pers3Key_D_Stat 1;
BA_ "U_T6_MCA_MY2020_Rx" SG_ 1004 Pers3Key_D_Stat 1;
BA_ "U_P702_MY2021_Rx" SG_ 1004 Pers3Key_D_Stat 1;
BA_ "U_CD764_MY2022_Rx" SG_ 1004 Pers2Key_D_Stat 1;
BA_ "U_U55X_MY2022_Rx" SG_ 1004 Pers2Key_D_Stat 1;
BA_ "U_CD542_MY2021_Rx" SG_ 1004 Pers2Key_D_Stat 1;
BA_ "U_T6_MCA_MY2020_Rx" SG_ 1004 Pers2Key_D_Stat 1;
BA_ "U_P702_MY2021_Rx" SG_ 1004 Pers2Key_D_Stat 1;
BA_ "U_CD764_MY2022_Rx" SG_ 1004 Pers1Key_D_Stat 1;
BA_ "U_U55X_MY2022_Rx" SG_ 1004 Pers1Key_D_Stat 1;
BA_ "U_CD542_MY2021_Rx" SG_ 1004 Pers1Key_D_Stat 1;
BA_ "U_T6_MCA_MY2020_Rx" SG_ 1004 Pers1Key_D_Stat 1;
BA_ "U_P702_MY2021_Rx" SG_ 1004 Pers1Key_D_Stat 1;
BA_ "U_CD764_MY2022_Rx" SG_ 1004 EmPrflKeyAssoc_D_Stat 1;
BA_ "U_U55X_MY2022_Rx" SG_ 1004 EmPrflKeyAssoc_D_Stat 1;
BA_ "U_CD542_MY2021_Rx" SG_ 1004 EmPrflKeyAssoc_D_Stat 1;
BA_ "U_T6_MCA_MY2020_Rx" SG_ 1004 EmPrflKeyAssoc_D_Stat 1;
BA_ "U_P702_MY2021_Rx" SG_ 1004 EmPrflKeyAssoc_D_Stat 1;
BA_ "U_CD764_MY2022_Rx" SG_ 1004 VehKeyActv_D_Stat 1;
BA_ "U_U55X_MY2022_Rx" SG_ 1004 VehKeyActv_D_Stat 1;
BA_ "U_CD542_MY2021_Rx" SG_ 1004 VehKeyActv_D_Stat 1;
BA_ "U_T6_MCA_MY2020_Rx" SG_ 1004 VehKeyActv_D_Stat 1;
BA_ "U_U55X_MY2022_Rx" SG_ 1004 PersSetupRestr_D_Actl 1;
BA_ "U_CD542_MY2021_Rx" SG_ 1004 PersSetupRestr_D_Actl 1;
BA_ "U_T6_MCA_MY2020_Rx" SG_ 1004 PersSetupRestr_D_Actl 1;
BA_ "U_P702_MY2021_Rx" SG_ 1004 PersSetupRestr_D_Actl 1;
BA_ "U_U55X_MY2022_Rx" SG_ 1004 PersSetupAccessCtrl 1;
BA_ "U_CD542_MY2021_Rx" SG_ 1004 PersSetupAccessCtrl 1;
BA_ "U_T6_MCA_MY2020_Rx" SG_ 1004 PersSetupAccessCtrl 1;
BA_ "U_P702_MY2021_Rx" SG_ 1004 PersSetupAccessCtrl 1;
BA_ "U_U55X_MY2022_Rx" SG_ 1004 PersSetup_No_Actl 1;
BA_ "U_CD542_MY2021_Rx" SG_ 1004 PersSetup_No_Actl 1;
BA_ "U_T6_MCA_MY2020_Rx" SG_ 1004 PersSetup_No_Actl 1;
BA_ "U_P702_MY2021_Rx" SG_ 1004 PersSetup_No_Actl 1;
BA_ "U_U55X_MY2022_Rx" SG_ 1004 PersConflict_D_Actl 1;
BA_ "U_CD542_MY2021_Rx" SG_ 1004 PersConflict_D_Actl 1;
BA_ "U_T6_MCA_MY2020_Rx" SG_ 1004 PersConflict_D_Actl 1;
BA_ "U_P702_MY2021_Rx" SG_ 1004 PersConflict_D_Actl 1;
BA_ "GenSigStartValue" SG_ 1004 PersConflict_D_Actl 1;
BA_ "GenSigStartValueInteger" SG_ 1004 PersConflict_D_Actl 1;
BA_ "U_CD764_MY2022_Rx" SG_ 1004 AssocConfirm_D_Actl 1;
BA_ "U_U55X_MY2022_Rx" SG_ 1004 AssocConfirm_D_Actl 1;
BA_ "U_CD542_MY2021_Rx" SG_ 1004 AssocConfirm_D_Actl 1;
BA_ "U_T6_MCA_MY2020_Rx" SG_ 1004 AssocConfirm_D_Actl 1;
BA_ "U_P702_MY2021_Rx" SG_ 1004 AssocConfirm_D_Actl 1;
BA_ "U_CD764_MY2022_Rx" SG_ 1004 RecallEvent_No_Cnt 1;
BA_ "U_U55X_MY2022_Rx" SG_ 1004 RecallEvent_No_Cnt 1;
BA_ "U_CD542_MY2021_Rx" SG_ 1004 RecallEvent_No_Cnt 1;
BA_ "U_T6_MCA_MY2020_Rx" SG_ 1004 RecallEvent_No_Cnt 1;
BA_ "U_P702_MY2021_Rx" SG_ 1004 RecallEvent_No_Cnt 1;
BA_ "MetaData" SG_ 1004 RecallEvent_No_Cnt 1;
BA_ "U_P702_MY2021_Rx" SG_ 1004 PersNoPos_D_Actl 1;
BA_ "U_CD764_MY2022_Rx" SG_ 1004 PersNoPos_D_Actl 1;
BA_ "U_U55X_MY2022_Rx" SG_ 1004 PersNoPos_D_Actl 1;
BA_ "U_CD542_MY2021_Rx" SG_ 1004 PersNoPos_D_Actl 1;
BA_ "U_T6_MCA_MY2020_Rx" SG_ 1004 PersNoPos_D_Actl 1;
BA_ "GenSigStartValue" SG_ 1004 PersNoPos_D_Actl 4;
BA_ "GenSigStartValueInteger" SG_ 1004 PersNoPos_D_Actl 4;
BA_ "U_U55X_MY2022_Rx" SG_ 1004 PersNo_D_Actl 1;
BA_ "U_CD764_MY2022_Rx" SG_ 1004 PersNo_D_Actl 1;
BA_ "U_CD542_MY2021_Rx" SG_ 1004 PersNo_D_Actl 1;
BA_ "U_T6_MCA_MY2020_Rx" SG_ 1004 PersNo_D_Actl 1;
BA_ "U_P702_MY2021_Rx" SG_ 1004 PersNo_D_Actl 1;
BA_ "GenSigStartValue" SG_ 1004 PersNo_D_Actl 4;
BA_ "GenSigStartValueInteger" SG_ 1004 PersNo_D_Actl 4;
BA_ "U_CD764_MY2022_Rx" SG_ 1004 EmPrflNo_D_Stat 1;
BA_ "U_U55X_MY2022_Rx" SG_ 1004 EmPrflNo_D_Stat 1;
BA_ "U_CD542_MY2021_Rx" SG_ 1004 EmPrflNo_D_Stat 1;
BA_ "U_T6_MCA_MY2020_Rx" SG_ 1004 EmPrflNo_D_Stat 1;
BA_ "U_P702_MY2021_Rx" SG_ 1004 EmPrflNo_D_Stat 1;
BA_ "U_CD542_MY2021_Rx" SG_ 522 PtDrvMde_D_Stat_UB 1;
BA_ "U_T6_MCA_MY2020_Rx" SG_ 522 PtDrvMde_D_Stat_UB 1;
BA_ "U_P702_MY2021_Rx" SG_ 522 PtDrvMde_D_Stat_UB 1;
BA_ "U_CD542_MY2021_Rx" SG_ 522 PtDrvMde_D_Stat 1;
BA_ "U_T6_MCA_MY2020_Rx" SG_ 522 PtDrvMde_D_Stat 1;
BA_ "U_P702_MY2021_Rx" SG_ 522 PtDrvMde_D_Stat 1;
BA_ "U_U55X_MY2022_Rx" SG_ 522 HsaStat_D_Dsply_UB 1;
BA_ "U_CD542_MY2021_Rx" SG_ 522 HsaStat_D_Dsply_UB 1;
BA_ "U_T6_MCA_MY2020_Rx" SG_ 522 HsaStat_D_Dsply_UB 1;
BA_ "U_U55X_MY2022_Rx" SG_ 522 HsaStat_D_Dsply 1;
BA_ "U_CD542_MY2021_Rx" SG_ 522 HsaStat_D_Dsply 1;
BA_ "U_T6_MCA_MY2020_Rx" SG_ 522 HsaStat_D_Dsply 1;
BA_ "U_CD764_MY2022_Rx" SG_ 522 TrnAout_W_ActlUnfilt_UB 1;
BA_ "U_CD542_MY2021_Rx" SG_ 522 TrnAout_W_ActlUnfilt_UB 1;
BA_ "U_T6_MCA_MY2020_Rx" SG_ 522 TrnAout_W_ActlUnfilt_UB 1;
BA_ "U_P702_MY2021_Rx" SG_ 522 TrnAout_W_ActlUnfilt_UB 1;
BA_ "U_CD764_MY2022_Rx" SG_ 522 TrnAout_W_ActlUnfilt 1;
BA_ "U_CD542_MY2021_Rx" SG_ 522 TrnAout_W_ActlUnfilt 1;
BA_ "U_T6_MCA_MY2020_Rx" SG_ 522 TrnAout_W_ActlUnfilt 1;
BA_ "U_P702_MY2021_Rx" SG_ 522 TrnAout_W_ActlUnfilt 1;
BA_ "U_T6_MCA_MY2020_Rx" SG_ 522 UreaMnAdd_L_Actl_UB 1;
BA_ "U_P702_MY2021_Rx" SG_ 522 UreaMnAdd_L_Actl_UB 1;
BA_ "U_T6_MCA_MY2020_Rx" SG_ 522 UreaMnAdd_L_Actl 1;
BA_ "U_CD764_MY2022_Tx" SG_ 497 McEvntNotfnMsgId_No_Rq 1;
BA_ "U_CD764_MY2022_Rx" SG_ 497 McEvntNotfnMsgId_No_Rq 1;
BA_ "U_U55X_MY2022_Rx" SG_ 497 McEvntNotfnMsgId_No_Rq 1;
BA_ "U_CD764_MY2022_Tx" SG_ 497 McEvntNotfnMsgId_D_Rq 1;
BA_ "U_CD764_MY2022_Rx" SG_ 497 McEvntNotfnMsgId_D_Rq 1;
BA_ "U_U55X_MY2022_Rx" SG_ 497 McEvntNotfnMsgId_D_Rq 1;
BA_ "GenSigSendType" SG_ 497 McEvntNotfnMsgId_D_Rq 3;
BA_ "U_CD764_MY2022_Tx" SG_ 497 McEvntNotfnData3_D_Rq 1;
BA_ "U_CD764_MY2022_Rx" SG_ 497 McEvntNotfnData3_D_Rq 1;
BA_ "U_U55X_MY2022_Rx" SG_ 497 McEvntNotfnData3_D_Rq 1;
BA_ "GenSigSendType" SG_ 497 McEvntNotfnData3_D_Rq 3;
BA_ "U_CD764_MY2022_Tx" SG_ 497 McEvntNotfnData2_D_Rq 1;
BA_ "U_CD764_MY2022_Rx" SG_ 497 McEvntNotfnData2_D_Rq 1;
BA_ "U_U55X_MY2022_Rx" SG_ 497 McEvntNotfnData2_D_Rq 1;
BA_ "GenSigSendType" SG_ 497 McEvntNotfnData2_D_Rq 3;
BA_ "U_CD764_MY2022_Tx" SG_ 497 McEvntNotfnData1_D_Rq 1;
BA_ "U_CD764_MY2022_Rx" SG_ 497 McEvntNotfnData1_D_Rq 1;
BA_ "U_U55X_MY2022_Rx" SG_ 497 McEvntNotfnData1_D_Rq 1;
BA_ "GenSigSendType" SG_ 497 McEvntNotfnData1_D_Rq 3;
BA_ "U_CD764_MY2022_Tx" SG_ 497 McEvntNotfnChoice_D_Rq 1;
BA_ "U_CD764_MY2022_Rx" SG_ 497 McEvntNotfnChoice_D_Rq 1;
BA_ "U_U55X_MY2022_Rx" SG_ 497 McEvntNotfnChoice_D_Rq 1;
BA_ "GenSigSendType" SG_ 497 McEvntNotfnChoice_D_Rq 3;
BA_ "GenSigSendType" SG_ 1049 TrlrId_No_ActlMnu 3;
BA_ "GenSigSendType" SG_ 1049 TrlrRngId_No_RqReset 3;
BA_ "GenSigSendType" SG_ 1049 PersTurnSglView_D_RqMnu 3;
BA_ "GenSigSendType" SG_ 1049 FrontDiffLck_D_RqDrv3 3;
BA_ "GenSigStartValue" SG_ 1049 FrontDiffLck_D_RqDrv3 2;
BA_ "GenSigStartValueInteger" SG_ 1049 FrontDiffLck_D_RqDrv3 2;
BA_ "GenSigSendType" SG_ 1049 RearDiffLck_D_RqDrv3 3;
BA_ "GenSigStartValue" SG_ 1049 RearDiffLck_D_RqDrv3 2;
BA_ "GenSigStartValueInteger" SG_ 1049 RearDiffLck_D_RqDrv3 2;
BA_ "GenSigSendType" SG_ 1049 TrailCtlSwtch_B_Stat4 3;
BA_ "GenSigSendType" SG_ 1049 CamraFrnt_B_RqMnu 3;
BA_ "GenSigSendType" SG_ 1049 StabBarCnncButtn_D_Sta3 3;
BA_ "U_CD764_MY2022_Tx" SG_ 1049 TurnAsstSwtch_D_Stat 1;
BA_ "U_CD542_MY2021_Tx" SG_ 1049 TurnAsstSwtch_D_Stat 1;
BA_ "GenSigSendType" SG_ 1049 TurnAsstSwtch_D_Stat 3;
BA_ "U_CD764_MY2022_Tx" SG_ 1049 SelDrvMdeTxtRst_B_Rq2 1;
BA_ "U_U55X_MY2022_Tx" SG_ 1049 SelDrvMdeTxtRst_B_Rq2 1;
BA_ "U_CD542_MY2021_Tx" SG_ 1049 SelDrvMdeTxtRst_B_Rq2 1;
BA_ "U_T6_MCA_MY2020_Tx" SG_ 1049 SelDrvMdeTxtRst_B_Rq2 1;
BA_ "GenSigSendType" SG_ 1049 SelDrvMdeTxtRst_B_Rq2 3;
BA_ "U_CD764_MY2022_Tx" SG_ 1049 SelDrvMdePage_B_Stat 1;
BA_ "U_U55X_MY2022_Tx" SG_ 1049 SelDrvMdePage_B_Stat 1;
BA_ "U_CD542_MY2021_Tx" SG_ 1049 SelDrvMdePage_B_Stat 1;
BA_ "U_T6_MCA_MY2020_Tx" SG_ 1049 SelDrvMdePage_B_Stat 1;
BA_ "GenSigSendType" SG_ 1049 SelDrvMdePage_B_Stat 3;
BA_ "U_CD764_MY2022_Tx" SG_ 1049 SelDrvMdeCnfm_D_Stat2 1;
BA_ "U_U55X_MY2022_Tx" SG_ 1049 SelDrvMdeCnfm_D_Stat2 1;
BA_ "U_CD542_MY2021_Tx" SG_ 1049 SelDrvMdeCnfm_D_Stat2 1;
BA_ "U_T6_MCA_MY2020_Tx" SG_ 1049 SelDrvMdeCnfm_D_Stat2 1;
BA_ "GenSigSendType" SG_ 1049 SelDrvMdeCnfm_D_Stat2 3;
BA_ "U_CD764_MY2022_Tx" SG_ 1049 SelDrvMde_D_RqDrv 1;
BA_ "U_U55X_MY2022_Tx" SG_ 1049 SelDrvMde_D_RqDrv 1;
BA_ "U_CD542_MY2021_Tx" SG_ 1049 SelDrvMde_D_RqDrv 1;
BA_ "U_T6_MCA_MY2020_Tx" SG_ 1049 SelDrvMde_D_RqDrv 1;
BA_ "GenSigSendType" SG_ 1049 SelDrvMde_D_RqDrv 3;
BA_ "GenSigStartValue" SG_ 1049 SelDrvMde_D_RqDrv 31;
BA_ "U_CD764_MY2022_Tx" SG_ 584 AUDIO_RDISP2_WORD_Rx 1;
BA_ "U_U55X_MY2022_Tx" SG_ 584 AUDIO_RDISP2_WORD_Rx 1;
BA_ "U_T6_MCA_MY2020_Tx" SG_ 584 AUDIO_RDISP2_WORD_Rx 1;
BA_ "GenSigStartValue" SG_ 1052 AwdCnnct_D_Stat 1;
BA_ "GenSigStartValueInteger" SG_ 1052 AwdCnnct_D_Stat 1;
BA_ "U_CD764_MY2022_Rx" SG_ 1052 AwdLck_Tq_Actl 1;
BA_ "U_T6_MCA_MY2020_Rx" SG_ 1052 AwdLck_Tq_Actl 1;
BA_ "U_CD542_MY2021_Tx" SG_ 754 ACU_ActChimeTypeDat_St 1;
BA_ "U_T6_MCA_MY2020_Tx" SG_ 754 ACU_ActChimeTypeDat_St 1;
BA_ "U_P702_MY2021_Tx" SG_ 754 ACU_ActChimeTypeDat_St 1;
BA_ "U_CD764_MY2022_Rx" SG_ 754 ACU_ActChimeTypeDat_St 1;
BA_ "U_CD542_MY2021_Rx" SG_ 754 ACU_ActChimeTypeDat_St 1;
BA_ "U_T6_MCA_MY2020_Rx" SG_ 754 ACU_ActChimeTypeDat_St 1;
BA_ "U_P702_MY2021_Rx" SG_ 754 ACU_ActChimeTypeDat_St 1;
BA_ "U_CD542_MY2021_Tx" SG_ 754 ACU_ActChimeType_St 1;
BA_ "U_T6_MCA_MY2020_Tx" SG_ 754 ACU_ActChimeType_St 1;
BA_ "U_P702_MY2021_Tx" SG_ 754 ACU_ActChimeType_St 1;
BA_ "U_CD764_MY2022_Rx" SG_ 754 ACU_ActChimeType_St 1;
BA_ "U_CD542_MY2021_Rx" SG_ 754 ACU_ActChimeType_St 1;
BA_ "U_T6_MCA_MY2020_Rx" SG_ 754 ACU_ActChimeType_St 1;
BA_ "U_P702_MY2021_Rx" SG_ 754 ACU_ActChimeType_St 1;
BA_ "GenSigSendType" SG_ 754 ACU_ActChimeType_St 3;
BA_ "U_CD764_MY2022_Tx" SG_ 729 ACU_VoiceFBVolume_Up 1;
BA_ "U_U55X_MY2022_Tx" SG_ 729 ACU_VoiceFBVolume_Up 1;
BA_ "U_CD542_MY2021_Tx" SG_ 729 ACU_VoiceFBVolume_Up 1;
BA_ "U_T6_MCA_MY2020_Tx" SG_ 729 ACU_VoiceFBVolume_Up 1;
BA_ "U_P702_MY2021_Tx" SG_ 729 ACU_VoiceFBVolume_Up 1;
BA_ "U_P702_MY2021_Rx" SG_ 729 ACU_VoiceFBVolume_Up 1;
BA_ "U_CD764_MY2022_Rx" SG_ 729 ACU_VoiceFBVolume_Up 1;
BA_ "U_U55X_MY2022_Rx" SG_ 729 ACU_VoiceFBVolume_Up 1;
BA_ "U_CD542_MY2021_Rx" SG_ 729 ACU_VoiceFBVolume_Up 1;
BA_ "U_T6_MCA_MY2020_Rx" SG_ 729 ACU_VoiceFBVolume_Up 1;
BA_ "GenSigSendType" SG_ 729 ACU_VoiceFBVolume_Up 3;
BA_ "U_CD764_MY2022_Tx" SG_ 729 ACU_VoiceFBVolume_St 1;
BA_ "U_U55X_MY2022_Tx" SG_ 729 ACU_VoiceFBVolume_St 1;
BA_ "U_CD542_MY2021_Tx" SG_ 729 ACU_VoiceFBVolume_St 1;
BA_ "U_T6_MCA_MY2020_Tx" SG_ 729 ACU_VoiceFBVolume_St 1;
BA_ "U_P702_MY2021_Tx" SG_ 729 ACU_VoiceFBVolume_St 1;
BA_ "U_P702_MY2021_Rx" SG_ 729 ACU_VoiceFBVolume_St 1;
BA_ "U_CD764_MY2022_Rx" SG_ 729 ACU_VoiceFBVolume_St 1;
BA_ "U_U55X_MY2022_Rx" SG_ 729 ACU_VoiceFBVolume_St 1;
BA_ "U_CD542_MY2021_Rx" SG_ 729 ACU_VoiceFBVolume_St 1;
BA_ "U_T6_MCA_MY2020_Rx" SG_ 729 ACU_VoiceFBVolume_St 1;
BA_ "GenSigSendType" SG_ 729 ACU_VoiceFBVolume_St 3;
BA_ "U_CD764_MY2022_Tx" SG_ 729 ACU_Treble_St 1;
BA_ "U_U55X_MY2022_Tx" SG_ 729 ACU_Treble_St 1;
BA_ "U_CD542_MY2021_Tx" SG_ 729 ACU_Treble_St 1;
BA_ "U_T6_MCA_MY2020_Tx" SG_ 729 ACU_Treble_St 1;
BA_ "U_P702_MY2021_Tx" SG_ 729 ACU_Treble_St 1;
BA_ "U_P702_MY2021_Rx" SG_ 729 ACU_Treble_St 1;
BA_ "U_CD764_MY2022_Rx" SG_ 729 ACU_Treble_St 1;
BA_ "U_U55X_MY2022_Rx" SG_ 729 ACU_Treble_St 1;
BA_ "U_CD542_MY2021_Rx" SG_ 729 ACU_Treble_St 1;
BA_ "U_T6_MCA_MY2020_Rx" SG_ 729 ACU_Treble_St 1;
BA_ "GenSigSendType" SG_ 729 ACU_Treble_St 3;
BA_ "U_CD764_MY2022_Tx" SG_ 729 ACU_TAVolume_Up 1;
BA_ "U_U55X_MY2022_Tx" SG_ 729 ACU_TAVolume_Up 1;
BA_ "U_CD542_MY2021_Tx" SG_ 729 ACU_TAVolume_Up 1;
BA_ "U_T6_MCA_MY2020_Tx" SG_ 729 ACU_TAVolume_Up 1;
BA_ "U_P702_MY2021_Tx" SG_ 729 ACU_TAVolume_Up 1;
BA_ "U_P702_MY2021_Rx" SG_ 729 ACU_TAVolume_Up 1;
BA_ "U_CD764_MY2022_Rx" SG_ 729 ACU_TAVolume_Up 1;
BA_ "U_U55X_MY2022_Rx" SG_ 729 ACU_TAVolume_Up 1;
BA_ "U_CD542_MY2021_Rx" SG_ 729 ACU_TAVolume_Up 1;
BA_ "U_T6_MCA_MY2020_Rx" SG_ 729 ACU_TAVolume_Up 1;
BA_ "GenSigSendType" SG_ 729 ACU_TAVolume_Up 3;
BA_ "U_CD764_MY2022_Tx" SG_ 729 ACU_TAVolume_St 1;
BA_ "U_U55X_MY2022_Tx" SG_ 729 ACU_TAVolume_St 1;
BA_ "U_CD542_MY2021_Tx" SG_ 729 ACU_TAVolume_St 1;
BA_ "U_T6_MCA_MY2020_Tx" SG_ 729 ACU_TAVolume_St 1;
BA_ "U_P702_MY2021_Tx" SG_ 729 ACU_TAVolume_St 1;
BA_ "U_P702_MY2021_Rx" SG_ 729 ACU_TAVolume_St 1;
BA_ "U_CD764_MY2022_Rx" SG_ 729 ACU_TAVolume_St 1;
BA_ "U_U55X_MY2022_Rx" SG_ 729 ACU_TAVolume_St 1;
BA_ "U_CD542_MY2021_Rx" SG_ 729 ACU_TAVolume_St 1;
BA_ "U_T6_MCA_MY2020_Rx" SG_ 729 ACU_TAVolume_St 1;
BA_ "GenSigSendType" SG_ 729 ACU_TAVolume_St 3;
BA_ "U_CD764_MY2022_Tx" SG_ 729 ACU_Reg_St 1;
BA_ "U_U55X_MY2022_Tx" SG_ 729 ACU_Reg_St 1;
BA_ "U_CD542_MY2021_Tx" SG_ 729 ACU_Reg_St 1;
BA_ "U_T6_MCA_MY2020_Tx" SG_ 729 ACU_Reg_St 1;
BA_ "U_P702_MY2021_Tx" SG_ 729 ACU_Reg_St 1;
BA_ "U_U55X_MY2022_Rx" SG_ 729 ACU_Reg_St 1;
BA_ "U_CD542_MY2021_Rx" SG_ 729 ACU_Reg_St 1;
BA_ "U_T6_MCA_MY2020_Rx" SG_ 729 ACU_Reg_St 1;
BA_ "U_P702_MY2021_Rx" SG_ 729 ACU_Reg_St 1;
BA_ "GenSigSendType" SG_ 729 ACU_Reg_St 3;
BA_ "U_CD764_MY2022_Tx" SG_ 729 ACU_PhoneVolume_Up 1;
BA_ "U_U55X_MY2022_Tx" SG_ 729 ACU_PhoneVolume_Up 1;
BA_ "U_CD542_MY2021_Tx" SG_ 729 ACU_PhoneVolume_Up 1;
BA_ "U_T6_MCA_MY2020_Tx" SG_ 729 ACU_PhoneVolume_Up 1;
BA_ "U_P702_MY2021_Tx" SG_ 729 ACU_PhoneVolume_Up 1;
BA_ "U_P702_MY2021_Rx" SG_ 729 ACU_PhoneVolume_Up 1;
BA_ "U_CD764_MY2022_Rx" SG_ 729 ACU_PhoneVolume_Up 1;
BA_ "U_U55X_MY2022_Rx" SG_ 729 ACU_PhoneVolume_Up 1;
BA_ "U_CD542_MY2021_Rx" SG_ 729 ACU_PhoneVolume_Up 1;
BA_ "U_T6_MCA_MY2020_Rx" SG_ 729 ACU_PhoneVolume_Up 1;
BA_ "GenSigSendType" SG_ 729 ACU_PhoneVolume_Up 3;
BA_ "U_CD764_MY2022_Tx" SG_ 729 ACU_PhoneVolume_St 1;
BA_ "U_U55X_MY2022_Tx" SG_ 729 ACU_PhoneVolume_St 1;
BA_ "U_CD542_MY2021_Tx" SG_ 729 ACU_PhoneVolume_St 1;
BA_ "U_T6_MCA_MY2020_Tx" SG_ 729 ACU_PhoneVolume_St 1;
BA_ "U_P702_MY2021_Tx" SG_ 729 ACU_PhoneVolume_St 1;
BA_ "U_P702_MY2021_Rx" SG_ 729 ACU_PhoneVolume_St 1;
BA_ "U_CD764_MY2022_Rx" SG_ 729 ACU_PhoneVolume_St 1;
BA_ "U_U55X_MY2022_Rx" SG_ 729 ACU_PhoneVolume_St 1;
BA_ "U_CD542_MY2021_Rx" SG_ 729 ACU_PhoneVolume_St 1;
BA_ "U_T6_MCA_MY2020_Rx" SG_ 729 ACU_PhoneVolume_St 1;
BA_ "GenSigSendType" SG_ 729 ACU_PhoneVolume_St 3;
BA_ "U_CD764_MY2022_Tx" SG_ 729 ACU_NavCmdVolume_Up 1;
BA_ "U_U55X_MY2022_Tx" SG_ 729 ACU_NavCmdVolume_Up 1;
BA_ "U_CD542_MY2021_Tx" SG_ 729 ACU_NavCmdVolume_Up 1;
BA_ "U_T6_MCA_MY2020_Tx" SG_ 729 ACU_NavCmdVolume_Up 1;
BA_ "U_P702_MY2021_Tx" SG_ 729 ACU_NavCmdVolume_Up 1;
BA_ "U_P702_MY2021_Rx" SG_ 729 ACU_NavCmdVolume_Up 1;
BA_ "U_CD764_MY2022_Rx" SG_ 729 ACU_NavCmdVolume_Up 1;
BA_ "U_U55X_MY2022_Rx" SG_ 729 ACU_NavCmdVolume_Up 1;
BA_ "U_CD542_MY2021_Rx" SG_ 729 ACU_NavCmdVolume_Up 1;
BA_ "U_T6_MCA_MY2020_Rx" SG_ 729 ACU_NavCmdVolume_Up 1;
BA_ "GenSigSendType" SG_ 729 ACU_NavCmdVolume_Up 3;
BA_ "U_CD764_MY2022_Tx" SG_ 729 ACU_NavCmdVolume_St 1;
BA_ "U_U55X_MY2022_Tx" SG_ 729 ACU_NavCmdVolume_St 1;
BA_ "U_CD542_MY2021_Tx" SG_ 729 ACU_NavCmdVolume_St 1;
BA_ "U_T6_MCA_MY2020_Tx" SG_ 729 ACU_NavCmdVolume_St 1;
BA_ "U_P702_MY2021_Tx" SG_ 729 ACU_NavCmdVolume_St 1;
BA_ "U_P702_MY2021_Rx" SG_ 729 ACU_NavCmdVolume_St 1;
BA_ "U_CD764_MY2022_Rx" SG_ 729 ACU_NavCmdVolume_St 1;
BA_ "U_U55X_MY2022_Rx" SG_ 729 ACU_NavCmdVolume_St 1;
BA_ "U_CD542_MY2021_Rx" SG_ 729 ACU_NavCmdVolume_St 1;
BA_ "U_T6_MCA_MY2020_Rx" SG_ 729 ACU_NavCmdVolume_St 1;
BA_ "GenSigSendType" SG_ 729 ACU_NavCmdVolume_St 3;
BA_ "U_CD764_MY2022_Tx" SG_ 729 ACU_Fader_St 1;
BA_ "U_U55X_MY2022_Tx" SG_ 729 ACU_Fader_St 1;
BA_ "U_CD542_MY2021_Tx" SG_ 729 ACU_Fader_St 1;
BA_ "U_T6_MCA_MY2020_Tx" SG_ 729 ACU_Fader_St 1;
BA_ "U_P702_MY2021_Tx" SG_ 729 ACU_Fader_St 1;
BA_ "U_P702_MY2021_Rx" SG_ 729 ACU_Fader_St 1;
BA_ "U_CD764_MY2022_Rx" SG_ 729 ACU_Fader_St 1;
BA_ "U_U55X_MY2022_Rx" SG_ 729 ACU_Fader_St 1;
BA_ "U_CD542_MY2021_Rx" SG_ 729 ACU_Fader_St 1;
BA_ "U_T6_MCA_MY2020_Rx" SG_ 729 ACU_Fader_St 1;
BA_ "GenSigSendType" SG_ 729 ACU_Fader_St 3;
BA_ "U_CD764_MY2022_Tx" SG_ 729 ACU_DSPProgram_St 1;
BA_ "U_U55X_MY2022_Tx" SG_ 729 ACU_DSPProgram_St 1;
BA_ "U_CD542_MY2021_Tx" SG_ 729 ACU_DSPProgram_St 1;
BA_ "U_T6_MCA_MY2020_Tx" SG_ 729 ACU_DSPProgram_St 1;
BA_ "U_P702_MY2021_Tx" SG_ 729 ACU_DSPProgram_St 1;
BA_ "U_U55X_MY2022_Rx" SG_ 729 ACU_DSPProgram_St 1;
BA_ "U_CD542_MY2021_Rx" SG_ 729 ACU_DSPProgram_St 1;
BA_ "U_T6_MCA_MY2020_Rx" SG_ 729 ACU_DSPProgram_St 1;
BA_ "U_P702_MY2021_Rx" SG_ 729 ACU_DSPProgram_St 1;
BA_ "GenSigSendType" SG_ 729 ACU_DSPProgram_St 3;
BA_ "U_CD764_MY2022_Tx" SG_ 729 ACU_DSP_St 1;
BA_ "U_U55X_MY2022_Tx" SG_ 729 ACU_DSP_St 1;
BA_ "U_CD542_MY2021_Tx" SG_ 729 ACU_DSP_St 1;
BA_ "U_T6_MCA_MY2020_Tx" SG_ 729 ACU_DSP_St 1;
BA_ "U_P702_MY2021_Tx" SG_ 729 ACU_DSP_St 1;
BA_ "U_U55X_MY2022_Rx" SG_ 729 ACU_DSP_St 1;
BA_ "U_CD542_MY2021_Rx" SG_ 729 ACU_DSP_St 1;
BA_ "U_T6_MCA_MY2020_Rx" SG_ 729 ACU_DSP_St 1;
BA_ "U_P702_MY2021_Rx" SG_ 729 ACU_DSP_St 1;
BA_ "GenSigSendType" SG_ 729 ACU_DSP_St 3;
BA_ "U_CD764_MY2022_Tx" SG_ 729 ACU_Bass_St 1;
BA_ "U_U55X_MY2022_Tx" SG_ 729 ACU_Bass_St 1;
BA_ "U_CD542_MY2021_Tx" SG_ 729 ACU_Bass_St 1;
BA_ "U_T6_MCA_MY2020_Tx" SG_ 729 ACU_Bass_St 1;
BA_ "U_P702_MY2021_Tx" SG_ 729 ACU_Bass_St 1;
BA_ "U_U55X_MY2022_Rx" SG_ 729 ACU_Bass_St 1;
BA_ "U_CD542_MY2021_Rx" SG_ 729 ACU_Bass_St 1;
BA_ "U_T6_MCA_MY2020_Rx" SG_ 729 ACU_Bass_St 1;
BA_ "U_P702_MY2021_Rx" SG_ 729 ACU_Bass_St 1;
BA_ "GenSigSendType" SG_ 729 ACU_Bass_St 3;
BA_ "U_CD764_MY2022_Tx" SG_ 729 ACU_Balance_St 1;
BA_ "U_U55X_MY2022_Tx" SG_ 729 ACU_Balance_St 1;
BA_ "U_CD542_MY2021_Tx" SG_ 729 ACU_Balance_St 1;
BA_ "U_T6_MCA_MY2020_Tx" SG_ 729 ACU_Balance_St 1;
BA_ "U_P702_MY2021_Tx" SG_ 729 ACU_Balance_St 1;
BA_ "U_U55X_MY2022_Rx" SG_ 729 ACU_Balance_St 1;
BA_ "U_CD542_MY2021_Rx" SG_ 729 ACU_Balance_St 1;
BA_ "U_T6_MCA_MY2020_Rx" SG_ 729 ACU_Balance_St 1;
BA_ "U_P702_MY2021_Rx" SG_ 729 ACU_Balance_St 1;
BA_ "GenSigSendType" SG_ 729 ACU_Balance_St 3;
BA_ "U_CD764_MY2022_Tx" SG_ 729 ACU_AVC_St 1;
BA_ "U_U55X_MY2022_Tx" SG_ 729 ACU_AVC_St 1;
BA_ "U_CD542_MY2021_Tx" SG_ 729 ACU_AVC_St 1;
BA_ "U_T6_MCA_MY2020_Tx" SG_ 729 ACU_AVC_St 1;
BA_ "U_P702_MY2021_Tx" SG_ 729 ACU_AVC_St 1;
BA_ "U_U55X_MY2022_Rx" SG_ 729 ACU_AVC_St 1;
BA_ "U_CD542_MY2021_Rx" SG_ 729 ACU_AVC_St 1;
BA_ "U_T6_MCA_MY2020_Rx" SG_ 729 ACU_AVC_St 1;
BA_ "U_P702_MY2021_Rx" SG_ 729 ACU_AVC_St 1;
BA_ "GenSigSendType" SG_ 729 ACU_AVC_St 3;
BA_ "U_U55X_MY2022_Tx" SG_ 727 ACU_LoadEjectMode_St 1;
BA_ "U_CD542_MY2021_Tx" SG_ 727 ACU_LoadEjectMode_St 1;
BA_ "U_T6_MCA_MY2020_Tx" SG_ 727 ACU_LoadEjectMode_St 1;
BA_ "U_P702_MY2021_Tx" SG_ 727 ACU_LoadEjectMode_St 1;
BA_ "U_U55X_MY2022_Rx" SG_ 727 ACU_LoadEjectMode_St 1;
BA_ "U_CD542_MY2021_Rx" SG_ 727 ACU_LoadEjectMode_St 1;
BA_ "U_T6_MCA_MY2020_Rx" SG_ 727 ACU_LoadEjectMode_St 1;
BA_ "U_P702_MY2021_Rx" SG_ 727 ACU_LoadEjectMode_St 1;
BA_ "GenSigSendType" SG_ 727 ACU_LoadEjectMode_St 3;
BA_ "U_U55X_MY2022_Tx" SG_ 727 ACU_LoadEjectDisc_St 1;
BA_ "U_CD542_MY2021_Tx" SG_ 727 ACU_LoadEjectDisc_St 1;
BA_ "U_T6_MCA_MY2020_Tx" SG_ 727 ACU_LoadEjectDisc_St 1;
BA_ "U_P702_MY2021_Tx" SG_ 727 ACU_LoadEjectDisc_St 1;
BA_ "U_U55X_MY2022_Rx" SG_ 727 ACU_LoadEjectDisc_St 1;
BA_ "U_CD542_MY2021_Rx" SG_ 727 ACU_LoadEjectDisc_St 1;
BA_ "U_T6_MCA_MY2020_Rx" SG_ 727 ACU_LoadEjectDisc_St 1;
BA_ "U_P702_MY2021_Rx" SG_ 727 ACU_LoadEjectDisc_St 1;
BA_ "U_U55X_MY2022_Tx" SG_ 726 ACU_SelectedPTYCodes_St 1;
BA_ "U_CD542_MY2021_Tx" SG_ 726 ACU_SelectedPTYCodes_St 1;
BA_ "U_T6_MCA_MY2020_Tx" SG_ 726 ACU_SelectedPTYCodes_St 1;
BA_ "U_P702_MY2021_Tx" SG_ 726 ACU_SelectedPTYCodes_St 1;
BA_ "U_U55X_MY2022_Rx" SG_ 726 ACU_SelectedPTYCodes_St 1;
BA_ "U_CD542_MY2021_Rx" SG_ 726 ACU_SelectedPTYCodes_St 1;
BA_ "U_T6_MCA_MY2020_Rx" SG_ 726 ACU_SelectedPTYCodes_St 1;
BA_ "U_P702_MY2021_Rx" SG_ 726 ACU_SelectedPTYCodes_St 1;
BA_ "GenSigSendType" SG_ 726 ACU_SelectedPTYCodes_St 3;
BA_ "U_U55X_MY2022_Tx" SG_ 726 ACU_TAMode_St 1;
BA_ "U_CD542_MY2021_Tx" SG_ 726 ACU_TAMode_St 1;
BA_ "U_T6_MCA_MY2020_Tx" SG_ 726 ACU_TAMode_St 1;
BA_ "U_P702_MY2021_Tx" SG_ 726 ACU_TAMode_St 1;
BA_ "U_CD764_MY2022_Rx" SG_ 726 ACU_TAMode_St 1;
BA_ "U_U55X_MY2022_Rx" SG_ 726 ACU_TAMode_St 1;
BA_ "U_CD542_MY2021_Rx" SG_ 726 ACU_TAMode_St 1;
BA_ "U_T6_MCA_MY2020_Rx" SG_ 726 ACU_TAMode_St 1;
BA_ "U_P702_MY2021_Rx" SG_ 726 ACU_TAMode_St 1;
BA_ "GenSigSendType" SG_ 726 ACU_TAMode_St 3;
BA_ "U_U55X_MY2022_Tx" SG_ 726 ACU_NEWSMode_St 1;
BA_ "U_CD542_MY2021_Tx" SG_ 726 ACU_NEWSMode_St 1;
BA_ "U_T6_MCA_MY2020_Tx" SG_ 726 ACU_NEWSMode_St 1;
BA_ "U_P702_MY2021_Tx" SG_ 726 ACU_NEWSMode_St 1;
BA_ "U_CD764_MY2022_Rx" SG_ 726 ACU_NEWSMode_St 1;
BA_ "U_U55X_MY2022_Rx" SG_ 726 ACU_NEWSMode_St 1;
BA_ "U_CD542_MY2021_Rx" SG_ 726 ACU_NEWSMode_St 1;
BA_ "U_T6_MCA_MY2020_Rx" SG_ 726 ACU_NEWSMode_St 1;
BA_ "U_P702_MY2021_Rx" SG_ 726 ACU_NEWSMode_St 1;
BA_ "GenSigSendType" SG_ 726 ACU_NEWSMode_St 3;
BA_ "U_U55X_MY2022_Tx" SG_ 726 ACU_AFJump_St 1;
BA_ "U_CD542_MY2021_Tx" SG_ 726 ACU_AFJump_St 1;
BA_ "U_T6_MCA_MY2020_Tx" SG_ 726 ACU_AFJump_St 1;
BA_ "U_P702_MY2021_Tx" SG_ 726 ACU_AFJump_St 1;
BA_ "U_U55X_MY2022_Rx" SG_ 726 ACU_AFJump_St 1;
BA_ "U_CD542_MY2021_Rx" SG_ 726 ACU_AFJump_St 1;
BA_ "U_T6_MCA_MY2020_Rx" SG_ 726 ACU_AFJump_St 1;
BA_ "U_P702_MY2021_Rx" SG_ 726 ACU_AFJump_St 1;
BA_ "GenSigSendType" SG_ 726 ACU_AFJump_St 3;
BA_ "U_CD764_MY2022_Rx" SG_ 369 CrawlMdeActv_B_Stat 1;
BA_ "U_CD764_MY2022_Rx" SG_ 369 SeatWorkSrfc_B_Falt 1;
BA_ "U_CD542_MY2021_Rx" SG_ 369 SeatWorkSrfc_B_Falt 1;
BA_ "GenSigStartValue" SG_ 369 PrplWhlScnd_Tq_Cmd 2048;
BA_ "GenSigStartValueInteger" SG_ 369 PrplWhlScnd_Tq_Cmd 4;
BA_ "GenSigStartValue" SG_ 369 PrplWhlPrim_Tq_Cmd 2048;
BA_ "GenSigStartValueInteger" SG_ 369 PrplWhlPrim_Tq_Cmd 4;
BA_ "U_CD764_MY2022_Rx" SG_ 369 TrnIpcDsplyRng_D_Stat 1;
BA_ "U_U55X_MY2022_Rx" SG_ 369 TrnIpcDsplyRng_D_Stat 1;
BA_ "U_CD542_MY2021_Rx" SG_ 369 TrnIpcDsplyRng_D_Stat 1;
BA_ "U_T6_MCA_MY2020_Rx" SG_ 369 TrnIpcDsplyRng_D_Stat 1;
BA_ "U_P702_MY2021_Rx" SG_ 369 TrnIpcDsplyRng_D_Stat 1;
BA_ "U_CD764_MY2022_Rx" SG_ 369 TrnIpcDsplyGear_D_Actl 1;
BA_ "U_U55X_MY2022_Rx" SG_ 369 TrnIpcDsplyGear_D_Actl 1;
BA_ "U_CD542_MY2021_Rx" SG_ 369 TrnIpcDsplyGear_D_Actl 1;
BA_ "U_T6_MCA_MY2020_Rx" SG_ 369 TrnIpcDsplyGear_D_Actl 1;
BA_ "U_P702_MY2021_Rx" SG_ 369 TrnIpcDsplyGear_D_Actl 1;
BA_ "GenSigStartValue" SG_ 369 TrnIpcDsplyGear_D_Actl 15;
BA_ "GenSigStartValueInteger" SG_ 369 TrnIpcDsplyGear_D_Actl 15;
BA_ "U_CD764_MY2022_Rx" SG_ 369 TrnIpcDsplyMde_D_Stat 1;
BA_ "U_U55X_MY2022_Rx" SG_ 369 TrnIpcDsplyMde_D_Stat 1;
BA_ "U_CD542_MY2021_Rx" SG_ 369 TrnIpcDsplyMde_D_Stat 1;
BA_ "U_T6_MCA_MY2020_Rx" SG_ 369 TrnIpcDsplyMde_D_Stat 1;
BA_ "U_P702_MY2021_Rx" SG_ 369 TrnIpcDsplyMde_D_Stat 1;
BA_ "WakeupSignal" SG_ 369 TrnIpcDsplyMde_D_Stat 1;
BA_ "U_CD764_MY2022_Rx" SG_ 369 TrnIpcDsplyMde_D_Actl 1;
BA_ "U_U55X_MY2022_Rx" SG_ 369 TrnIpcDsplyMde_D_Actl 1;
BA_ "U_CD542_MY2021_Rx" SG_ 369 TrnIpcDsplyMde_D_Actl 1;
BA_ "U_T6_MCA_MY2020_Rx" SG_ 369 TrnIpcDsplyMde_D_Actl 1;
BA_ "U_P702_MY2021_Rx" SG_ 369 TrnIpcDsplyMde_D_Actl 1;
BA_ "WakeupSignal" SG_ 369 TrnIpcDsplyMde_D_Actl 1;
BA_ "U_CD764_MY2022_Rx" SG_ 369 TrnIpcDsplyGear_D_Stat 1;
BA_ "U_U55X_MY2022_Rx" SG_ 369 TrnIpcDsplyGear_D_Stat 1;
BA_ "U_CD542_MY2021_Rx" SG_ 369 TrnIpcDsplyGear_D_Stat 1;
BA_ "U_T6_MCA_MY2020_Rx" SG_ 369 TrnIpcDsplyGear_D_Stat 1;
BA_ "U_P702_MY2021_Rx" SG_ 369 TrnIpcDsplyGear_D_Stat 1;
BA_ "U_CD764_MY2022_Rx" SG_ 369 TrnIpcDsplyRng2_D_Actl 1;
BA_ "U_U55X_MY2022_Rx" SG_ 369 TrnIpcDsplyRng2_D_Actl 1;
BA_ "U_CD542_MY2021_Rx" SG_ 369 TrnIpcDsplyRng2_D_Actl 1;
BA_ "U_T6_MCA_MY2020_Rx" SG_ 369 TrnIpcDsplyRng2_D_Actl 1;
BA_ "U_P702_MY2021_Rx" SG_ 369 TrnIpcDsplyRng2_D_Actl 1;
BA_ "GenSigStartValue" SG_ 369 TrnIpcDsplyRng2_D_Actl 15;
BA_ "GenSigStartValueInteger" SG_ 369 TrnIpcDsplyRng2_D_Actl 15;
BA_ "U_CD764_MY2022_Tx" SG_ 1832 TesterPhysicalResIPC 1;
BA_ "U_U55X_MY2022_Tx" SG_ 1832 TesterPhysicalResIPC 1;
BA_ "U_CD542_MY2021_Tx" SG_ 1832 TesterPhysicalResIPC 1;
BA_ "U_T6_MCA_MY2020_Tx" SG_ 1832 TesterPhysicalResIPC 1;
BA_ "U_P702_MY2021_Tx" SG_ 1832 TesterPhysicalResIPC 1;
BA_ "GenSigSendType" SG_ 1832 TesterPhysicalResIPC 3;
BA_ "U_CD764_MY2022_Rx" SG_ 1071 CluPdl_PcRate_Actl 1;
BA_ "U_CD542_MY2021_Rx" SG_ 1071 CluPdl_PcRate_Actl 1;
BA_ "U_T6_MCA_MY2020_Rx" SG_ 1071 CluPdl_PcRate_Actl 1;
BA_ "ContentDependant" SG_ 1071 CluPdl_PcRate_Actl 1;
BA_ "U_CD764_MY2022_Rx" SG_ 1071 CluPdlPosPcMeas_D_Qf 1;
BA_ "U_CD542_MY2021_Rx" SG_ 1071 CluPdlPosPcMeas_D_Qf 1;
BA_ "U_T6_MCA_MY2020_Rx" SG_ 1071 CluPdlPosPcMeas_D_Qf 1;
BA_ "GenSigStartValue" SG_ 1071 CluPdlPosPcMeas_D_Qf 1;
BA_ "MetaData" SG_ 1071 CluPdlPosPcMeas_D_Qf 1;
BA_ "ContentDependant" SG_ 1071 CluPdlPosPcMeas_D_Qf 1;
BA_ "GenSigStartValueInteger" SG_ 1071 CluPdlPosPcMeas_D_Qf 1;
BA_ "GenSigStartValue" SG_ 1071 EngMnfld3_P_Actl 254;
BA_ "GenSigStartValueInteger" SG_ 1071 EngMnfld3_P_Actl 254;
BA_ "U_CD764_MY2022_Rx" SG_ 1071 EngAout_N_Dsply 1;
BA_ "U_U55X_MY2022_Rx" SG_ 1071 EngAout_N_Dsply 1;
BA_ "U_CD542_MY2021_Rx" SG_ 1071 EngAout_N_Dsply 1;
BA_ "U_T6_MCA_MY2020_Rx" SG_ 1071 EngAout_N_Dsply 1;
BA_ "U_P702_MY2021_Rx" SG_ 1071 EngAout_N_Dsply 1;
BA_ "U_CD764_MY2022_Rx" SG_ 1071 CluPdlPos_Pc_Meas 1;
BA_ "U_CD542_MY2021_Rx" SG_ 1071 CluPdlPos_Pc_Meas 1;
BA_ "U_T6_MCA_MY2020_Rx" SG_ 1071 CluPdlPos_Pc_Meas 1;
BA_ "ContentDependant" SG_ 1071 CluPdlPos_Pc_Meas 1;
BA_ "ContentDependant" SG_ 1071 EngAoutIdl_N_Ntrl 1;
BA_ "U_CD764_MY2022_Tx" SG_ 848 RILStat 1;
BA_ "U_U55X_MY2022_Tx" SG_ 848 RILStat 1;
BA_ "U_CD542_MY2021_Tx" SG_ 848 RILStat 1;
BA_ "U_T6_MCA_MY2020_Tx" SG_ 848 RILStat 1;
BA_ "U_P702_MY2021_Tx" SG_ 848 RILStat 1;
BA_ "WakeupSignal" SG_ 513 ChrgStat_D3_Dsply 1;
BA_ "U_CD764_MY2022_Rx" SG_ 610 AwdLckWhlRr_Pc_RqDsply 1;
BA_ "U_U55X_MY2022_Rx" SG_ 610 AwdLckWhlRr_Pc_RqDsply 1;
BA_ "U_T6_MCA_MY2020_Rx" SG_ 610 AwdLckWhlRr_Pc_RqDsply 1;
BA_ "U_CD764_MY2022_Rx" SG_ 610 AwdLckWhlRl_Pc_RqDsply 1;
BA_ "U_U55X_MY2022_Rx" SG_ 610 AwdLckWhlRl_Pc_RqDsply 1;
BA_ "U_T6_MCA_MY2020_Rx" SG_ 610 AwdLckWhlRl_Pc_RqDsply 1;
BA_ "U_CD764_MY2022_Rx" SG_ 610 AwdLckWhlFr_Pc_RqDsply 1;
BA_ "U_U55X_MY2022_Rx" SG_ 610 AwdLckWhlFr_Pc_RqDsply 1;
BA_ "U_T6_MCA_MY2020_Rx" SG_ 610 AwdLckWhlFr_Pc_RqDsply 1;
BA_ "U_CD764_MY2022_Rx" SG_ 610 AwdLckWhlFl_Pc_RqDsply 1;
BA_ "U_U55X_MY2022_Rx" SG_ 610 AwdLckWhlFl_Pc_RqDsply 1;
BA_ "U_T6_MCA_MY2020_Rx" SG_ 610 AwdLckWhlFl_Pc_RqDsply 1;
VAL_ 531 VehStop_D_Stat 3 "Faulty" 2 "NoDataExists" 1 "Yes" 0 "No" ;
VAL_ 531 TracCtlPtActv_B_Actl 1 "Active" 0 "Inactive" ;
VAL_ 531 PrkBrkYwLamp_D_Rq 3 "Fast_Flash" 2 "Slow_Flash" 1 "On" 0 "Off" ;
VAL_ 531 PrkBrkRedLamp_D_Rq 3 "Fast_Flash" 2 "Slow_Flash" 1 "On" 0 "Off" ;
VAL_ 531 PrkBrkMsgTxt_D_Rq 15 "Message15" 14 "Message14" 13 "Message13" 12 "Message12" 11 "Message11" 10 "Message10" 9 "Message9" 8 "Message8" 7 "Message7" 6 "Message6" 5 "Message5" 4 "Message4" 3 "Message3" 2 "Message2" 1 "Message1" 0 "No_Message" ;
VAL_ 531 PrkBrkStatus 7 "GeneralFault_MaintenceMode" 6 "ECD_by_Brake_ECU_Active" 5 "EPB_Limphome_Active" 4 "Rear_Caliper_Open" 3 "RWU_By_EPB_Active" 2 "Rear_Caliper_Transition" 1 "Rear_Caliper_Closed" 0 "Not_Supported" ;
VAL_ 531 LscmbbMntr_B_Err 1 "DisplayMessage" 0 "NoMessage" ;
VAL_ 531 LscmbbBrkDis_B_Actl 1 "Yes" 0 "No" ;
VAL_ 531 StabCtlBrkActv_B_Actl 1 "Yes" 0 "No" ;
VAL_ 531 CmbbBrkPrchg_B_Actl 1 "Yes" 0 "No" ;
VAL_ 531 CmbbBrkDecel_B_Actl 1 "Yes" 0 "No" ;
VAL_ 531 CmbbBaSensInc_B_Actl 1 "Yes" 0 "No" ;
VAL_ 531 AccBrkWarm_B_Actl 1 "Yes" 0 "No" ;
VAL_ 531 AccBrkTotTqMn_B_Actl 1 "Yes" 0 "No" ;
VAL_ 531 AccBrkPrchgActv_B_Actl 1 "Yes" 0 "No" ;
VAL_ 531 AccBrkDis_B_Actl 1 "Yes" 0 "No" ;
VAL_ 531 AccBrkDeny_B_Actl 1 "Yes" 0 "No" ;
VAL_ 531 AccBrkActv_B_Actl 1 "Yes" 0 "No" ;
VAL_ 531 PrplDrgCtlActv_B_Actl 1 "Active" 0 "Inactive" ;
VAL_ 531 AbsActv_B_Actl 1 "Yes" 0 "No" ;
VAL_ 531 CmbbBrkDis_B_Actl 1 "Yes" 0 "No" ;
VAL_ 531 CmbbDeny_B_ActlBrk 1 "Yes" 0 "No" ;
VAL_ 531 CcDis_B_Cmd 1 "Yes" 0 "No" ;
VAL_ 531 VehLongOvrGnd_A_Est 1023 "Fault" 1022 "Unknown" ;
VAL_ 531 AccStopActv_B_ActlBrk 1 "Yes" 0 "No" ;
VAL_ 531 AccDis_B_ActlEpb 1 "Yes" 0 "No" ;
VAL_ 531 LscmbbDeny_B_ActlBrk 1 "Yes" 0 "No" ;
VAL_ 531 LscmbbBrkDecel_B_Actl 1 "Yes" 0 "No" ;
VAL_ 531 LscmbbBaSensInc_B_Actl 1 "Yes" 0 "No" ;
VAL_ 531 LscmbBrkPrchg_B_Actl 1 "Active" 0 "Inactive" ;
VAL_ 531 VehicleStationary 1 "Yes" 0 "No" ;
VAL_ 549 CCOI_PolicyClient_St2 15 "NotUsed_4" 14 "NotUsed_3" 13 "NotUsed_2" 12 "NotUsed_1" 11 "DataStorageError" 10 "StateMachineInconsistent" 9 "UnrecoverableSyncError" 8 "OnBoardSyncFailed" 7 "OnBoardImplemented" 6 "OnBoardSynchronized" 5 "OnBoardSynchronizing" 4 "OnBoardSyncNeeded" 3 "OffBoardUpdatePending" 2 "OnBoardUpdatePending" 1 "Waiting" 0 "Null" ;
VAL_ 549 FactoryReset_Rq2 1 "ResetFactoryDefaults" 0 "Inactive" ;
VAL_ 549 NavIod_D_Rq 7 "NotUsed_5" 6 "NotUsed_4" 5 "NotUsed_3" 4 "NotUsed_2" 3 "NotUsed_1" 2 "ModeChange" 1 "VideoOutput" 0 "NoRequest" ;
VAL_ 549 WwaActv_B_Stat 1 "Active" 0 "Inactive" ;
VAL_ 549 StrtInGearOk_D_Stat 3 "NotUsed" 2 "Accepted" 1 "NotAccepted" 0 "Null" ;
VAL_ 549 IPC_MyKeyVolLimit_St 0 "Invalid" 1 "Off" 2 "On" ;
VAL_ 549 HudVertSzMnuOn_B_Rq 1 "On" 0 "Off" ;
VAL_ 549 HudVertMnuOn_B_Rq 1 "Yes" 0 "No" ;
VAL_ 549 HudRotatMnuOn_B_Rq 1 "Yes" 0 "No" ;
VAL_ 549 HudCntntMnuOn_B_Rq 1 "On" 0 "Off" ;
VAL_ 549 HudBrightMnuOn_B_Rq 1 "Yes" 0 "No" ;
VAL_ 549 HdcOn_B_Rq 1 "On" 0 "Off" ;
VAL_ 549 IPC_Attn_Info_Audio 7 "Unknown" 6 "Attenuation_6" 5 "Attenuation_5" 4 "Attenuation_4" 3 "Attenuation_3" 2 "Attenuation_2" 1 "Attenuation_1" 0 "No_Attenuation_of_Audio" ;
VAL_ 549 BeltminderAudioMute 2 "On" 1 "Off" 0 "Invalid" ;
VAL_ 549 Power_Up_Chime_Modules 1 "Active" 0 "Inactive" ;
VAL_ 549 Chime_Source 2 "Cluster" 1 "Infotainment_Sys" 0 "Invalid" ;
VAL_ 549 IPC_New_Attn_Event 1 "Active" 0 "Inactive" ;
VAL_ 549 MetricActv_B_Dsply 1 "Active" 0 "Inactive" ;
VAL_ 765 BalrSwtch_D_Stat 3 "NotUsed" 2 "Pressed" 1 "NotPressed" 0 "Null" ;
VAL_ 765 BalrMde_D_Rq 3 "High" 2 "Medium" 1 "Low" 0 "Null" ;
VAL_ 765 RstrnOnPsngr_D_RqMnu 15 "Faulty" 14 "NotUsed_11" 13 "NotUsed_10" 12 "ConfiguredOff" 11 "NotUsed_9" 10 "On" 9 "NotUsed_8" 8 "NotUsed_7" 7 "NotUsed_6" 6 "NotUsed_5" 5 "Off" 4 "NotUsed_4" 3 "NotUsed_3" 2 "NotUsed_2" 1 "NotUsed_1" 0 "NoAction" ;
VAL_ 765 WaitToStartLamp_D_Falt 3 "NotUsed" 2 "Wait_to_start_lamp_failed" 1 "Diagnosis_not_ready" 0 "Wait_to_start_lamp_OK" ;
VAL_ 765 EsaOn_B_Rq 1 "On" 0 "Off" ;
VAL_ 765 BttOn_B_Rq 1 "On" 0 "Off" ;
VAL_ 765 Btt_L_Actl 127 "Faulty" 126 "NoDataExists" ;
VAL_ 765 RearDiffLck_D_RqArb 3 "Faulty" 2 "NotUsed" 1 "On" 0 "Off" ;
VAL_ 765 AwdMde_D_RqArb 7 "Faulty" 6 "NotUsed2" 5 "NoRequest" 4 "Neutral" 3 "FourByFourLow" 2 "FourByFourHigh" 1 "FourByFourAuto" 0 "FourByTwo" ;
VAL_ 765 SelDrvMdeTxtReset_B_Rq 1 "Yes" 0 "No" ;
VAL_ 765 AutoTowAllw_D_RqMnu 3 "TowHaulCommandedOn" 2 "AutoTowHaulEnabled" 1 "AutoTowHaulDisabled" 0 "NoSelection" ;
VAL_ 765 DrvInputRequired_B_Rq 1 "Yes" 0 "No" ;
VAL_ 765 SelDrvMdeDsply_B_Avail 1 "Available" 0 "NotAvailable" ;
VAL_ 765 EngExhMdeQuiet_D_Rq 3 "Faulty" 2 "QuietExhaust" 1 "LoudExhaust" 0 "Null" ;
VAL_ 765 AirSusp_D_RqDrv 3 "NotUsed" 2 "On" 1 "Off" 0 "NoModeSelected" ;
VAL_ 765 Mc_VehUntTrpCoUsrSel_St 0 "TripComputer_metric" 1 "TripComputer_imperial" ;
VAL_ 765 Mc_VehUnitTempUsrSel_St 0 "Temperature_deg_c" 1 "Temperature_deg_f" ;
VAL_ 765 Mc_VehDayNightUsrSel_St 2 "Night" 1 "Day" 0 "Invalid" ;
VAL_ 765 Mc_VehTimeFrmtUsrSel_St 2 "24h_mode" 1 "12h_mode" 0 "Invalid" ;
VAL_ 765 Mc_VehThemeUsrSel_St 2 "Theme_2" 1 "Theme_1" 0 "Invalid" ;
VAL_ 765 Mc_VehLangUsrSel_St 32 "Indian_English" 31 "Thai" 30 "Slovak" 29 "Arabic" 28 "Taiwanese" 27 "Mandarin_Chinese" 26 "Korean" 25 "AU_English" 24 "Japanese" 23 "Braz_Portuguese" 22 "EU_Portuguese" 21 "Finish" 20 "Norwegian" 19 "Danish" 18 "Swedish" 17 "Hungarian" 16 "Greek" 15 "Czech" 14 "Polish" 13 "Flemish" 12 "Dutch" 11 "Russian" 10 "Turkish" 9 "Mex_Spanish" 8 "EU_Spanish" 7 "Cana_French" 6 "EU_French" 5 "Italian" 4 "German" 3 "NA_English" 2 "UK_English" 1 "Unknown" 0 "Invalid" ;
VAL_ 765 AwdRnge_D_ActlIpc 7 "Unknown" 6 "High_Range_2wd" 5 "High_Range_Auto" 4 "High_Range_Locked" 3 "Neutral" 2 "Low_Range_2wd" 1 "Low_Range_Auto" 0 "Low_Range_Locked" ;
VAL_ 765 AwdDrvMde_D_Rq 7 "Faulty" 6 "NotAvailable" 5 "RockCrawl" 4 "Baja" 3 "MudAndSand" 2 "Weather" 1 "Sport" 0 "Normal" ;
VAL_ 765 EngExhMdeQuiet_D2_Rq 7 "NotUsed_3" 6 "NotUsed_2" 5 "NotUsed_1" 4 "Track" 3 "Sport" 2 "Normal" 1 "Stealth" 0 "Null" ;
VAL_ 765 BrkLineLck_D_Rq 3 "Off" 2 "Engage" 1 "Initiate" 0 "NoRequest" ;
VAL_ 765 EdmSailMde_B_RqDrv 1 "On" 0 "Off" ;
VAL_ 765 Running_Board_Cmd 3 "Unused" 2 "Manually_Deployed" 1 "All_Enabled" 0 "All_Disabled" ;
VAL_ 508 Mc_DB1GtInfNbrOfItms_Rq 1 "OneItem" 0 "Standard" ;
VAL_ 508 Mc_DB1GetInfSetConf_Rq 31 "UnknownActive" 30 "Reserved_last" 9 "Reserved" 8 "Podcast" 7 "Audiobook" 6 "Composer" 5 "Track" 4 "Genre" 3 "Album" 2 "Artist" 1 "Playlist" 0 "Root" ;
VAL_ 508 Mc_DB1GetInfSetFilt3_Rq 1023 "All" 1022 "SIIndex_1022" 1 "SIIndex_1" 0 "NotEngaged" ;
VAL_ 508 Mc_DB1GetInfSetFilt2_Rq 65535 "All" 65534 "SIIndex_65534" 1 "SIIndex_1" 0 "NotEngaged" ;
VAL_ 508 Mc_DB1GetInfSetFilt1_Rq 65535 "All" 65534 "SIIndex_65534" 1 "SIIndex_1" 0 "NotEngaged" ;
VAL_ 507 Mc_DB1SetTrkSetConf_Rq 9 "Reserved" 8 "Podcast" 7 "Audiobook" 6 "Composer" 5 "Track" 4 "Genre" 3 "Album" 2 "Artist" 1 "Playlist" 0 "Root" 31 "UnknownActive" 30 "Reserved_last" ;
VAL_ 507 Mc_DB1SetTrkSetFilt3_Rq 1023 "All" 1022 "SIIndex_1022" 1 "SIIndex_1" 0 "NotEngaged" ;
VAL_ 507 Mc_DB1SetTrkSetFilt2_Rq 65535 "All" 65534 "SIIndex_65534" 1 "SIIndex_1" 0 "NotEngaged" ;
VAL_ 507 Mc_DB1SetTrkSetFilt1_Rq 65535 "All" 65534 "SIIndex_65534" 1 "SIIndex_1" 0 "NotEngaged" ;
VAL_ 506 Mc_AudioSourceSel3_Rq 4 "Reserved" 5 "SDcard" 3 "USB" 2 "BTAudio" 1 "CD" 0 "Inactive" ;
VAL_ 505 Mc_AudioSourceSel2_Rq 4 "Reserved" 5 "SDcard" 3 "USB" 2 "BTAudio" 1 "CD" 0 "Inactive" ;
VAL_ 505 Mc_CutItem2_Rq 3 "Inactive" 2 "ThreeQuarterFromBeginOneQ" 1 "End" 0 "Beginning" ;
VAL_ 505 Mc_FolderContent_Rq 2 "Inactive" 1 "ReqContentParentFolderOf" 0 "ReqContentParameterFolder" ;
VAL_ 403 McLangSel2_Rq 32 "Indian_English" 31 "Thai" 30 "Slovak" 29 "Arabic" 28 "Taiwanese" 27 "Mandarin_Chinese" 26 "Korean" 25 "AU_English" 24 "Japanese" 23 "Braz_Portuguese" 22 "EU_Portuguese" 21 "Finish" 20 "Norwegian" 19 "Danish" 18 "Swedish" 17 "Hungarian" 16 "Greek" 15 "Czech" 14 "Polish" 13 "Flemish" 12 "Dutch" 11 "Russian" 10 "Turkish" 9 "Mex_Spanish" 8 "EU_Spanish" 7 "Cana_French" 6 "EU_French" 5 "Italian" 4 "German" 3 "NA_English" 2 "UK_English" 1 "Unknown" 0 "Invalid" ;
VAL_ 403 DealerCall_B_Rq 1 "Yes" 0 "Null" ;
VAL_ 403 Mc_RepeatGuidance_Rq 1 "Active" 0 "Inactive" ;
VAL_ 403 Mc_CancelRoute_Rq 1 "Cancel" 0 "Inactive" ;
VAL_ 403 Mc_CancelCurrWaypt_Rq 1 "Cancel" 0 "Inactive" ;
VAL_ 403 Mc_TextMessage_Rq 3 "Cancel" 2 "Ignore" 1 "Listen" 0 "Invalid" ;
VAL_ 403 Mc_BTInCallOptions_Rq 6 "EndHoldCall" 5 "HoldCall" 4 "GotoHandsfreeMode" 3 "GotoPrivacyMode" 2 "JoinCalls" 1 "SwitchCalls" 0 "Inactive" ;
VAL_ 403 Mc_PhMicrophoneMute_Rq 3 "Reserved" 2 "MicrophoneUnmute" 1 "MicrophoneMute" 0 "Inactive" ;
VAL_ 403 Mc_LangSel_Rq 31 "Thai" 30 "Slovak" 29 "Arabic" 28 "Taiwanese" 27 "Mandarin_Chinese" 26 "Korean" 25 "AU_English" 24 "Japanese" 23 "Braz_Portuguese" 22 "EU_Portuguese" 21 "Finish" 20 "Norwegian" 19 "Danish" 18 "Swedish" 17 "Hungarian" 16 "Greek" 15 "Czech" 14 "Polish" 13 "Flemish" 12 "Dutch" 11 "Russian" 10 "Turkish" 9 "Mex_Spanish" 8 "EU_Spanish" 7 "Cana_French" 6 "EU_French" 5 "Italian" 4 "German" 3 "NA_English" 2 "UK_English" 1 "Unknown" 0 "Invalid" ;
VAL_ 401 Bezel_Beeps_Rq 0 "Inactive" 2 "Disable" 1 "Enable" ;
VAL_ 401 Disp_VehUntTripCoUsrSel 3 "Inactive" 1 "Imperial" 0 "Metric" ;
VAL_ 401 Disp_VehUnitTempUsrSel 3 "Inactive" 1 "Fahrenheit" 0 "Celsius" ;
VAL_ 401 Disp_LangSel_Rq 31 "Thai" 30 "Slovak" 29 "Arabic" 28 "Taiwanese" 27 "Mandarin_Chinese" 26 "Korean" 25 "AU_English" 24 "Japanese" 23 "Braz_Portuguese" 22 "EU_Portuguese" 21 "Finish" 20 "Norwegian" 19 "Danish" 18 "Swedish" 17 "Hungarian" 16 "Greek" 15 "Czech" 14 "Polish" 13 "Flemish" 12 "Dutch" 11 "Russian" 10 "Turkish" 9 "Mex_Spanish" 8 "EU_Spanish" 7 "Cana_French" 6 "EU_French" 5 "Italian" 4 "German" 3 "NA_English" 2 "UK_English" 1 "Unknown" 0 "Invalid" ;
VAL_ 401 Disp_LangSel2_Rq 32 "Indian_English" 31 "Thai" 30 "Slovak" 29 "Arabic" 28 "Taiwanese" 27 "Mandarin_Chinese" 26 "Korean" 25 "AU_English" 24 "Japanese" 23 "Braz_Portuguese" 22 "EU_Portuguese" 21 "Finish" 20 "Norwegian" 19 "Danish" 18 "Swedish" 17 "Hungarian" 16 "Greek" 15 "Czech" 14 "Polish" 13 "Flemish" 12 "Dutch" 11 "Russian" 10 "Turkish" 9 "Mex_Spanish" 8 "EU_Spanish" 7 "Cana_French" 6 "EU_French" 5 "Italian" 4 "German" 3 "NA_English" 2 "UK_English" 1 "Unknown" 0 "Invalid" ;
VAL_ 1143 ConsTipUnitPt_D_Dsply 3 "NotUsed" 2 "FuelEconomy" 1 "Distance" 0 "Percentage" ;
VAL_ 1143 ConsTipTot_Pc_Dsply 1023 "Faulty" 1022 "NoDataExists" ;
VAL_ 1143 ChrgCompltMsgTxt_D_Rq 3 "NotUsed_1" 2 "ChargeToFull" 1 "ChargeToFastChargeLimit" 0 "DefaultLabel" ;
VAL_ 1142 ConsTipV_No_Dsply 1023 "Faulty" 1022 "NoDataExists" ;
VAL_ 1142 ConsTipMsg3_D_Dsply 15 "NotUsed10" 14 "NotUsed9" 13 "NotUsed8" 12 "NotUsed7" 11 "NotUsed6" 10 "NotUsed5" 9 "NotUsed4" 8 "NotUsed3" 7 "NotUsed2" 6 "NotUsed1" 5 "ReduceIdleTime" 4 "ClimateUsage" 3 "VehicleSpeed" 2 "Deceleration" 1 "Acceleration" 0 "NoDisplay" ;
VAL_ 1142 ConsTipMsg2_D_Dsply 15 "NotUsed10" 14 "NotUsed9" 13 "NotUsed8" 12 "NotUsed7" 11 "NotUsed6" 10 "NotUsed5" 9 "NotUsed4" 8 "NotUsed3" 7 "NotUsed2" 6 "NotUsed1" 5 "ReduceIdleTime" 4 "ClimateUsage" 3 "VehicleSpeed" 2 "Deceleration" 1 "Acceleration" 0 "NoDisplay" ;
VAL_ 1142 ConsTipMsg1_D_Dsply 15 "NotUsed10" 14 "NotUsed9" 13 "NotUsed8" 12 "NotUsed7" 11 "NotUsed6" 10 "NotUsed5" 9 "NotUsed4" 8 "NotUsed3" 7 "NotUsed2" 6 "NotUsed1" 5 "ReduceIdleTime" 4 "ClimateUsage" 3 "VehicleSpeed" 2 "Deceleration" 1 "Acceleration" 0 "NoDisplay" ;
VAL_ 1142 ConsTipDecel_No_Dsply 1023 "Faulty" 1022 "NoDataExists" ;
VAL_ 1142 ConsTipA_No_Dsply 1023 "Faulty" 1022 "NoDataExists" ;
VAL_ 947 Outside_Air_Temp_Stat_UB 1 "Fresh_data" 0 "Unchanged_data" ;
VAL_ 947 Outside_Air_Temp_Stat 255 "Invalid" 254 "Unknown" ;
VAL_ 973 PersCtaSplitView_D_Stat 3 "EnabledFull" 2 "Enabled_180SwitchOnly" 1 "Disabled" 0 "Null" ;
VAL_ 973 LaSysOffStat_D_Dsply 3 "Level_3" 2 "Level_2" 1 "Level_1" 0 "Level_0" ;
VAL_ 973 TsrVl1RstrcMsgTxt2_D_Rq 7 "NotUsed" 6 "Time" 5 "Trailer" 4 "Snow" 3 "RainWet" 2 "NoRecognizableRestrictn" 1 "NoSpeedLimitRestrictn" 0 "Null" ;
VAL_ 973 TsrVl2RstrcMsgTxt2_D_Rq 7 "NotUsed" 6 "Time" 5 "Trailer" 4 "Snow" 3 "RainWet" 2 "NoRecognizableRestrictn" 1 "NoSpeedLimitRestrictn" 0 "Null" ;
VAL_ 973 TsrVl2PrmntMsgTxt_D_Rq 3 "NotUsed" 2 "ShowPermanentlyWithSupp" 1 "ShowPermanentlyWithoutSupp" 0 "DoNotShowSignPermanent" ;
VAL_ 973 TsrVl1PrmntMsgTxt_D_Rq 3 "NotUsed" 2 "ShowPermanentlyWithSupp" 1 "ShowPermanentlyWithoutSupp" 0 "DoNotShowSignPermanent" ;
VAL_ 973 TsrOvtkMsgTxt2_D_Rq 15 "NotUsed5" 14 "NotUsed4" 13 "NotUsed3" 12 "NotUsed2" 11 "NotUsed1" 10 "LimForTrucksCancelled" 9 "LimForTrucksWoQlfdRstrc" 8 "LimForTrucksWithoutRstrc" 7 "LimAllCancelled" 6 "LimAllWithRstrcTime" 5 "LimAllWithRstrcTrailer" 4 "LimAllWithRstrcSnow" 3 "LimAllWithRstrcRain" 2 "LimAllWithoutQlfdRstrc" 1 "LimAllWithoutRestriction" 0 "OvertakingAllowed" ;
VAL_ 973 WwaWarn_B_Rq 1 "On" 0 "Off" ;
VAL_ 973 TsrVlUnitMsgTxt_D_Rq 3 "NoDataExists" 2 "Mph" 1 "Kph" 0 "Null" ;
VAL_ 973 TsrVLim2MsgTxt_D_Rq 255 "NoLimit" 254 "NotUsed2" 253 "NotUsed1" 252 "NotToBeDisplayed" 251 "LimitCancelled" 31 "1F_FA_Message31_250" 30 "Message30" 29 "Message29" 28 "Message28" 27 "Message27" 26 "Message26" 25 "Message25" 24 "Message24" 23 "Message23" 22 "Message22" 21 "Message21" 20 "Message20" 19 "Message19" 18 "Message18" 17 "Message17" 16 "Message16" 15 "Message15" 14 "Message14" 13 "Message13" 12 "Message12" 11 "Message11" 10 "Message10" 9 "Message9" 8 "Message8" 7 "Message7" 6 "Message6" 5 "Message5" 4 "Message4" 3 "Message3" 2 "Message2" 1 "Message1" 0 "Null" ;
VAL_ 973 TsrVLim1MsgTxt_D_Rq 255 "NoLimit" 254 "NotUsed2" 253 "NotUsed1" 252 "NotToBeDisplayed" 251 "LimitCancelled" 31 "1F_FA_Message31_250" 30 "Message30" 29 "Message29" 28 "Message28" 27 "Message27" 26 "Message26" 25 "Message25" 24 "Message24" 23 "Message23" 22 "Message22" 21 "Message21" 20 "Message20" 19 "Message19" 18 "Message18" 17 "Message17" 16 "Message16" 15 "Message15" 14 "Message14" 13 "Message13" 12 "Message12" 11 "Message11" 10 "Message10" 9 "Message9" 8 "Message8" 7 "Message7" 6 "Message6" 5 "Message5" 4 "Message4" 3 "Message3" 2 "Message2" 1 "Message1" 0 "Null" ;
VAL_ 973 TsrVl2StatMsgTxt_D_Rq 3 "LimitOutdated" 2 "LimitReiable" 1 "LimitChanged" 0 "Null" ;
VAL_ 973 TsrVl2RstrcMsgTxt_D_Rq 3 "NotUsed" 2 "NoRecognizableRestriction" 1 "NoSpeedLimitRestriction" 0 "Null" ;
VAL_ 973 TsrVl1StatMsgTxt_D_Rq 3 "LimitOutdated" 2 "LimitReiable" 1 "LimitChanged" 0 "Null" ;
VAL_ 973 TsrVl1RstrcMsgTxt_D_Rq 3 "NotUsed" 2 "NoRecognizableRestriction" 1 "NoSpeedLimitRestriction" 0 "Null" ;
VAL_ 973 TsrStatMsgTxt_D_Rq 7 "NotUsed" 6 "NoDataExists" 5 "TSR_Error" 4 "Available_NavigationOnly" 3 "Available_CameraOnly" 2 "Available_FusionMode" 1 "TSR_Off" 0 "Null" ;
VAL_ 973 TsrOvtkStatMsgTxt_D_Rq 3 "LimitOutdated" 2 "LimitReiable" 1 "LimitChanged" 0 "Null" ;
VAL_ 973 TsrOvtkMsgTxt_D_Rq 7 "LimForTrucksCancelled" 6 "LimForTrucksWoQlfdRstrc" 5 "LimForTrucksWithoutRstrc" 4 "LimAllCancelled" 3 "LimAllWithoutQlfdRstrc" 2 "LimAllWithoutRestriction" 1 "OvertakingAllowed" 0 "Null" ;
VAL_ 973 TsrOswWarnMsgTxt_D_Rq 3 "NotUsed" 2 "True" 1 "False" 0 "Null" ;
VAL_ 973 TsrMsgTxt_D_Rq 15 "NotUsed6" 14 "NotUsed5" 13 "NotUsed4" 12 "NotUsed3" 11 "NotUsed2" 10 "NotUsed1" 9 "RecgnzdSignNotUsblForDsply" 8 "LimitedSystemPerformance" 7 "OffRoad" 6 "RegionNotSupported" 5 "CountryNotSupported" 4 "WrngNavDatIncompDatCarrier" 3 "NoNavDataAvailable" 2 "NoNavAvailableSwitchedOff" 1 "NoInformationAllOK" 0 "Null" ;
VAL_ 756 AdjustableChimeVol2_Rq 15 "NotUsed_3" 14 "NotUsed_2" 13 "NotUsed_1" 12 "LevelPlus6" 11 "LevelPlus5" 10 "LevelPlus4" 9 "LevelPlus3" 8 "LevelPlus2" 7 "LevelPlus1" 6 "LevelMinus1" 5 "LevelMinus2" 4 "LevelMinus3" 3 "LevelMinus4" 2 "LevelMinus5" 1 "LevelMinus6" 0 "DefaultVolume" ;
VAL_ 756 Chime_Time_Criticality2 2 "Low" 1 "High" 0 "Inactive" ;
VAL_ 756 Chime_Occurence2 15 "Continuous" 14 "14Repititions" 13 "13Repititions" 12 "12Repititions" 11 "11Repititions" 10 "10Repititions" 9 "9Repititions" 8 "8Repititions" 7 "7Repititions" 6 "6Repititions" 5 "5Repititions" 4 "4Repititions" 3 "3Repititions" 2 "2Repititions" 1 "PlayOnce" 0 "Inactive" ;
VAL_ 756 Chime_Directionality2 3 "RearSpeakers" 2 "FrontSpeakers" 1 "ALL" 0 "Inactive" ;
VAL_ 756 Chime2Id_No_Rq 255 "Id255" 250 "Id250" 240 "Id240" 220 "Id220" 200 "Id200" 180 "Id180" 160 "Id160" 140 "Id140" 120 "Id120" 100 "Id100" 90 "Id90" 80 "Id80" 70 "Id70" 60 "Id60" 50 "Id50" 40 "Id40" 30 "Id30" 20 "Id20" 10 "Id10" 1 "Id1" 0 "Inactive" ;
VAL_ 544 ChimeId_No_Rq 255 "Id255" 250 "Id250" 240 "Id240" 220 "Id220" 200 "Id200" 180 "Id180" 160 "Id160" 140 "Id140" 120 "Id120" 100 "Id100" 90 "Id90" 80 "Id80" 70 "Id70" 60 "Id60" 50 "Id50" 40 "Id40" 30 "Id30" 20 "Id20" 10 "Id10" 1 "Id1" 0 "Inactive" ;
VAL_ 544 AdjustableChimeVol_Rq 15 "NotUsed_3" 14 "NotUsed_2" 13 "NotUsed_1" 12 "LevelPlus6" 11 "LevelPlus5" 10 "LevelPlus4" 9 "LevelPlus3" 8 "LevelPlus2" 7 "LevelPlus1" 6 "LevelMinus1" 5 "LevelMinus2" 4 "LevelMinus3" 3 "LevelMinus4" 2 "LevelMinus5" 1 "LevelMinus6" 0 "DefaultVolume" ;
VAL_ 544 Chime_Occurence 15 "Continuous" 14 "14Repititions" 13 "13Repititions" 12 "12Repititions" 11 "11Repititions" 10 "10Repititions" 9 "9Repititions" 8 "8Repititions" 7 "7Repititions" 6 "6Repititions" 5 "5Repititions" 4 "4Repititions" 3 "3Repititions" 2 "2Repititions" 1 "PlayOnce" 0 "Inactive" ;
VAL_ 544 Chime_Time_Criticality 2 "Low" 1 "High" 0 "Inactive" ;
VAL_ 544 Chime_Directionality 3 "RearSpeakers" 2 "FrontSpeakers" 1 "ALL" 0 "Inactive" ;
VAL_ 291 LangUpdate_Rsp 2 "Language_Not_Supported" 1 "Language_Updated" 0 "Inactive" ;
VAL_ 400 Mc_SetCurrStatMCCh_Rq 7 "MCChannel7" 6 "MCChannel6" 5 "MCChannel5" 4 "MCChannel4" 3 "MCChannel3" 2 "MCChannel2" 1 "MCChannel1" 0 "Inactive" ;
VAL_ 400 Mc_SetCurrentStatOp_Rq 0 "Inactive" 1 "SetCurrentFrequency" 2 "SetCurrentPiCode" 3 "SetCurrentStation" ;
VAL_ 400 Mc_PerTUPresetArea_Rq 13 "reserved" 12 "GetSAT3PresetData" 11 "GetSAT2PresetData" 15 "reserved_last" 10 "GetSAT1PresetData" 9 "GetDAB2PresetData" 8 "GetDAB1PresetData" 7 "GetDAB3PresetData" 6 "GetAmPresetData" 5 "GetAmAstPresetData" 4 "GetFmAstPresetData" 3 "GetFm3PresetData" 2 "GetFm2PresetData" 1 "GetFm1PresetData" 0 "Inactive" ;
VAL_ 647 HEC_BTIncomingCall_Rq 0 "Inactive" 1 "AcceptIncomingCall" 2 "DeclineIncomingCall" ;
VAL_ 647 HEC_BTEndTelService_Rq 1 "EndOngoingTelephonyCall" 0 "Inactive" ;
VAL_ 359 PrplWhlRgenMn_Tq_Actl 8191 "Faulty" ;
VAL_ 359 ElPw_D_StatStrtStop 15 "NotUsed6" 14 "NotUsed5" 13 "NotUsed4" 12 "NotUsed3" 11 "NotUsed2" 10 "NotUsed1" 9 "Supported_Level_4" 8 "Supported_Level_3" 7 "Supported_Level_2" 6 "Supported_Level_1" 5 "Limited_Support" 4 "Fault_Limited" 3 "LV_Event_in_Progress" 2 "Not_Supported_Imminent" 1 "Supported_All" 0 "Not_Supported" ;
VAL_ 359 PrplWhlTot2_Tq_Actl 65535 "Fault" 65534 "NoDataExists" ;
VAL_ 359 LscmbbDeny_B_ActlPrpl 1 "Denied" 0 "Allowed" ;
VAL_ 359 LscmbbEngTqMn_B_Actl 1 "Engine_Braking_Activated" 0 "Engine_Braking_Off" ;
VAL_ 359 PwPckTq_D_Stat 3 "PwPckOn_TqAvailable" 2 "StartInPrgrss_TqNotAvail" 1 "PwPckOn_TqNotAvailable" 0 "PwPckOff_TqNotAvailable" ;
VAL_ 359 Eng_D_Stat 3 "NotUsed" 2 "EngAutoStopped" 1 "EngOn" 0 "EngOff" ;
VAL_ 359 PlgActvArb_B_Actl 1 "On" 0 "Off" ;
VAL_ 359 ElPw_D_Stat 7 "NotUsed_3" 6 "NotUsed_2" 5 "NotUsed_1" 4 "Fault_Limited" 3 "LV_Event_In_Progress" 2 "Not_Supported_Imminent" 1 "Supported" 0 "Not_Supported" ;
VAL_ 359 TrnAinTq_D_Qf 3 "OK" 2 "Not_Within_Specifications" 1 "No_Data_Exists" 0 "Faulty" ;
VAL_ 990 PersIndexDdm_D_Actl 7 "Unused_3" 6 "Unused_2" 5 "Unused_1" 4 "Vehicle" 3 "PERS_4" 2 "PERS_3" 1 "PERS_2" 0 "PERS_1" ;
VAL_ 1246 TrlrBrkCtl2_B_Falt 1 "True" 0 "False" ;
VAL_ 890 ActvNseMute_D_Rq 3 "NotUsed" 2 "Mute" 1 "Unmute" 0 "Inactive" ;
VAL_ 890 ActvNseAudio_D_Stat 3 "Audio_Off" 2 "Audio_Active" 1 "Audio_Standby" 0 "Invalid" ;
VAL_ 890 ActvNse_B_Actv 1 "Active" 0 "Inactive" ;
VAL_ 261 ChrgStatDsply_D_Rq 3 "NotUsed_2" 2 "NotUsed_1" 1 "On" 0 "Off" ;
VAL_ 261 AudioToneTouchY_D_Rq 255 "Value254" 2 "Value1_up_to_0xFE_Value253" 1 "Value0" 0 "Null" ;
VAL_ 261 AudioToneTouchX_D_Rq 255 "Value254" 2 "Value1_up_to_0xFE_Value253" 1 "Value0" 0 "Null" ;
VAL_ 261 AudioToneTouch_D_Rq 3 "NotUsed" 2 "Enabled" 1 "Disabled" 0 "Null" ;
VAL_ 261 NextUsageTimeToggle_Rq 0 "Inactive" 2 "Disable" 1 "Enable" ;
VAL_ 261 LongTermParking_Rq 2 "On" 1 "Off" 0 "Inactive" ;
VAL_ 261 ModemReset_D_Rq 15 "NotUsed_11" 14 "NotUsed_10" 13 "NotUsed_9" 12 "NotUsed_8" 11 "NotUsed_7" 10 "NotUsed_6" 9 "NotUsed_5" 8 "NotUsed_4" 7 "NotUsed_3" 6 "BrandConnectReset2" 5 "BrandConnectReset1" 4 "CcsReset" 3 "OnlineTrafficReset" 2 "PaakReset" 1 "WifiHotspotReset" 0 "Null" ;
VAL_ 261 StopStrtDrvMde_B_RqBtn3 1 "Pressed" 0 "Not_Pressed" ;
VAL_ 261 TCU_ESN_D_Rq 3 "NotUsed" 2 "TCU_ESN_Request" 1 "NoRequest" 0 "Inactive" ;
VAL_ 261 FactoryReset_Rq 1 "ResetFactoryDefaults" 0 "Inactive" ;
VAL_ 261 OffPeakTimeSetType_Rq 4 "WeekendEnd" 3 "WeekendStart" 2 "WeekdayEnd" 1 "WeekdayStart" 0 "Inactive" ;
VAL_ 995 KeyAssocCmplt_B_Rq 1 "Yes" 0 "No" ;
VAL_ 995 FobAssocChime_B_Rq 1 "On" 0 "Off" ;
VAL_ 995 PersIndexBcm_D_Actl 7 "Unused_3" 6 "Unused_2" 5 "Unused_1" 4 "Vehicle" 3 "PERS_4" 2 "PERS_3" 1 "PERS_2" 0 "PERS_1" ;
VAL_ 995 LightAmbIntsty_No_Actl 0 "Off" ;
VAL_ 1000 AHU_Bezel_Diag_St 15 "Reserved" 6 "SignalStrength" 5 "SDARSESNNumber" 4 "SpeakerWalkAround" 3 "CalibrationPartNumber" 2 "HardwarePartNumber" 1 "SoftwarePartNumber" 0 "Inactive_NOP" ;
VAL_ 1000 ThermalReduction_St 15 "Reserved" 14 "_13dB_AudioReduction" 13 "_12dB_AudioReduction" 12 "_11dB_AudioReduction" 11 "_10dB_AudioReduction" 10 "_9dB_AudioReduction" 9 "_8dB_AudioReduction" 8 "_7dB_AudioReduction" 7 "_6dB_AudioReduction" 6 "_5dB_AudioReduction" 5 "_4dB_AudioReduction" 4 "_3dB_AudioReduction" 3 "_2dB_AudioReduction" 2 "_1dB_AudioReduction" 1 "NoAudioReduction" 0 "Null" ;
VAL_ 1000 AHU_Shaker_St 1 "Active" 0 "Inactive" ;
VAL_ 1000 ACM_BeltminderAudioSt 0 "Invalid" 1 "Off" 2 "On" ;
VAL_ 1000 MyKeyVolumeLimitUp 2 "NotUpdated" 1 "Updated" 0 "Invalid" ;
VAL_ 1000 MyKeyVolumeLimitMode 0 "Invalid" 1 "Off" 2 "On" ;
VAL_ 992 MsgCntrPersIndex_D_Rq 7 "Unused_3" 6 "Unused_2" 5 "Unused_1" 4 "Vehicle" 3 "PERS_4" 2 "PERS_3" 1 "PERS_2" 0 "PERS_1" ;
VAL_ 992 MsgCntrDsplyOp_D_Rq 7 "Unused_2" 6 "Unused_1" 5 "Copy" 4 "Restore" 3 "Upload" 2 "Set" 1 "Query" 0 "Null" ;
VAL_ 991 VehPayloadScrn_D_Stat 7 "CheckLoadScreenActive" 6 "WeightCarryScreenActive" 5 "GooseneckScreenActive" 4 "FifthWheelScreenActive" 3 "WeightDistScreenActive" 2 "AddMassEstScreenActive" 1 "PayloadEstScreenActive" 0 "ScaleScreenNotActive" ;
VAL_ 991 VehPayloadTireP_B_Stat 1 "Yes" 0 "No" ;
VAL_ 991 VehPayloadFlat_B_Stat 1 "Yes" 0 "No" ;
VAL_ 991 TrlrTngLoad_D_Stat 7 "Faulty" 6 "NoDataExists" 5 "NotUsed_3" 4 "NotUsed_2" 3 "NotUsed_1" 2 "AboveRange" 1 "InRange" 0 "BelowRange" ;
VAL_ 991 VehPayloadStew_B_Stat 1 "Yes" 0 "No" ;
VAL_ 991 VehPayloadTare_D_Stat 3 "Faulty" 2 "NotUsed" 1 "Request" 0 "NoRequest" ;
VAL_ 991 VehPayloadGear_B_Stat 1 "Yes" 0 "No" ;
VAL_ 991 VehFalr_D_Stat 7 "Faulty" 6 "NotUsed_3" 5 "NotUsed_2" 4 "NotUsed_1" 3 "HeightCorrectionCompleted" 2 "SecondMeasurementCollected" 1 "FirstMeasurementCollected" 0 "NotActive" ;
VAL_ 991 Trlr_M_Actl 2047 "Faulty" 2046 "NoDataExists" ;
VAL_ 991 PersIndexVdm_D_Actl 7 "Unused_3" 6 "Unused_2" 5 "Unused_1" 4 "Vehicle" 3 "PERS_4" 2 "PERS_3" 1 "PERS_2" 0 "PERS_1" ;
VAL_ 1004 TailLghtLoadMde_D_Stat 7 "Faulty" 6 "NotUsed_2" 5 "NotUsed_1" 4 "TailLightModeOverride" 3 "FalrModeActive" 2 "HitchLoadModeActive" 1 "PayloadModeActive" 0 "NoTailLightActive" ;
VAL_ 1004 PersRecallSrc_D_Actl 7 "NotUsed_3" 6 "NotUsed_2" 5 "NotUsed_1" 4 "MemorySwitch" 3 "RemoteStart" 2 "KeyFob" 1 "CenterStack" 0 "Null" ;
VAL_ 1004 Pers4Key_D_Stat 3 "NotUsed_1" 2 "KeyUnAssociated" 1 "KeyAssociated" 0 "Null" ;
VAL_ 1004 Pers3Key_D_Stat 3 "NotUsed_1" 2 "KeyUnAssociated" 1 "KeyAssociated" 0 "Null" ;
VAL_ 1004 Pers2Key_D_Stat 3 "NotUsed_1" 2 "KeyUnAssociated" 1 "KeyAssociated" 0 "Null" ;
VAL_ 1004 Pers1Key_D_Stat 3 "NotUsed_1" 2 "KeyUnAssociated" 1 "KeyAssociated" 0 "Null" ;
VAL_ 1004 EmPrflKeyAssoc_D_Stat 7 "WrongDevice" 6 "KeyAssociateFailed" 5 "KeyAssociateSuccess" 4 "KeyAlreadyInUse" 3 "KeyDisassociated" 2 "KeyAssociationExited" 1 "KeyAssociationEntered" 0 "Null" ;
VAL_ 1004 VehKeyActv_D_Stat 15 "NotUsed7" 14 "NotUsed6" 13 "NotUsed5" 12 "NotUsed4" 11 "NotUsed3" 10 "NotUsed2" 9 "NotUsed1" 8 "Key8Active" 7 "Key7Active" 6 "Key6Active" 5 "Key5Active" 4 "Key4Active" 3 "Key3Active" 2 "Key2Active" 1 "Key1Active" 0 "NoKeyActive" ;
VAL_ 1004 PersSetupRestr_D_Actl 3 "Non_Moveable_Person" 2 "Moveable_Person" 1 "Vehicle" 0 "Factory" ;
VAL_ 1004 PersSetupAccessCtrl 1 "Limited" 0 "Full" ;
VAL_ 1004 PersConflict_D_Actl 1 "Conflict" 0 "No_Conflict" ;
VAL_ 1004 AssocConfirm_D_Actl 0 "None" 7 "Associate" 6 "Keycode_Rejected" 5 "Keycode_Accepted" 4 "In_Progress" 3 "Erase" 2 "Duplicate" 1 "Disassociate" ;
VAL_ 1004 PersNoPos_D_Actl 7 "Unused_3" 6 "Unused_2" 5 "Unused_1" 4 "Vehicle" 3 "PERS_4" 2 "PERS_3" 1 "PERS_2" 0 "PERS_1" ;
VAL_ 1004 PersNo_D_Actl 7 "Unused_3" 6 "Unused_2" 5 "NotDetermined" 4 "Vehicle" 3 "PERS_4" 2 "PERS_3" 1 "PERS_2" 0 "PERS_1" ;
VAL_ 1004 EmPrflNo_D_Stat 7 "NotUsed_3" 6 "NotUsed_2" 5 "NotUsed_1" 4 "Pers4" 3 "Pers3" 2 "Pers2" 1 "Pers1" 0 "Null" ;
VAL_ 522 PtDrvMde_D_Stat_UB 1 "Fresh_data" 0 "Unchanged_data" ;
VAL_ 522 PtDrvMde_D_Stat 15 "Faulty" 14 "NotUsed11" 13 "NotUsed10" 12 "NotUsed9" 11 "NotUsed8" 10 "NotUsed7" 9 "NotUsed6" 8 "Track" 7 "Drag" 6 "Rock" 5 "Baja" 4 "Sand" 3 "TowHaulGradeAssist" 2 "SnowWet" 1 "Sport" 0 "Normal" ;
VAL_ 522 HsaStat_D_Dsply_UB 1 "Fresh_data" 0 "Unchanged_data" ;
VAL_ 522 HsaStat_D_Dsply 7 "NotUsed3" 6 "NotUsed2" 5 "NotUsed1" 4 "NotAvailable" 3 "SlowReleaseWithChime" 2 "SlowReleaseWithoutChime" 1 "Active" 0 "Inactive" ;
VAL_ 522 TrnAout_W_ActlUnfilt_UB 1 "Fresh_data" 0 "Unchanged_data" ;
VAL_ 522 TrnAout_W_ActlUnfilt 32767 "Fault" 32766 "Unknown" ;
VAL_ 522 UreaMnAdd_L_Actl_UB 1 "Fresh_data" 0 "Unchanged_data" ;
VAL_ 497 McEvntNotfnMsgId_D_Rq 3 "Deactivate" 2 "Update" 1 "Activate" 0 "Invalid" ;
VAL_ 497 McEvntNotfnChoice_D_Rq 7 "Choice7" 6 "Choice6" 5 "Choice5" 4 "Choice4" 3 "Choice3" 2 "Choice2" 1 "Choice1" 0 "Ok" ;
VAL_ 1049 PersTurnSglView_D_RqMnu 3 "NotUsed" 2 "Enable" 1 "Disable" 0 "Null" ;
VAL_ 1049 FrontDiffLck_D_RqDrv3 3 "Faulty" 2 "NoRequest" 1 "On" 0 "Off" ;
VAL_ 1049 RearDiffLck_D_RqDrv3 3 "Faulty" 2 "NoRequest" 1 "On" 0 "Off" ;
VAL_ 1049 TrailCtlSwtch_B_Stat4 1 "Pressed" 0 "Not_Pressed" ;
VAL_ 1049 CamraFrnt_B_RqMnu 1 "On" 0 "Off" ;
VAL_ 1049 StabBarCnncButtn_D_Sta3 3 "Faulty" 2 "NotUsed" 1 "Pressed" 0 "Not_Pressed" ;
VAL_ 1049 TurnAsstSwtch_D_Stat 3 "Faulty" 2 "NotUsed" 1 "Pressed" 0 "Not_Pressed" ;
VAL_ 1049 SelDrvMdeTxtRst_B_Rq2 1 "Yes" 0 "No" ;
VAL_ 1049 SelDrvMdePage_B_Stat 1 "Active" 0 "Inactive" ;
VAL_ 1049 SelDrvMdeCnfm_D_Stat2 3 "NotUsed" 2 "Accepted" 1 "NotAccepted" 0 "Null" ;
VAL_ 1049 SelDrvMde_D_RqDrv 31 "Faulty" 30 "SelDrvMde31" 29 "SelDrvMde30" 28 "SelDrvMde29" 27 "SelDrvMde28" 26 "SelDrvMde27" 25 "SelDrvMde26" 24 "SelDrvMde25" 23 "SelDrvMde24" 22 "SelDrvMde23" 21 "SelDrvMde22" 20 "SelDrvMde21" 19 "SelDrvMde20" 18 "SelDrvMde19" 17 "SelDrvMde18" 16 "SelDrvMde17" 15 "SelDrvMde16" 14 "SelDrvMde15" 13 "SelDrvMde14" 12 "SelDrvMde13" 11 "SelDrvMde12" 10 "SelDrvMde11" 9 "SelDrvMde10" 8 "SelDrvMde09" 7 "SelDrvMde08" 6 "SelDrvMde07" 5 "SelDrvMde06" 4 "SelDrvMde05" 3 "SelDrvMde04" 2 "SelDrvMde03" 1 "SelDrvMde02" 0 "SelDrvMde01" ;
VAL_ 1052 AwdDcnntSlipTrgt_B_Rq 1 "Request" 0 "NoRequest" ;
VAL_ 1052 AwdCnnct_D_Stat 3 "Connecting" 2 "Disconnecting" 1 "Connected" 0 "Disconnected" ;
VAL_ 1052 AwdRight_Tq_Rq 4095 "Fault" 4094 "Unknown" ;
VAL_ 1052 AwdRight_Tq_Est 4095 "Fault" 4094 "Unknown" ;
VAL_ 1052 AwdLeft_Tq_Rq 4095 "Fault" 4094 "Unknown" ;
VAL_ 1052 AwdLeft_Tq_Est 4095 "Fault" 4094 "Unknown" ;
VAL_ 1052 AwdLck_Tq_Actl 4095 "Fault" 4094 "Unknown" ;
VAL_ 1052 AwdLckTqNeg_B_Actl 1 "Active" 0 "Inactive" ;
VAL_ 754 ACU_ActChimeType_St 7 "Reserved4" 6 "Reserved3" 5 "Reserved2" 4 "Reserved1" 3 "Sample" 2 "Sine" 1 "No_Chime" 0 "Invalid" ;
VAL_ 729 ACU_VoiceFBVolume_Up 1 "Update" 0 "NoUpdate" ;
VAL_ 729 ACU_TAVolume_Up 1 "Update" 0 "NoUpdate" ;
VAL_ 729 ACU_Reg_St 0 "Invalid" 1 "Off" 2 "On" ;
VAL_ 729 ACU_PhoneVolume_Up 1 "Update" 0 "NoUpdate" ;
VAL_ 729 ACU_NavCmdVolume_Up 1 "Update" 0 "NoUpdate" ;
VAL_ 729 ACU_DSPProgram_St 7 "Reserved2" 6 "Reserved1" 5 "Voice" 4 "Rock" 0 "Invalid" 1 "Normal" 2 "Pop" 3 "Classical" ;
VAL_ 729 ACU_DSP_St 15 "Reserved" 9 "Convertible" 8 "RearSeats" 7 "FrontSeats" 0 "Invalid" 1 "All" 2 "Driver" 3 "Passenger" 4 "Reserved1" 5 "Reserved2" 6 "Reserved3" ;
VAL_ 727 ACU_LoadEjectMode_St 0 "Invalid" 1 "LoadModeInactiveDiscNumIgnored" 2 "LoadModeActiveDiscNumIgnored" 3 "PreparingToLoad" 4 "Insert" 5 "Loading" 6 "PreparingToEject" 7 "Ejecting" 8 "RemoveDisc" ;
VAL_ 727 ACU_LoadEjectDisc_St 0 "Invalid" 1 "Disc1" 2 "Disc2" 3 "Disc3" 4 "Disc4" 5 "Disc5" 6 "Disc6" 7 "All" ;
VAL_ 726 ACU_TAMode_St 0 "Invalid" 1 "TaLocalOn" 2 "TaDistantOn" 3 "TaOff" ;
VAL_ 726 ACU_NEWSMode_St 0 "Invalid" 1 "NewsOn" 2 "NewsOff" ;
VAL_ 726 ACU_AFJump_St 2 "Enabled" 1 "Inhibited" 0 "NoDataExists" ;
VAL_ 369 CrawlMdeActv_B_Stat 1 "On" 0 "Off" ;
VAL_ 369 DrvPerfMde_D_DsplyPt 3 "Sport" 2 "Normal" 1 "NotUsed" 0 "NoModeSelected" ;
VAL_ 369 SeatWorkSrfc_B_Falt 1 "Active" 0 "Inactive" ;
VAL_ 369 TrnIpcDsplyRng_D_Stat 3 "NotUsed" 2 "Flash" 1 "On" 0 "Blank_No_Display" ;
VAL_ 369 TrnIpcDsplyGear_D_Actl 15 "No_Gear_Selected" 14 "_14th_Gear" 13 "_13th_Gear" 12 "_12th_Gear" 11 "_11th_Gear" 10 "_10th_Gear" 9 "_9th_Gear" 8 "_8th_Gear" 7 "_7th_Gear" 6 "_6th_Gear" 5 "_5th_Gear" 4 "_4th_Gear" 3 "_3rd_Gear" 2 "_2nd_Gear" 1 "_1st_Gear" 0 "Neutral" ;
VAL_ 369 TrnIpcDsplyMde_D_Stat 3 "Reserved_Blank_No_Display" 2 "Flash" 1 "On" 0 "Blank_No_Display" ;
VAL_ 369 TrnIpcDsplyMde_D_Actl 7 "Manual_3" 6 "Manual_2" 5 "Manual_1_Low" 4 "Sport" 3 "Drive" 2 "Neutral" 1 "Reverse" 0 "Park" ;
VAL_ 369 TrnIpcDsplyGear_D_Stat 3 "Reserved_Blank_No_Display" 2 "Flash" 1 "On" 0 "Blank_No_Display" ;
VAL_ 369 TrnIpcDsplyRng2_D_Actl 15 "No_Range_Selected" 14 "Range_14" 13 "Range_13" 12 "Range_12" 11 "Range_11" 10 "Range_10" 9 "Range_9" 8 "Range_8" 7 "Range_7" 6 "Range_6" 5 "Range_5" 4 "Range_4" 3 "Range_3" 2 "Range_2" 1 "Range_1" 0 "NotUsed" ;
VAL_ 1071 CluPdlPosPcMeas_D_Qf 3 "OK" 2 "Not_Within_Specifications" 1 "No_Data_Exists" 0 "Faulty" ;
VAL_ 1071 EngMnfld3_P_Actl 255 "Faulty" 254 "NoDataExists" ;
VAL_ 848 RILStat 3 "Fault" 2 "Plant_Mode" 1 "On" 0 "Off" ;
VAL_ 891 CabnSndAmb2_Db_Actl 255 "Fault" ;
VAL_ 513 BattTracTeColr_D_Dsply 3 "NotUsed" 2 "ColorForSeverlyLimited" 1 "ColorForLimited" 0 "ColorForNormal" ;
VAL_ 513 MtrTracTeColr_D_Dsply 3 "NotUsed" 2 "ColorForSeverlyLimited" 1 "ColorForLimited" 0 "ColorForNormal" ;
